VERSION ""

NS_ :

BS_:

BU_: SCM BC1 BC2 ECM PSC ABS Brakes__Drive_Axle_1 EPS IC GPS WCM VCM Seat_Control_1 ISC1 HCU IDT GMRS XM RH AUTON LHC CIM IMU BC3 IC2 EPC1 EPC2 EPC3 EPC4 BMC1 BMC2 APU2 APU1 SRVTOOL RHC RCM

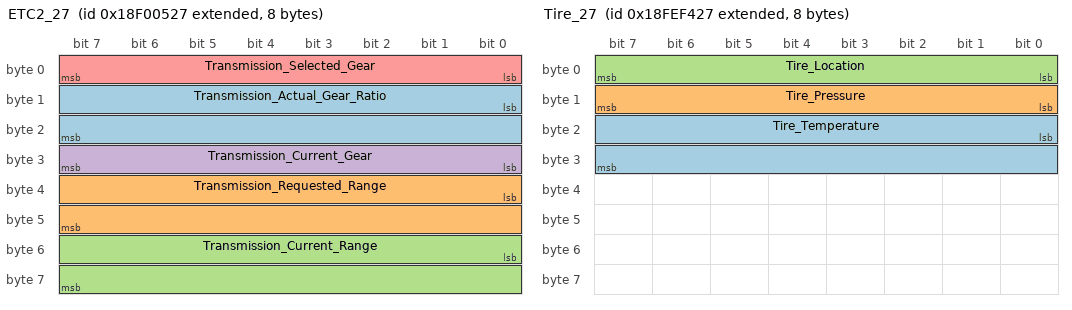
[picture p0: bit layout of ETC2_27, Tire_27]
BO_ 2565866791 ETC2_27: 8 VCM
 SG_ Transmission_Actual_Gear_Ratio : 8|16@1+ (0.001,0) [0|64.536] "Ratio" Vector__XXX
 SG_ Transmission_Requested_Range : 32|16@1+ (0,0) [0|-1] "ASCII" Vector__XXX
 SG_ Transmission_Current_Range : 48|16@1+ (0,0) [0|-1] "ASCII" Vector__XXX
 SG_ Transmission_Current_Gear : 24|8@1+ (1,-125) [-125|380] "gear_value" Vector__XXX
 SG_ Transmission_Selected_Gear : 0|8@1+ (1,-125) [-125|380] "gear_value" Vector__XXX

BO_ 2566834727 DM1_27: 42 VCM
 SG_ Flash_Malfunction_Indicator_Lamp : 14|2@1+ (1,0) [0|3] "" Vector__XXX
 SG_ Malfunction_Indicator_Lamp_Statu : 6|2@1+ (1,0) [0|3] "" Vector__XXX
 SG_ Red_Stop_Lamp_Status : 4|2@1+ (1,0) [0|3] "" Vector__XXX
 SG_ Amber_Warning_Lamp_Status : 2|2@1+ (1,0) [0|3] "" Vector__XXX
 SG_ Flash_Red_Stop_Lamp_RSL : 12|2@1+ (1,0) [0|3] "" Vector__XXX
 SG_ Flash_Amber_Warning_Lamp_AWL : 10|2@1+ (1,0) [0|3] "" Vector__XXX
 SG_ Flash_Protect_Lamp : 8|2@1+ (1,0) [0|3] "" Vector__XXX
 SG_ Protect_Lamp_Status : 0|2@1+ (1,0) [0|3] "" Vector__XXX
 SG_ DTC_1 : 16|32@1+ (1,0) [0|4294967295] "value" Vector__XXX
 SG_ DTC_2 : 48|32@1+ (1,0) [0|4294967295] "value" Vector__XXX
 SG_ DTC_3 : 80|32@1+ (1,0) [0|4294967295] "value" Vector__XXX
 SG_ DTC_4 : 112|32@1+ (1,0) [0|4294967295] "value" Vector__XXX
 SG_ DTC_5 : 144|32@1+ (1,0) [0|4294967295] "value" Vector__XXX
 SG_ DTC_6 : 176|32@1+ (1,0) [0|4294967295] "value" Vector__XXX
 SG_ DTC_7 : 208|32@1+ (1,0) [0|4294967295] "value" Vector__XXX
 SG_ DTC_8 : 240|32@1+ (1,0) [0|4294967295] "value" Vector__XXX
 SG_ DTC_9 : 272|32@1+ (1,0) [0|4294967295] "value" Vector__XXX
 SG_ DTC_10 : 304|32@1+ (1,0) [0|4294967295] "value" Vector__XXX

BO_ 2566845479 Tire_27: 8 VCM
 SG_ Tire_Temperature : 16|16@1+ (0.03125,-273) [-273|2320] "deg C" Vector__XXX
 SG_ Tire_Pressure : 8|8@1+ (4,0) [0|1023] "kPa" Vector__XXX
 SG_ Tire_Location : 0|8@1+ (1,0) [0|255] "bit" Vector__XXX

BO_ 2566844711 CCVS1_27: 8 VCM
 SG_ Cruise_Control_Set_Speed : 40|8@1+ (1,0) [0|255] "km/h" Vector__XXX
 SG_ Cruise_Control_Active : 24|2@1+ (1,0) [0|3] "bit" Vector__XXX
 SG_ Clutch_Switch : 30|2@1+ (1,0) [0|3] "bit" Vector__XXX
 SG_ Brake_Switch : 28|2@1+ (1,0) [0|3] "bit" Vector__XXX
 SG_ pCC_Message_Counter : 52|4@1+ (1,0) [0|15] "count" Vector__XXX
 SG_ Cruise_Control_Pause_Switch : 4|2@1+ (1,0) [0|3] "bit" Vector__XXX
 SG_ Cruise_Control_Set_Switch : 32|2@1+ (1,0) [0|3] "bit" Vector__XXX
 SG_ Two_Speed_Axle_Switch : 0|2@1+ (1,0) [0|3] "bit" Vector__XXX
 SG_ Cruise_Control_Enable_Switch : 26|2@1+ (1,0) [0|3] "bit" Vector__XXX
 SG_ pOdometer_Drive_Bit : 6|2@1+ (1,0) [0|3] "state" Vector__XXX
 SG_ pCC_Checksum : 56|8@1+ (1,0) [0|255] "" Vector__XXX
 SG_ WheelBased_Vehicle_Speed : 8|16@1+ (0.00390625,0) [0|255] "km/h" Vector__XXX
 SG_ Cruise_Control_Resume_Switch : 36|2@1+ (1,0) [0|3] "bit" Vector__XXX
 SG_ Cruise_Control_Accelerate_Switch : 38|2@1+ (1,0) [0|3] "bit" Vector__XXX
 SG_ pCruise_Enable_Status : 48|4@1+ (1,0) [0|15] "state" Vector__XXX
 SG_ Parking_Brake_Switch : 2|2@1+ (1,0) [0|3] "bit" Vector__XXX
 SG_ Cruise_Control_Coast_Decelerate_ : 34|2@1+ (1,0) [0|3] "bit" Vector__XXX

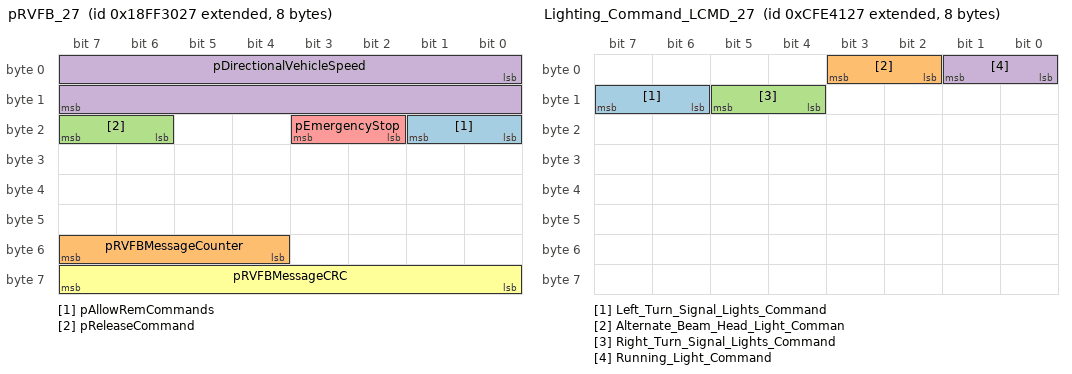
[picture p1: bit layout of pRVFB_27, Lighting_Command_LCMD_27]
BO_ 2566860839 pRVFB_27: 8 VCM
 SG_ pAllowRemCommands : 16|2@1+ (1,0) [0|3] "state" Vector__XXX
 SG_ pRVFBMessageCounter : 52|4@1+ (1,0) [0|15] "count" Vector__XXX
 SG_ pReleaseCommand : 22|2@1+ (1,0) [0|3] "state" Vector__XXX
 SG_ pDirectionalVehicleSpeed : 0|16@1+ (0.0078125,-128) [-128|639] "km/h" Vector__XXX
 SG_ pEmergencyStop : 18|2@1+ (1,0) [0|3] "state" Vector__XXX
 SG_ pRVFBMessageCRC : 56|8@1+ (1,0) [0|255] "" Vector__XXX

BO_ 2365473063 Lighting_Command_LCMD_27: 8 VCM
 SG_ Left_Turn_Signal_Lights_Command : 14|2@1+ (1,0) [0|3] "bit" Vector__XXX
 SG_ Alternate_Beam_Head_Light_Comman : 2|2@1+ (1,0) [0|3] "bit" Vector__XXX
 SG_ Right_Turn_Signal_Lights_Command : 12|2@1+ (1,0) [0|3] "bit" Vector__XXX
 SG_ Running_Light_Command : 0|2@1+ (1,0) [0|3] "bit" Vector__XXX

BO_ 2349465383 SRASI_27: 8 VCM
 SG_ Static_Roll_Angle : 0|8@1+ (1,-125) [-125|380] "deg" Vector__XXX

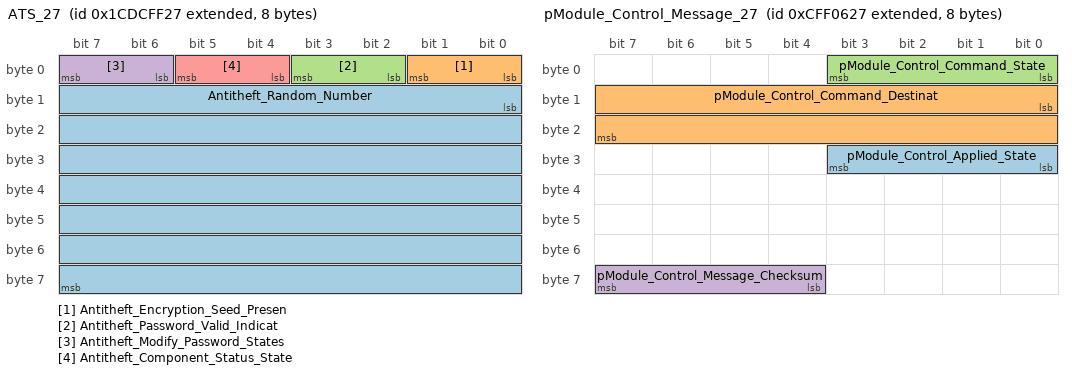
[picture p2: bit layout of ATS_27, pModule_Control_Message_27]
BO_ 2631728935 ATS_27: 8 VCM
 SG_ Antitheft_Random_Number : 8|56@1+ (0,0) [0|-1] "ASCII" Vector__XXX
 SG_ Antitheft_Encryption_Seed_Presen : 0|2@1+ (1,0) [0|3] "bit" Vector__XXX
 SG_ Antitheft_Password_Valid_Indicat : 2|2@1+ (1,0) [0|3] "bit" Vector__XXX
 SG_ Antitheft_Modify_Password_States : 6|2@1+ (1,0) [0|3] "bit" Vector__XXX
 SG_ Antitheft_Component_Status_State : 4|2@1+ (1,0) [0|3] "bit" Vector__XXX

BO_ 2633883431 FWD_27: 8 VCM
 SG_ Front_Wheel_Drive_Actuator_Statu : 0|2@1+ (1,0) [0|3] "bit" Vector__XXX

BO_ 2432656679 pOSS1_27: 8 VCM
 SG_ Key_Fob_Unlock_Button_Status : 30|2@1+ (1,0) [0|3] "state" Vector__XXX
 SG_ Homelink_2 : 44|2@1+ (1,0) [0|3] "state" Vector__XXX
 SG_ Side_Stand_Switch : 56|2@1+ (1,0) [0|3] "state" Vector__XXX
 SG_ Key_Fob_Lock_Button_Status : 32|2@1+ (1,0) [0|3] "state" Vector__XXX
 SG_ Windshield__2_Down : 50|2@1+ (1,0) [0|3] "state" Vector__XXX
 SG_ Turn__3_Cancel : 14|2@1+ (1,0) [0|3] "state" Vector__XXX
 SG_ Reverse : 40|2@1+ (1,0) [0|3] "state" Vector__XXX
 SG_ Hazard : 16|2@1+ (1,0) [0|3] "state" Vector__XXX
 SG_ Homelink_1 : 42|2@1+ (1,0) [0|3] "state" Vector__XXX
 SG_ Windshield__1_Up : 48|2@1+ (1,0) [0|3] "state" Vector__XXX
 SG_ Front_Brake_Switch : 52|2@1+ (1,0) [0|3] "state" Vector__XXX
 SG_ Instrument_Cluster_Control__2 : 2|2@1+ (1,0) [0|3] "state" Vector__XXX
 SG_ Chassis_Unlock_Button_Status : 34|2@1+ (1,0) [0|3] "state" Vector__XXX
 SG_ Power_Button : 58|2@1+ (1,0) [0|3] "state" Vector__XXX
 SG_ RunStop_Switch : 38|2@1+ (1,0) [0|3] "state" Vector__XXX
 SG_ Headlamp__2_High : 6|2@1+ (1,0) [0|3] "state" Vector__XXX
 SG_ Instrument_Cluster_Control__1 : 0|2@1+ (1,0) [0|3] "state" Vector__XXX
 SG_ Clutch_Switch : 54|2@1+ (1,0) [0|3] "state" Vector__XXX
 SG_ Start : 26|2@1+ (1,0) [0|3] "state" Vector__XXX
 SG_ Headlamp__3_Driving : 8|2@1+ (1,0) [0|3] "state" Vector__XXX
 SG_ Cruise__2_Set : 20|2@1+ (1,0) [0|3] "state" Vector__XXX
 SG_ Windshield_Wiper : 36|2@1+ (1,0) [0|3] "state" Vector__XXX
 SG_ Fog : 28|2@1+ (1,0) [0|3] "state" Vector__XXX
 SG_ Cruise__3_Accel : 22|2@1+ (1,0) [0|3] "state" Vector__XXX
 SG_ Horn : 24|2@1+ (1,0) [0|3] "state" Vector__XXX
 SG_ Turn__2_Right : 12|2@1+ (1,0) [0|3] "state" Vector__XXX
 SG_ Cruise__1_On : 18|2@1+ (1,0) [0|3] "state" Vector__XXX
 SG_ Turn__1_Left : 10|2@1+ (1,0) [0|3] "state" Vector__XXX
 SG_ Throttle_Safety_Switch__1 : 46|2@1+ (1,0) [0|3] "state" Vector__XXX
 SG_ Headlamp__1_Low : 4|2@1+ (1,0) [0|3] "state" Vector__XXX
 SG_ Chassis_Lock_Switch_Status : 62|2@1+ (1,0) [0|3] "unknown" Vector__XXX
 SG_ Fuel_Door_Unlock_Button_Status : 60|2@1+ (1,0) [0|3] "state" Vector__XXX

BO_ 2365523495 pModule_Control_Message_27: 8 VCM
 SG_ pModule_Control_Applied_State : 24|4@1+ (1,0) [0|15] "state" Vector__XXX
 SG_ pModule_Control_Command_Destinat : 8|16@1+ (1,0) [0|65535] "count" Vector__XXX
 SG_ pModule_Control_Command_State : 0|4@1+ (1,0) [0|15] "state" Vector__XXX
 SG_ pModule_Control_Message_Checksum : 60|4@1+ (1,0) [0|15] "bit" Vector__XXX

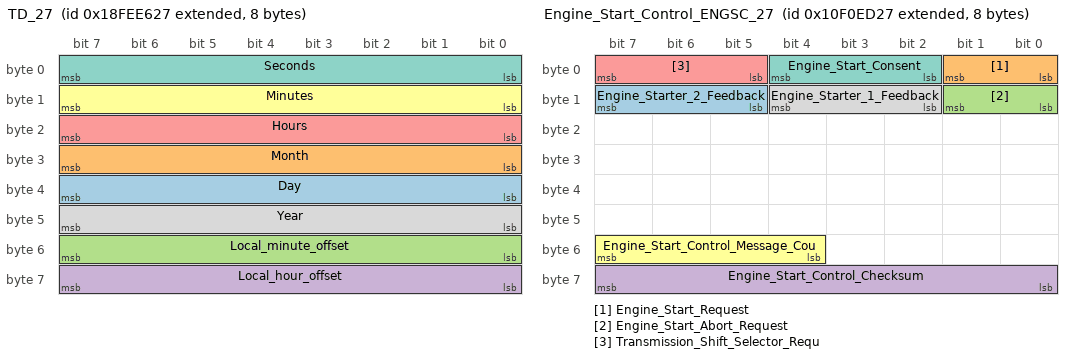
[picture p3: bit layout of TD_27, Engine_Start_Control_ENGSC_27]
BO_ 2566841895 TD_27: 8 VCM
 SG_ Day : 32|8@1+ (0.25,0) [0|63] "days" Vector__XXX
 SG_ Month : 24|8@1+ (1,0) [0|255] "months" Vector__XXX
 SG_ Local_minute_offset : 48|8@1+ (1,-125) [-125|380] "min" Vector__XXX
 SG_ Local_hour_offset : 56|8@1+ (1,-125) [-125|380] "h" Vector__XXX
 SG_ Hours : 16|8@1+ (1,0) [0|255] "h" Vector__XXX
 SG_ Minutes : 8|8@1+ (1,0) [0|255] "min" Vector__XXX
 SG_ Seconds : 0|8@1+ (0.25,0) [0|63] "s" Vector__XXX
 SG_ Year : 40|8@1+ (1,1985) [1985|-1730] "years" Vector__XXX

BO_ 2431708455 Engine_Start_Control_ENGSC_27: 8 VCM
 SG_ Engine_Starter_2_Feedback : 13|3@1+ (1,0) [0|7] "bit" Vector__XXX
 SG_ Engine_Start_Request : 0|2@1+ (1,0) [0|3] "bit" Vector__XXX
 SG_ Engine_Start_Abort_Request : 8|2@1+ (1,0) [0|3] "bit" Vector__XXX
 SG_ Engine_Start_Control_Checksum : 56|8@1+ (1,0) [0|255] "count" Vector__XXX
 SG_ Transmission_Shift_Selector_Requ : 5|3@1+ (1,0) [0|7] "bit" Vector__XXX
 SG_ Engine_Start_Control_Message_Cou : 52|4@1+ (1,0) [0|15] "bit" Vector__XXX
 SG_ Engine_Start_Consent : 2|3@1+ (1,0) [0|7] "bit" Vector__XXX
 SG_ Engine_Starter_1_Feedback : 10|3@1+ (1,0) [0|7] "bit" Vector__XXX

BO_ 2365531175 pVMC_27: 8 VCM
 SG_ pEPSReqMod : 8|8@1+ (1,0) [0|255] "state" Vector__XXX

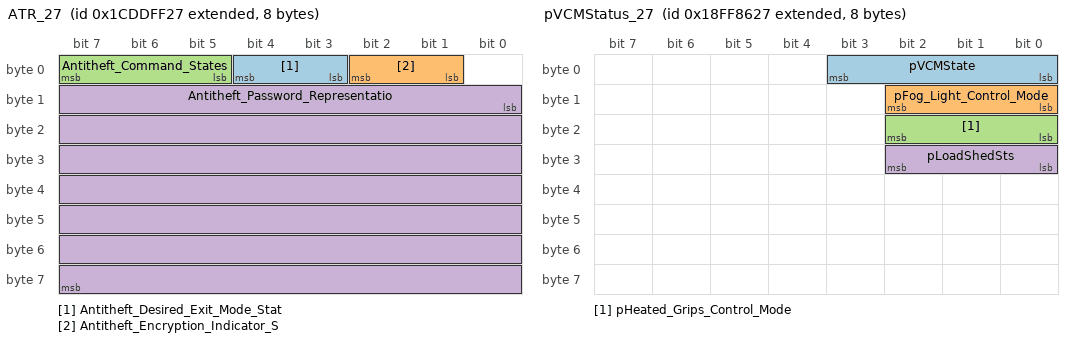
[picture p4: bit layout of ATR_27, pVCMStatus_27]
BO_ 2631794471 ATR_27: 8 VCM
 SG_ Antitheft_Desired_Exit_Mode_Stat : 3|2@1+ (1,0) [0|3] "bit" Vector__XXX
 SG_ Antitheft_Encryption_Indicator_S : 1|2@1+ (1,0) [0|3] "bit" Vector__XXX
 SG_ Antitheft_Command_States : 5|3@1+ (1,0) [0|7] "bit" Vector__XXX
 SG_ Antitheft_Password_Representatio : 8|56@1+ (0,0) [0|-1] "ASCII" Vector__XXX

BO_ 2566882855 pVCMStatus_27: 8 VCM
 SG_ pVCMState : 0|4@1+ (1,0) [0|15] "state" Vector__XXX
 SG_ pFog_Light_Control_Mode : 8|3@1+ (1,0) [0|7] "state" Vector__XXX
 SG_ pHeated_Grips_Control_Mode : 16|3@1+ (1,0) [0|7] "state" Vector__XXX
 SG_ pLoadShedSts : 24|3@1+ (1,0) [0|7] "state" Vector__XXX

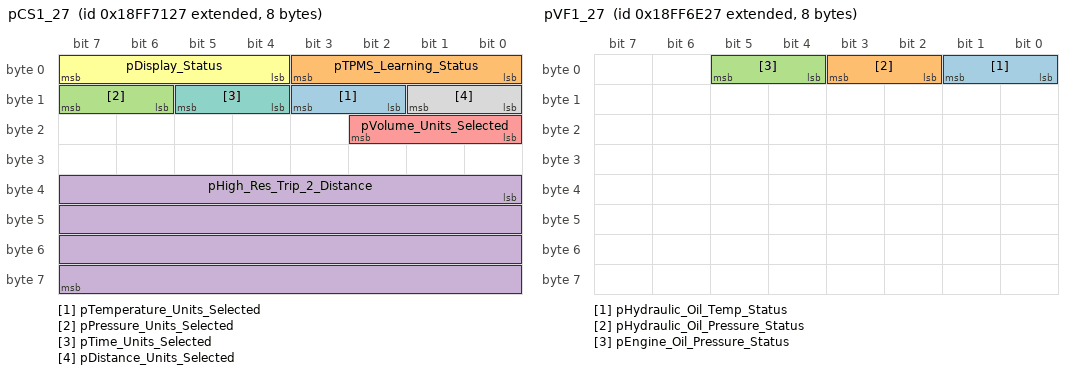
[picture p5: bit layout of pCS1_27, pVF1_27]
BO_ 2566877479 pCS1_27: 8 VCM
 SG_ pTemperature_Units_Selected : 10|2@1+ (1,0) [0|3] "state" Vector__XXX
 SG_ pTPMS_Learning_Status : 0|4@1+ (1,0) [0|15] "state" Vector__XXX
 SG_ pPressure_Units_Selected : 14|2@1+ (1,0) [0|3] "state" Vector__XXX
 SG_ pHigh_Res_Trip_2_Distance : 32|32@1+ (5,0) [0|21474836479] "km" Vector__XXX
 SG_ pVolume_Units_Selected : 16|3@1+ (1,0) [0|7] "state" Vector__XXX
 SG_ pDisplay_Status : 4|4@1+ (1,0) [0|15] "state" Vector__XXX
 SG_ pTime_Units_Selected : 12|2@1+ (1,0) [0|3] "state" Vector__XXX
 SG_ pDistance_Units_Selected : 8|2@1+ (1,0) [0|3] "state" Vector__XXX

BO_ 2633984551 pDSS_27: 8 VCM
 SG_ pHeated_Grip_Enable : 48|2@1+ (1,0) [0|3] "state" Vector__XXX
 SG_ pUser_PIN_Access_Status : 26|2@1+ (1,0) [0|3] "state" Vector__XXX
 SG_ pActive_Descent_Control_ADC_Stat : 0|2@1+ (1,0) [0|3] "state" Vector__XXX
 SG_ pCruise_Control_Set_Status : 24|2@1+ (1,0) [0|3] "state" Vector__XXX
 SG_ pTether_Switch_Status : 46|2@1+ (1,0) [0|3] "state" Vector__XXX
 SG_ pHigh_Beam_Indicator_Status : 8|2@1+ (1,0) [0|3] "state" Vector__XXX
 SG_ pLow_Fuel_Indicator_Status : 10|2@1+ (1,0) [0|3] "state" Vector__XXX
 SG_ pHeated_Grips_Percentage : 16|8@1+ (0.4,0) [0|101.4] "%" Vector__XXX
 SG_ pSide_Stand_Status : 36|2@1+ (1,0) [0|3] "state" Vector__XXX
 SG_ pTurf_Mode_Requested : 28|2@1+ (1,0) [0|3] "state" Vector__XXX
 SG_ pEngine_Idle_Shutdown_Timer : 54|10@1+ (1,0) [0|1023] "state" Vector__XXX
 SG_ Operator_Not_in_Operating_Statio : 38|2@1+ (1,0) [0|3] "state" Vector__XXX
 SG_ pAWD_Mode_Requested : 32|2@1+ (1,0) [0|3] "state" Vector__XXX
 SG_ pHeated_Grips_Up_Switch_Status : 50|2@1+ (1,0) [0|3] "state" Vector__XXX
 SG_ pTreadle_Neutral_Status : 2|2@1+ (1,0) [0|3] "state" Vector__XXX
 SG_ pHeated_Grips_Down_Switch_Status : 52|2@1+ (1,0) [0|3] "state" Vector__XXX
 SG_ pPark_Brake_Indicator_Status : 40|3@1+ (1,0) [0|7] "state" Vector__XXX
 SG_ pRWD_Mode_Requested : 30|2@1+ (1,0) [0|3] "state" Vector__XXX
 SG_ pSeat_Belt_Indicator_Status : 12|3@1+ (1,0) [0|7] "state" Vector__XXX
 SG_ pSecurity_Light_Immobilizer_Stat : 6|2@1+ (1,0) [0|3] "state" Vector__XXX
 SG_ ECU_Security_Status : 43|3@1+ (1,0) [0|7] "state" Vector__XXX
 SG_ pActive_Decent_Control_ADC_Mode_ : 34|2@1+ (1,0) [0|3] "state" Vector__XXX
 SG_ pTreadle_Reverse_Status : 4|2@1+ (1,0) [0|3] "state" Vector__XXX

BO_ 2566876711 pVF1_27: 8 VCM
 SG_ pHydraulic_Oil_Temp_Status : 0|2@1+ (1,0) [0|3] "state" Vector__XXX
 SG_ pHydraulic_Oil_Pressure_Status : 2|2@1+ (1,0) [0|3] "state" Vector__XXX
 SG_ pEngine_Oil_Pressure_Status : 4|2@1+ (1,0) [0|3] "state" Vector__XXX

BO_ 2566834735 DM1_2F: 42 SCM
 SG_ Flash_Malfunction_Indicator_Lamp : 14|2@1+ (1,0) [0|3] "" Vector__XXX
 SG_ Malfunction_Indicator_Lamp_Statu : 6|2@1+ (1,0) [0|3] "" Vector__XXX
 SG_ Red_Stop_Lamp_Status : 4|2@1+ (1,0) [0|3] "" Vector__XXX
 SG_ Amber_Warning_Lamp_Status : 2|2@1+ (1,0) [0|3] "" Vector__XXX
 SG_ Flash_Red_Stop_Lamp_RSL : 12|2@1+ (1,0) [0|3] "" Vector__XXX
 SG_ Flash_Amber_Warning_Lamp_AWL : 10|2@1+ (1,0) [0|3] "" Vector__XXX
 SG_ Flash_Protect_Lamp : 8|2@1+ (1,0) [0|3] "" Vector__XXX
 SG_ Protect_Lamp_Status : 0|2@1+ (1,0) [0|3] "" Vector__XXX
 SG_ DTC_1 : 16|32@1+ (1,0) [0|4294967295] "value" Vector__XXX
 SG_ DTC_2 : 48|32@1+ (1,0) [0|4294967295] "value" Vector__XXX
 SG_ DTC_3 : 80|32@1+ (1,0) [0|4294967295] "value" Vector__XXX
 SG_ DTC_4 : 112|32@1+ (1,0) [0|4294967295] "value" Vector__XXX
 SG_ DTC_5 : 144|32@1+ (1,0) [0|4294967295] "value" Vector__XXX
 SG_ DTC_6 : 176|32@1+ (1,0) [0|4294967295] "value" Vector__XXX
 SG_ DTC_7 : 208|32@1+ (1,0) [0|4294967295] "value" Vector__XXX
 SG_ DTC_8 : 240|32@1+ (1,0) [0|4294967295] "value" Vector__XXX
 SG_ DTC_9 : 272|32@1+ (1,0) [0|4294967295] "value" Vector__XXX
 SG_ DTC_10 : 304|32@1+ (1,0) [0|4294967295] "value" Vector__XXX

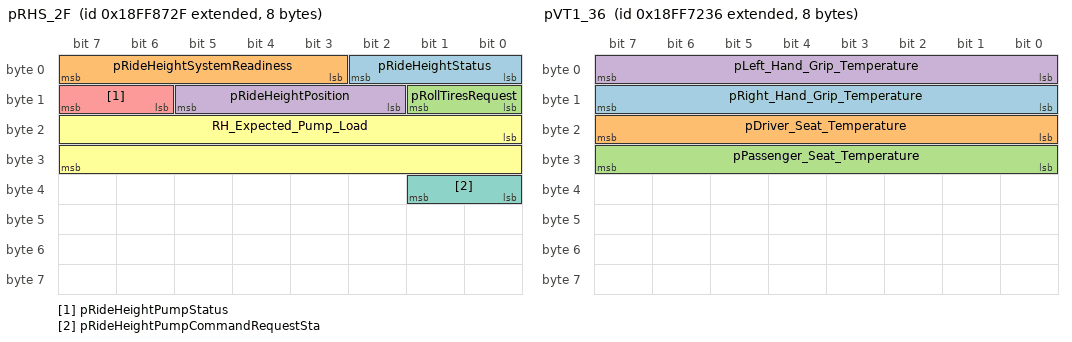
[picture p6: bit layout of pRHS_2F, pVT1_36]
BO_ 2566883119 pRHS_2F: 8 SCM
 SG_ pRideHeightStatus : 0|3@1+ (1,0) [0|7] "state" Vector__XXX
 SG_ pRideHeightSystemReadiness : 3|5@1+ (1,0) [0|31] "state" Vector__XXX
 SG_ pRollTiresRequest : 8|2@1+ (1,0) [0|3] "state" Vector__XXX
 SG_ pRideHeightPosition : 10|4@1+ (1,0) [0|15] "state" Vector__XXX
 SG_ pRideHeightPumpStatus : 14|2@1+ (1,0) [0|3] "state" Vector__XXX
 SG_ RH_Expected_Pump_Load : 16|16@1+ (1,0) [0|65535] "" Vector__XXX
 SG_ pRideHeightPumpCommandRequestSta : 32|2@1+ (1,0) [0|3] "state" Vector__XXX

BO_ 2566834742 DM1_36: 42 Seat_Control_1
 SG_ Flash_Malfunction_Indicator_Lamp : 14|2@1+ (1,0) [0|3] "" Vector__XXX
 SG_ Malfunction_Indicator_Lamp_Statu : 6|2@1+ (1,0) [0|3] "" Vector__XXX
 SG_ Red_Stop_Lamp_Status : 4|2@1+ (1,0) [0|3] "" Vector__XXX
 SG_ Amber_Warning_Lamp_Status : 2|2@1+ (1,0) [0|3] "" Vector__XXX
 SG_ Flash_Red_Stop_Lamp_RSL : 12|2@1+ (1,0) [0|3] "" Vector__XXX
 SG_ Flash_Amber_Warning_Lamp_AWL : 10|2@1+ (1,0) [0|3] "" Vector__XXX
 SG_ Flash_Protect_Lamp : 8|2@1+ (1,0) [0|3] "" Vector__XXX
 SG_ Protect_Lamp_Status : 0|2@1+ (1,0) [0|3] "" Vector__XXX
 SG_ DTC_1 : 16|32@1+ (1,0) [0|4294967295] "value" Vector__XXX
 SG_ DTC_2 : 48|32@1+ (1,0) [0|4294967295] "value" Vector__XXX
 SG_ DTC_3 : 80|32@1+ (1,0) [0|4294967295] "value" Vector__XXX
 SG_ DTC_4 : 112|32@1+ (1,0) [0|4294967295] "value" Vector__XXX
 SG_ DTC_5 : 144|32@1+ (1,0) [0|4294967295] "value" Vector__XXX
 SG_ DTC_6 : 176|32@1+ (1,0) [0|4294967295] "value" Vector__XXX
 SG_ DTC_7 : 208|32@1+ (1,0) [0|4294967295] "value" Vector__XXX
 SG_ DTC_8 : 240|32@1+ (1,0) [0|4294967295] "value" Vector__XXX
 SG_ DTC_9 : 272|32@1+ (1,0) [0|4294967295] "value" Vector__XXX
 SG_ DTC_10 : 304|32@1+ (1,0) [0|4294967295] "value" Vector__XXX

BO_ 2566877750 pVT1_36: 8 Seat_Control_1
 SG_ pRight_Hand_Grip_Temperature : 8|8@1+ (1,-40) [-40|295] "deg C" Vector__XXX
 SG_ pDriver_Seat_Temperature : 16|8@1+ (1,-40) [-40|295] "deg C" Vector__XXX
 SG_ pPassenger_Seat_Temperature : 24|8@1+ (1,-40) [-40|295] "deg C" Vector__XXX
 SG_ pLeft_Hand_Grip_Temperature : 0|8@1+ (1,-40) [-40|295] "deg C" Vector__XXX

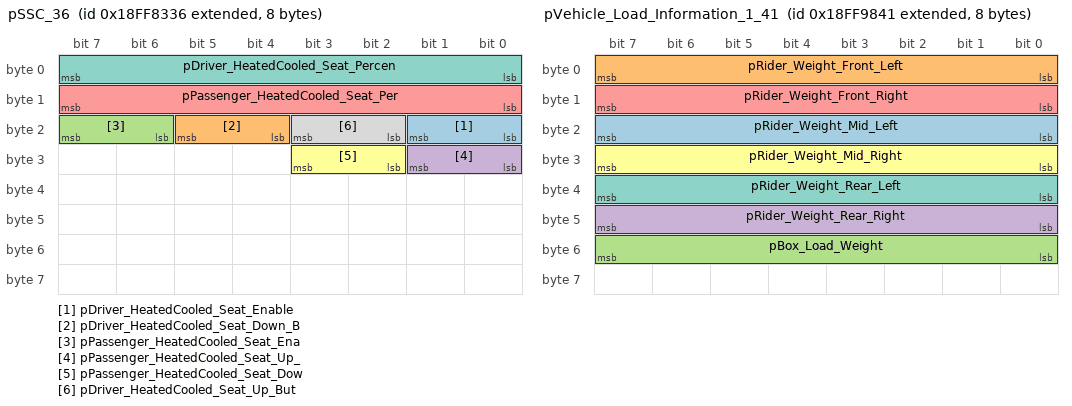
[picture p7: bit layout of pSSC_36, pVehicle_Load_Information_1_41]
BO_ 2566882102 pSSC_36: 8 Seat_Control_1
 SG_ pDriver_HeatedCooled_Seat_Enable : 16|2@1+ (1,0) [0|3] "state" Vector__XXX
 SG_ pDriver_HeatedCooled_Seat_Down_B : 20|2@1+ (1,0) [0|3] "state" Vector__XXX
 SG_ pPassenger_HeatedCooled_Seat_Ena : 22|2@1+ (1,0) [0|3] "state" Vector__XXX
 SG_ pPassenger_HeatedCooled_Seat_Up_ : 24|2@1+ (1,0) [0|3] "state" Vector__XXX
 SG_ pPassenger_HeatedCooled_Seat_Per : 8|8@1+ (0.8,-100) [-100|303.8] "%" Vector__XXX
 SG_ pPassenger_HeatedCooled_Seat_Dow : 26|2@1+ (1,0) [0|3] "state" Vector__XXX
 SG_ pDriver_HeatedCooled_Seat_Percen : 0|8@1+ (0.8,-100) [-100|303.8] "%" Vector__XXX
 SG_ pDriver_HeatedCooled_Seat_Up_But : 18|2@1+ (1,0) [0|3] "state" Vector__XXX

BO_ 2432658497 pOSS2_41: 8 ISC1
 SG_ pFOCC_Checksum : 56|8@1+ (1,0) [0|255] "" Vector__XXX
 SG_ Drive_Mode__4 : 6|2@1+ (1,0) [0|3] "state" Vector__XXX
 SG_ Drive_Mode__2 : 2|2@1+ (1,0) [0|3] "state" Vector__XXX
 SG_ pFOCC_Message_Counter : 48|4@1+ (1,0) [0|15] "" Vector__XXX
 SG_ Drivers_Net_Engagement : 12|2@1+ (1,0) [0|3] "state" Vector__XXX
 SG_ Foot_On_Cruise_Control_Switch : 22|2@1+ (1,0) [0|3] "state" Vector__XXX
 SG_ Drive_Mode__1 : 0|2@1+ (1,0) [0|3] "state" Vector__XXX
 SG_ Momentary_Driveline_Left_Press : 24|2@1+ (1,0) [0|3] "state" Vector__XXX
 SG_ CylDeAc_Enable : 32|2@1+ (1,0) [0|3] "state" Vector__XXX
 SG_ Work_Group_Lock_Switch : 16|2@1+ (1,0) [0|3] "state" Vector__XXX
 SG_ Drivers_Seatbelt_Engagement : 10|2@1+ (1,0) [0|3] "state" Vector__XXX
 SG_ Drive_Mode__3 : 4|2@1+ (1,0) [0|3] "state" Vector__XXX
 SG_ Work_Mode_Switch : 20|2@1+ (1,0) [0|3] "state" Vector__XXX
 SG_ Momentary_Driveline_Right_Press : 26|2@1+ (1,0) [0|3] "state" Vector__XXX
 SG_ PTO_Mode_Switch_RPM_Control : 8|2@1+ (1,0) [0|3] "state" Vector__XXX
 SG_ Operator_Presence_Switch : 18|2@1+ (1,0) [0|3] "state" Vector__XXX
 SG_ Tilt_Lock_Switch : 14|2@1+ (1,0) [0|3] "state" Vector__XXX
 SG_ Engine_Brake_Enable : 34|2@1+ (1,0) [0|3] "state" Vector__XXX
 SG_ Accessory_Relay : 28|2@1+ (1,0) [0|3] "state" Vector__XXX

BO_ 2566887489 pVehicle_Load_Information_1_41: 8 ISC1
 SG_ pRider_Weight_Mid_Left : 16|8@1+ (1,0) [0|255] "kg" Vector__XXX
 SG_ pRider_Weight_Front_Left : 0|8@1+ (1,0) [0|255] "kg" Vector__XXX
 SG_ pBox_Load_Weight : 48|8@1+ (10,0) [0|2559] "kg" Vector__XXX
 SG_ pRider_Weight_Rear_Right : 40|8@1+ (1,0) [0|255] "kg" Vector__XXX
 SG_ pRider_Weight_Front_Right : 8|8@1+ (1,0) [0|255] "kg" Vector__XXX
 SG_ pRider_Weight_Mid_Right : 24|8@1+ (1,0) [0|255] "kg" Vector__XXX
 SG_ pRider_Weight_Rear_Left : 32|8@1+ (1,0) [0|255] "kg" Vector__XXX

BO_ 2566834753 DM1_41: 42 ISC1
 SG_ Flash_Malfunction_Indicator_Lamp : 14|2@1+ (1,0) [0|3] "" Vector__XXX
 SG_ Malfunction_Indicator_Lamp_Statu : 6|2@1+ (1,0) [0|3] "" Vector__XXX
 SG_ Red_Stop_Lamp_Status : 4|2@1+ (1,0) [0|3] "" Vector__XXX
 SG_ Amber_Warning_Lamp_Status : 2|2@1+ (1,0) [0|3] "" Vector__XXX
 SG_ Flash_Red_Stop_Lamp_RSL : 12|2@1+ (1,0) [0|3] "" Vector__XXX
 SG_ Flash_Amber_Warning_Lamp_AWL : 10|2@1+ (1,0) [0|3] "" Vector__XXX
 SG_ Flash_Protect_Lamp : 8|2@1+ (1,0) [0|3] "" Vector__XXX
 SG_ Protect_Lamp_Status : 0|2@1+ (1,0) [0|3] "" Vector__XXX
 SG_ DTC_1 : 16|32@1+ (1,0) [0|4294967295] "value" Vector__XXX
 SG_ DTC_2 : 48|32@1+ (1,0) [0|4294967295] "value" Vector__XXX
 SG_ DTC_3 : 80|32@1+ (1,0) [0|4294967295] "value" Vector__XXX
 SG_ DTC_4 : 112|32@1+ (1,0) [0|4294967295] "value" Vector__XXX
 SG_ DTC_5 : 144|32@1+ (1,0) [0|4294967295] "value" Vector__XXX
 SG_ DTC_6 : 176|32@1+ (1,0) [0|4294967295] "value" Vector__XXX
 SG_ DTC_7 : 208|32@1+ (1,0) [0|4294967295] "value" Vector__XXX
 SG_ DTC_8 : 240|32@1+ (1,0) [0|4294967295] "value" Vector__XXX
 SG_ DTC_9 : 272|32@1+ (1,0) [0|4294967295] "value" Vector__XXX
 SG_ DTC_10 : 304|32@1+ (1,0) [0|4294967295] "value" Vector__XXX

BO_ 2432656449 pISC_41: 8 ISC1
 SG_ Source : 8|2@1+ (1,0) [0|3] "state" Vector__XXX
 SG_ Squelch_SQ_Up : 18|2@1+ (1,0) [0|3] "state" Vector__XXX
 SG_ MutePreset : 10|2@1+ (1,0) [0|3] "state" Vector__XXX
 SG_ Volume_Down : 0|2@1+ (1,0) [0|3] "state" Vector__XXX
 SG_ Volume_Up : 2|2@1+ (1,0) [0|3] "state" Vector__XXX
 SG_ Tune_Up : 6|2@1+ (1,0) [0|3] "state" Vector__XXX
 SG_ Seek_Up : 42|2@1+ (1,0) [0|3] "state" Vector__XXX
 SG_ Tune_Down : 4|2@1+ (1,0) [0|3] "state" Vector__XXX
 SG_ Squelch_SQ_Down : 16|2@1+ (1,0) [0|3] "state" Vector__XXX
 SG_ pInfotainment_Joystick_1 : 24|4@1+ (1,0) [0|15] "state" Vector__XXX
 SG_ Preset : 22|2@1+ (1,0) [0|3] "state" Vector__XXX
 SG_ Seek_Down : 44|2@1+ (1,0) [0|3] "state" Vector__XXX
 SG_ pInfotainment_Joystick_2 : 32|4@1+ (1,0) [0|15] "state" Vector__XXX
 SG_ ICOM : 12|2@1+ (1,0) [0|3] "state" Vector__XXX
 SG_ Push_To_Talk_PTT : 20|2@1+ (1,0) [0|3] "state" Vector__XXX
 SG_ pMultifunction_Infotainment_Inte : 46|2@1+ (1,0) [0|3] "state" Vector__XXX
 SG_ COM : 14|2@1+ (1,0) [0|3] "state" Vector__XXX
 SG_ PlayPause : 40|2@1+ (1,0) [0|3] "state" Vector__XXX

BO_ 2566832449 VDHR_41: 8 ISC1
 SG_ Total_Vehicle_Distance_High_Reso : 0|32@1+ (5,0) [0|21474836479] "m" Vector__XXX
 SG_ Trip_Distance_High_Resolution : 0|32@1+ (5,0) [0|21474836479] "m" Vector__XXX

BO_ 2432656705 pOSS1_41: 8 ISC1
 SG_ Key_Fob_Unlock_Button_Status : 30|2@1+ (1,0) [0|3] "state" Vector__XXX
 SG_ Homelink_2 : 44|2@1+ (1,0) [0|3] "state" Vector__XXX
 SG_ Side_Stand_Switch : 56|2@1+ (1,0) [0|3] "state" Vector__XXX
 SG_ Key_Fob_Lock_Button_Status : 32|2@1+ (1,0) [0|3] "state" Vector__XXX
 SG_ Windshield__2_Down : 50|2@1+ (1,0) [0|3] "state" Vector__XXX
 SG_ Turn__3_Cancel : 14|2@1+ (1,0) [0|3] "state" Vector__XXX
 SG_ Reverse : 40|2@1+ (1,0) [0|3] "state" Vector__XXX
 SG_ Hazard : 16|2@1+ (1,0) [0|3] "state" Vector__XXX
 SG_ Homelink_1 : 42|2@1+ (1,0) [0|3] "state" Vector__XXX
 SG_ Windshield__1_Up : 48|2@1+ (1,0) [0|3] "state" Vector__XXX
 SG_ Front_Brake_Switch : 52|2@1+ (1,0) [0|3] "state" Vector__XXX
 SG_ Instrument_Cluster_Control__2 : 2|2@1+ (1,0) [0|3] "state" Vector__XXX
 SG_ Chassis_Unlock_Button_Status : 34|2@1+ (1,0) [0|3] "state" Vector__XXX
 SG_ Power_Button : 58|2@1+ (1,0) [0|3] "state" Vector__XXX
 SG_ RunStop_Switch : 38|2@1+ (1,0) [0|3] "state" Vector__XXX
 SG_ Headlamp__2_High : 6|2@1+ (1,0) [0|3] "state" Vector__XXX
 SG_ Instrument_Cluster_Control__1 : 0|2@1+ (1,0) [0|3] "state" Vector__XXX
 SG_ Clutch_Switch : 54|2@1+ (1,0) [0|3] "state" Vector__XXX
 SG_ Start : 26|2@1+ (1,0) [0|3] "state" Vector__XXX
 SG_ Headlamp__3_Driving : 8|2@1+ (1,0) [0|3] "state" Vector__XXX
 SG_ Cruise__2_Set : 20|2@1+ (1,0) [0|3] "state" Vector__XXX
 SG_ Windshield_Wiper : 36|2@1+ (1,0) [0|3] "state" Vector__XXX
 SG_ Fog : 28|2@1+ (1,0) [0|3] "state" Vector__XXX
 SG_ Cruise__3_Accel : 22|2@1+ (1,0) [0|3] "state" Vector__XXX
 SG_ Horn : 24|2@1+ (1,0) [0|3] "state" Vector__XXX
 SG_ Turn__2_Right : 12|2@1+ (1,0) [0|3] "state" Vector__XXX
 SG_ Cruise__1_On : 18|2@1+ (1,0) [0|3] "state" Vector__XXX
 SG_ Turn__1_Left : 10|2@1+ (1,0) [0|3] "state" Vector__XXX
 SG_ Throttle_Safety_Switch__1 : 46|2@1+ (1,0) [0|3] "state" Vector__XXX
 SG_ Headlamp__1_Low : 4|2@1+ (1,0) [0|3] "state" Vector__XXX
 SG_ Chassis_Lock_Switch_Status : 62|2@1+ (1,0) [0|3] "unknown" Vector__XXX
 SG_ Fuel_Door_Unlock_Button_Status : 60|2@1+ (1,0) [0|3] "state" Vector__XXX

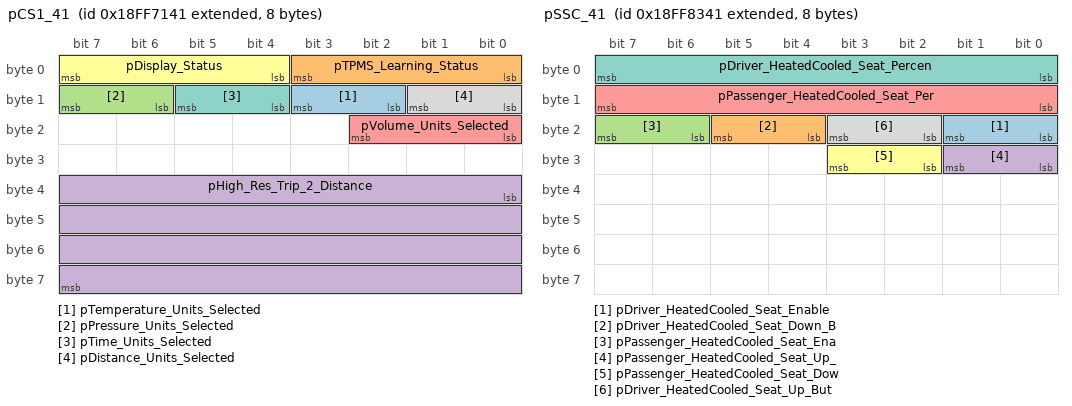
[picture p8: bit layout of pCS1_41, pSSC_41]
BO_ 2566877505 pCS1_41: 8 ISC1
 SG_ pTemperature_Units_Selected : 10|2@1+ (1,0) [0|3] "state" Vector__XXX
 SG_ pTPMS_Learning_Status : 0|4@1+ (1,0) [0|15] "state" Vector__XXX
 SG_ pPressure_Units_Selected : 14|2@1+ (1,0) [0|3] "state" Vector__XXX
 SG_ pHigh_Res_Trip_2_Distance : 32|32@1+ (5,0) [0|21474836479] "km" Vector__XXX
 SG_ pVolume_Units_Selected : 16|3@1+ (1,0) [0|7] "state" Vector__XXX
 SG_ pDisplay_Status : 4|4@1+ (1,0) [0|15] "state" Vector__XXX
 SG_ pTime_Units_Selected : 12|2@1+ (1,0) [0|3] "state" Vector__XXX
 SG_ pDistance_Units_Selected : 8|2@1+ (1,0) [0|3] "state" Vector__XXX

BO_ 2566882113 pSSC_41: 8 ISC1
 SG_ pDriver_HeatedCooled_Seat_Enable : 16|2@1+ (1,0) [0|3] "state" Vector__XXX
 SG_ pDriver_HeatedCooled_Seat_Down_B : 20|2@1+ (1,0) [0|3] "state" Vector__XXX
 SG_ pPassenger_HeatedCooled_Seat_Ena : 22|2@1+ (1,0) [0|3] "state" Vector__XXX
 SG_ pPassenger_HeatedCooled_Seat_Up_ : 24|2@1+ (1,0) [0|3] "state" Vector__XXX
 SG_ pPassenger_HeatedCooled_Seat_Per : 8|8@1+ (0.8,-100) [-100|303.8] "%" Vector__XXX
 SG_ pPassenger_HeatedCooled_Seat_Dow : 26|2@1+ (1,0) [0|3] "state" Vector__XXX
 SG_ pDriver_HeatedCooled_Seat_Percen : 0|8@1+ (0.8,-100) [-100|303.8] "%" Vector__XXX
 SG_ pDriver_HeatedCooled_Seat_Up_But : 18|2@1+ (1,0) [0|3] "state" Vector__XXX

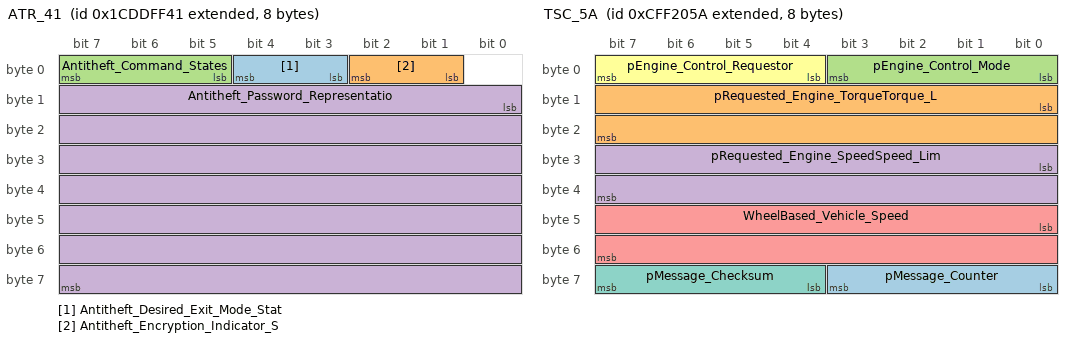
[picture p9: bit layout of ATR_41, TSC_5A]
BO_ 2631794497 ATR_41: 8 ISC1
 SG_ Antitheft_Desired_Exit_Mode_Stat : 3|2@1+ (1,0) [0|3] "bit" Vector__XXX
 SG_ Antitheft_Encryption_Indicator_S : 1|2@1+ (1,0) [0|3] "bit" Vector__XXX
 SG_ Antitheft_Command_States : 5|3@1+ (1,0) [0|7] "bit" Vector__XXX
 SG_ Antitheft_Password_Representatio : 8|56@1+ (0,0) [0|-1] "ASCII" Vector__XXX

BO_ 2365530202 TSC_5A: 8 HCU
 SG_ pMessage_Counter : 56|4@1+ (1,0) [0|15] "count" Vector__XXX
 SG_ pRequested_Engine_TorqueTorque_L : 8|16@1+ (0.03125,-400) [-400|2447] "Nm" Vector__XXX
 SG_ pEngine_Control_Mode : 0|4@1+ (1,0) [0|15] "state" Vector__XXX
 SG_ pRequested_Engine_SpeedSpeed_Lim : 24|16@1+ (1,0) [0|65535] "rpm" Vector__XXX
 SG_ WheelBased_Vehicle_Speed : 40|16@1+ (0.00390625,0) [0|255] "km/h" Vector__XXX
 SG_ pEngine_Control_Requestor : 4|4@1+ (1,0) [0|15] "state" Vector__XXX
 SG_ pMessage_Checksum : 60|4@1+ (1,0) [0|15] "count" Vector__XXX

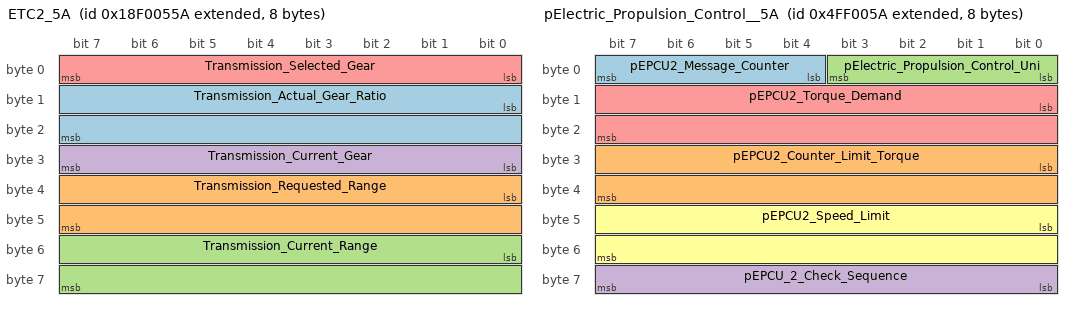
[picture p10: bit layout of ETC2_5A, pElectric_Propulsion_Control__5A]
BO_ 2565866842 ETC2_5A: 8 HCU
 SG_ Transmission_Actual_Gear_Ratio : 8|16@1+ (0.001,0) [0|64.536] "Ratio" Vector__XXX
 SG_ Transmission_Requested_Range : 32|16@1+ (0,0) [0|-1] "ASCII" Vector__XXX
 SG_ Transmission_Current_Range : 48|16@1+ (0,0) [0|-1] "ASCII" Vector__XXX
 SG_ Transmission_Current_Gear : 24|8@1+ (1,-125) [-125|380] "gear_value" Vector__XXX
 SG_ Transmission_Selected_Gear : 0|8@1+ (1,-125) [-125|380] "gear_value" Vector__XXX

BO_ 2231304282 pElectric_Propulsion_Control__5A: 8 HCU
 SG_ pEPCU2_Message_Counter : 4|4@1+ (1,0) [0|15] "count" Vector__XXX
 SG_ pEPCU2_Counter_Limit_Torque : 24|16@1+ (0.1,-3276.8) [-3276.8|9829.4] "Nm" Vector__XXX
 SG_ pElectric_Propulsion_Control_Uni : 0|4@1+ (1,0) [0|15] "state" Vector__XXX
 SG_ pEPCU_2_Check_Sequence : 56|8@1+ (1,0) [0|255] "" Vector__XXX
 SG_ pEPCU2_Torque_Demand : 8|16@1+ (0.1,-3276.8) [-3276.8|9829.4] "Nm" Vector__XXX
 SG_ pEPCU2_Speed_Limit : 40|16@1+ (1,-32768) [-32768|98303] "rpm" Vector__XXX

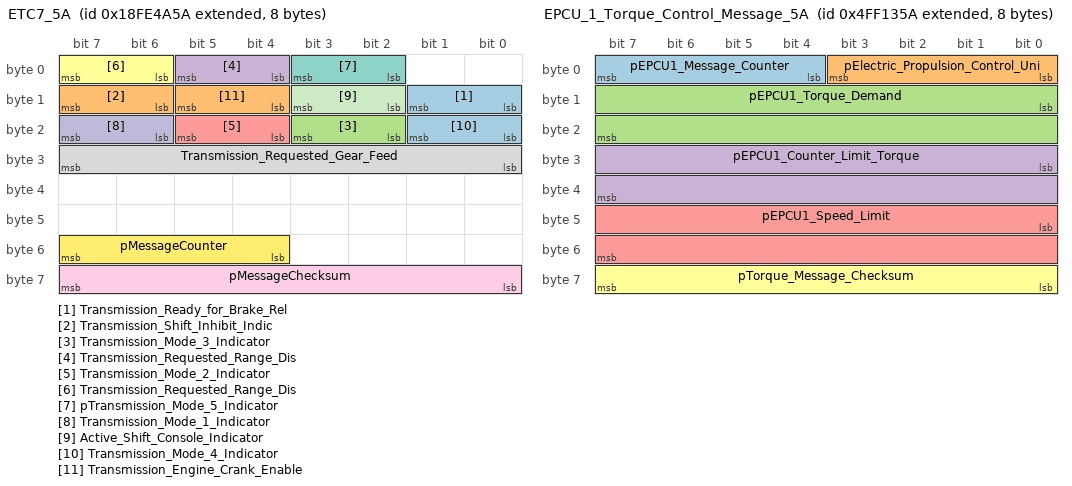
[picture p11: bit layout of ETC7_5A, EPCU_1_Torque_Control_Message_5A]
BO_ 2566802010 ETC7_5A: 8 HCU
 SG_ Transmission_Ready_for_Brake_Rel : 8|2@1+ (1,0) [0|3] "bit" Vector__XXX
 SG_ Transmission_Shift_Inhibit_Indic : 14|2@1+ (1,0) [0|3] "bit" Vector__XXX
 SG_ Transmission_Mode_3_Indicator : 18|2@1+ (1,0) [0|3] "bit" Vector__XXX
 SG_ Transmission_Requested_Range_Dis : 4|2@1+ (1,0) [0|3] "bit" Vector__XXX
 SG_ Transmission_Mode_2_Indicator : 20|2@1+ (1,0) [0|3] "bit" Vector__XXX
 SG_ Transmission_Requested_Range_Dis : 6|2@1+ (1,0) [0|3] "bit" Vector__XXX
 SG_ pTransmission_Mode_5_Indicator : 2|2@1+ (1,0) [0|3] "state" Vector__XXX
 SG_ Transmission_Requested_Gear_Feed : 24|8@1+ (1,-125) [-125|380] "gear_value" Vector__XXX
 SG_ pMessageChecksum : 56|8@1+ (1,0) [0|255] "count" Vector__XXX
 SG_ Transmission_Mode_1_Indicator : 22|2@1+ (1,0) [0|3] "bit" Vector__XXX
 SG_ Active_Shift_Console_Indicator : 10|2@1+ (1,0) [0|3] "bit" Vector__XXX
 SG_ pMessageCounter : 52|4@1+ (1,0) [0|15] "count" Vector__XXX
 SG_ Transmission_Mode_4_Indicator : 16|2@1+ (1,0) [0|3] "bit" Vector__XXX
 SG_ Transmission_Engine_Crank_Enable : 12|2@1+ (1,0) [0|3] "bit" Vector__XXX

BO_ 2231309146 EPCU_1_Torque_Control_Message_5A: 8 HCU
 SG_ pEPCU1_Message_Counter : 4|4@1+ (1,0) [0|15] "count" Vector__XXX
 SG_ pElectric_Propulsion_Control_Uni : 0|4@1+ (1,0) [0|15] "state" Vector__XXX
 SG_ pEPCU1_Torque_Demand : 8|16@1+ (0.1,-3276.8) [-3276.8|9829.4] "Nm" Vector__XXX
 SG_ pEPCU1_Counter_Limit_Torque : 24|16@1+ (0.1,-3276.8) [-3276.8|9829.4] "Nm" Vector__XXX
 SG_ pEPCU1_Speed_Limit : 40|16@1+ (1,-32768) [-32768|98303] "rpm" Vector__XXX
 SG_ pTorque_Message_Checksum : 56|8@1+ (1,0) [0|255] "" Vector__XXX

BO_ 2566844762 CCVS1_5A: 8 HCU
 SG_ Cruise_Control_Set_Speed : 40|8@1+ (1,0) [0|255] "km/h" Vector__XXX
 SG_ Cruise_Control_Active : 24|2@1+ (1,0) [0|3] "bit" Vector__XXX
 SG_ Clutch_Switch : 30|2@1+ (1,0) [0|3] "bit" Vector__XXX
 SG_ Brake_Switch : 28|2@1+ (1,0) [0|3] "bit" Vector__XXX
 SG_ pCC_Message_Counter : 52|4@1+ (1,0) [0|15] "count" Vector__XXX
 SG_ Cruise_Control_Pause_Switch : 4|2@1+ (1,0) [0|3] "bit" Vector__XXX
 SG_ Cruise_Control_Set_Switch : 32|2@1+ (1,0) [0|3] "bit" Vector__XXX
 SG_ Two_Speed_Axle_Switch : 0|2@1+ (1,0) [0|3] "bit" Vector__XXX
 SG_ Cruise_Control_Enable_Switch : 26|2@1+ (1,0) [0|3] "bit" Vector__XXX
 SG_ pOdometer_Drive_Bit : 6|2@1+ (1,0) [0|3] "state" Vector__XXX
 SG_ pCC_Checksum : 56|8@1+ (1,0) [0|255] "" Vector__XXX
 SG_ WheelBased_Vehicle_Speed : 8|16@1+ (0.00390625,0) [0|255] "km/h" Vector__XXX
 SG_ Cruise_Control_Resume_Switch : 36|2@1+ (1,0) [0|3] "bit" Vector__XXX
 SG_ Cruise_Control_Accelerate_Switch : 38|2@1+ (1,0) [0|3] "bit" Vector__XXX
 SG_ pCruise_Enable_Status : 48|4@1+ (1,0) [0|15] "state" Vector__XXX
 SG_ Parking_Brake_Switch : 2|2@1+ (1,0) [0|3] "bit" Vector__XXX
 SG_ Cruise_Control_Coast_Decelerate_ : 34|2@1+ (1,0) [0|3] "bit" Vector__XXX

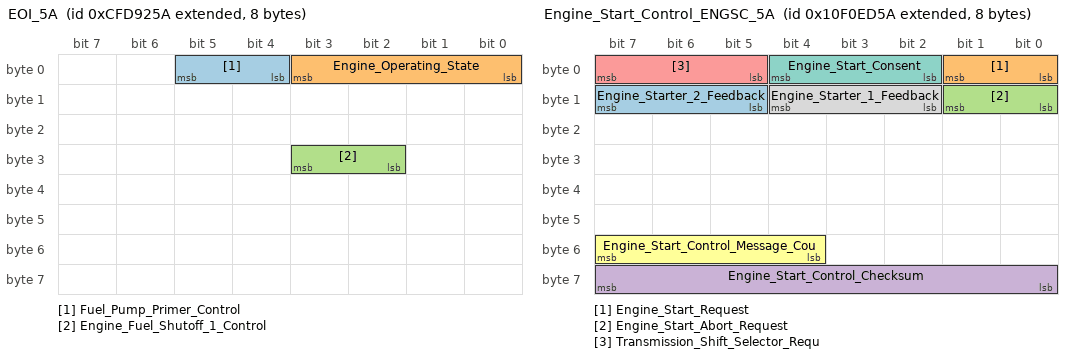
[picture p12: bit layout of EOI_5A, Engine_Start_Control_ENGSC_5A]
BO_ 2365428314 EOI_5A: 8 HCU
 SG_ Fuel_Pump_Primer_Control : 4|2@1+ (1,0) [0|3] "bit" Vector__XXX
 SG_ Engine_Operating_State : 0|4@1+ (1,0) [0|15] "bit" Vector__XXX
 SG_ Engine_Fuel_Shutoff_1_Control : 26|2@1+ (1,0) [0|3] "bit" Vector__XXX

BO_ 2431708506 Engine_Start_Control_ENGSC_5A: 8 HCU
 SG_ Engine_Starter_2_Feedback : 13|3@1+ (1,0) [0|7] "bit" Vector__XXX
 SG_ Engine_Start_Request : 0|2@1+ (1,0) [0|3] "bit" Vector__XXX
 SG_ Engine_Start_Abort_Request : 8|2@1+ (1,0) [0|3] "bit" Vector__XXX
 SG_ Engine_Start_Control_Checksum : 56|8@1+ (1,0) [0|255] "count" Vector__XXX
 SG_ Transmission_Shift_Selector_Requ : 5|3@1+ (1,0) [0|7] "bit" Vector__XXX
 SG_ Engine_Start_Control_Message_Cou : 52|4@1+ (1,0) [0|15] "bit" Vector__XXX
 SG_ Engine_Start_Consent : 2|3@1+ (1,0) [0|7] "bit" Vector__XXX
 SG_ Engine_Starter_1_Feedback : 10|3@1+ (1,0) [0|7] "bit" Vector__XXX

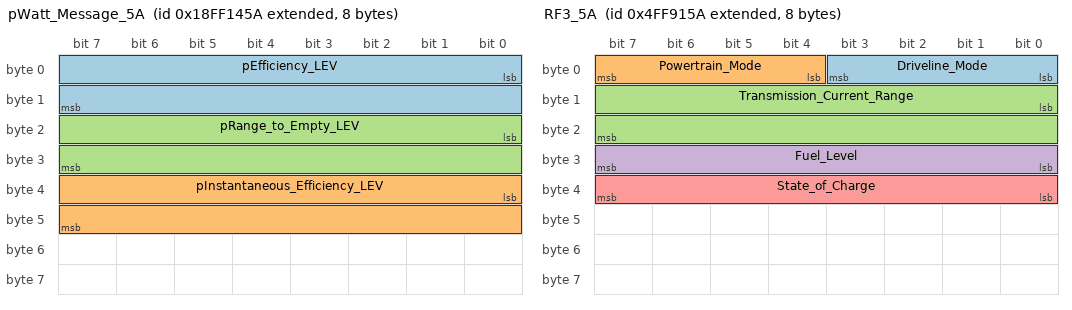
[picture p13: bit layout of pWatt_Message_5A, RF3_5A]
BO_ 2566853722 pWatt_Message_5A: 8 HCU
 SG_ pEfficiency_LEV : 0|16@1+ (0.1,0) [0|6552.6] "kWh" Vector__XXX
 SG_ pInstantaneous_Efficiency_LEV : 32|16@1+ (0.1,0) [0|6552.6] "Watt-hour/km" Vector__XXX
 SG_ pRange_to_Empty_LEV : 16|16@1+ (0.1,0) [0|6552.6] "km" Vector__XXX

BO_ 2231341402 RF3_5A: 8 HCU
 SG_ Driveline_Mode : 0|4@1+ (1,0) [0|15] "state" Vector__XXX
 SG_ Powertrain_Mode : 4|4@1+ (1,0) [0|15] "state" Vector__XXX
 SG_ Transmission_Current_Range : 8|16@1+ (1,0) [0|65535] "state" Vector__XXX
 SG_ Fuel_Level : 24|8@1+ (0.4,0) [0|101.4] "" Vector__XXX
 SG_ State_of_Charge : 32|8@1+ (0.5,0) [0|127] "" Vector__XXX

BO_ 2566834808 DM1_78: 42 IDT
 SG_ Flash_Malfunction_Indicator_Lamp : 14|2@1+ (1,0) [0|3] "" Vector__XXX
 SG_ Malfunction_Indicator_Lamp_Statu : 6|2@1+ (1,0) [0|3] "" Vector__XXX
 SG_ Red_Stop_Lamp_Status : 4|2@1+ (1,0) [0|3] "" Vector__XXX
 SG_ Amber_Warning_Lamp_Status : 2|2@1+ (1,0) [0|3] "" Vector__XXX
 SG_ Flash_Red_Stop_Lamp_RSL : 12|2@1+ (1,0) [0|3] "" Vector__XXX
 SG_ Flash_Amber_Warning_Lamp_AWL : 10|2@1+ (1,0) [0|3] "" Vector__XXX
 SG_ Flash_Protect_Lamp : 8|2@1+ (1,0) [0|3] "" Vector__XXX
 SG_ Protect_Lamp_Status : 0|2@1+ (1,0) [0|3] "" Vector__XXX
 SG_ DTC_1 : 16|32@1+ (1,0) [0|4294967295] "value" Vector__XXX
 SG_ DTC_2 : 48|32@1+ (1,0) [0|4294967295] "value" Vector__XXX
 SG_ DTC_3 : 80|32@1+ (1,0) [0|4294967295] "value" Vector__XXX
 SG_ DTC_4 : 112|32@1+ (1,0) [0|4294967295] "value" Vector__XXX
 SG_ DTC_5 : 144|32@1+ (1,0) [0|4294967295] "value" Vector__XXX
 SG_ DTC_6 : 176|32@1+ (1,0) [0|4294967295] "value" Vector__XXX
 SG_ DTC_7 : 208|32@1+ (1,0) [0|4294967295] "value" Vector__XXX
 SG_ DTC_8 : 240|32@1+ (1,0) [0|4294967295] "value" Vector__XXX
 SG_ DTC_9 : 272|32@1+ (1,0) [0|4294967295] "value" Vector__XXX
 SG_ DTC_10 : 304|32@1+ (1,0) [0|4294967295] "value" Vector__XXX

BO_ 2566834812 DM1_7C: 42 GMRS
 SG_ Flash_Malfunction_Indicator_Lamp : 14|2@1+ (1,0) [0|3] "" Vector__XXX
 SG_ Malfunction_Indicator_Lamp_Statu : 6|2@1+ (1,0) [0|3] "" Vector__XXX
 SG_ Red_Stop_Lamp_Status : 4|2@1+ (1,0) [0|3] "" Vector__XXX
 SG_ Amber_Warning_Lamp_Status : 2|2@1+ (1,0) [0|3] "" Vector__XXX
 SG_ Flash_Red_Stop_Lamp_RSL : 12|2@1+ (1,0) [0|3] "" Vector__XXX
 SG_ Flash_Amber_Warning_Lamp_AWL : 10|2@1+ (1,0) [0|3] "" Vector__XXX
 SG_ Flash_Protect_Lamp : 8|2@1+ (1,0) [0|3] "" Vector__XXX
 SG_ Protect_Lamp_Status : 0|2@1+ (1,0) [0|3] "" Vector__XXX
 SG_ DTC_1 : 16|32@1+ (1,0) [0|4294967295] "value" Vector__XXX
 SG_ DTC_2 : 48|32@1+ (1,0) [0|4294967295] "value" Vector__XXX
 SG_ DTC_3 : 80|32@1+ (1,0) [0|4294967295] "value" Vector__XXX
 SG_ DTC_4 : 112|32@1+ (1,0) [0|4294967295] "value" Vector__XXX
 SG_ DTC_5 : 144|32@1+ (1,0) [0|4294967295] "value" Vector__XXX
 SG_ DTC_6 : 176|32@1+ (1,0) [0|4294967295] "value" Vector__XXX
 SG_ DTC_7 : 208|32@1+ (1,0) [0|4294967295] "value" Vector__XXX
 SG_ DTC_8 : 240|32@1+ (1,0) [0|4294967295] "value" Vector__XXX
 SG_ DTC_9 : 272|32@1+ (1,0) [0|4294967295] "value" Vector__XXX
 SG_ DTC_10 : 304|32@1+ (1,0) [0|4294967295] "value" Vector__XXX

BO_ 2566834814 DM1_7E: 42 XM
 SG_ Flash_Malfunction_Indicator_Lamp : 14|2@1+ (1,0) [0|3] "" Vector__XXX
 SG_ Malfunction_Indicator_Lamp_Statu : 6|2@1+ (1,0) [0|3] "" Vector__XXX
 SG_ Red_Stop_Lamp_Status : 4|2@1+ (1,0) [0|3] "" Vector__XXX
 SG_ Amber_Warning_Lamp_Status : 2|2@1+ (1,0) [0|3] "" Vector__XXX
 SG_ Flash_Red_Stop_Lamp_RSL : 12|2@1+ (1,0) [0|3] "" Vector__XXX
 SG_ Flash_Amber_Warning_Lamp_AWL : 10|2@1+ (1,0) [0|3] "" Vector__XXX
 SG_ Flash_Protect_Lamp : 8|2@1+ (1,0) [0|3] "" Vector__XXX
 SG_ Protect_Lamp_Status : 0|2@1+ (1,0) [0|3] "" Vector__XXX
 SG_ DTC_1 : 16|32@1+ (1,0) [0|4294967295] "value" Vector__XXX
 SG_ DTC_2 : 48|32@1+ (1,0) [0|4294967295] "value" Vector__XXX
 SG_ DTC_3 : 80|32@1+ (1,0) [0|4294967295] "value" Vector__XXX
 SG_ DTC_4 : 112|32@1+ (1,0) [0|4294967295] "value" Vector__XXX
 SG_ DTC_5 : 144|32@1+ (1,0) [0|4294967295] "value" Vector__XXX
 SG_ DTC_6 : 176|32@1+ (1,0) [0|4294967295] "value" Vector__XXX
 SG_ DTC_7 : 208|32@1+ (1,0) [0|4294967295] "value" Vector__XXX
 SG_ DTC_8 : 240|32@1+ (1,0) [0|4294967295] "value" Vector__XXX
 SG_ DTC_9 : 272|32@1+ (1,0) [0|4294967295] "value" Vector__XXX
 SG_ DTC_10 : 304|32@1+ (1,0) [0|4294967295] "value" Vector__XXX

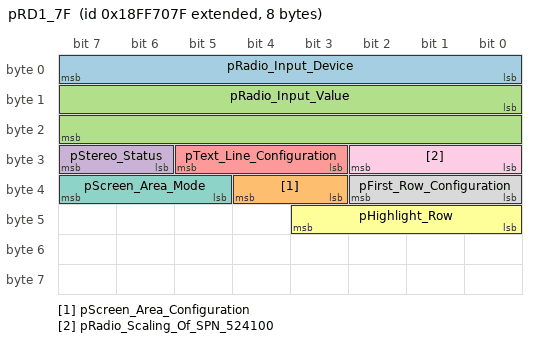
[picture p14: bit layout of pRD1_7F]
BO_ 2566877311 pRD1_7F: 8 RH
 SG_ pRadio_Input_Device : 0|8@1+ (1,0) [0|255] "state" Vector__XXX
 SG_ pScreen_Area_Configuration : 35|2@1+ (1,0) [0|3] "state" Vector__XXX
 SG_ pRadio_Input_Value : 8|16@1+ (1,0) [0|65535] "" Vector__XXX
 SG_ pStereo_Status : 30|2@1+ (1,0) [0|3] "state" Vector__XXX
 SG_ pText_Line_Configuration : 27|3@1+ (1,0) [0|7] "state" Vector__XXX
 SG_ pHighlight_Row : 40|4@1+ (1,0) [0|15] "state" Vector__XXX
 SG_ pScreen_Area_Mode : 37|3@1+ (1,0) [0|7] "state" Vector__XXX
 SG_ pFirst_Row_Configuration : 32|3@1+ (1,0) [0|7] "state" Vector__XXX
 SG_ pRadio_Scaling_Of_SPN_524100 : 24|3@1+ (1,0) [0|7] "state" Vector__XXX

CM_ BO_ 2565866791 "Name: Electronic Transmission Controller
Description: Parsed from -014. ";
CM_ SG_ 2565866791 Transmission_Actual_Gear_Ratio "Description:Actual ratio of input shaft speed to output shaft speed.
Note: Parsed from J1939DA.";
CM_ SG_ 2565866791 Transmission_Requested_Range "Description:Range selected by the operator. Characters may include P, Rx, Rx-1...R2, R1, R, Nx, Nx-1...N2, N1, N, D, D1, D2..., Dx, L, L1, L2..., Lx-1, 1, 2, 3,... If only one displayed character is required, the second chara";
CM_ SG_ 2565866791 Transmission_Current_Range "Description:Range currently being commanded by the transmission control system. Characters may include P, Rx, Rx-1...R2, R1, R, Nx, Nx-1...N2, N1, N, D, D1, D2..., Dx, L, L1, L2..., Lx-1, 1, 2, 3,... If only one displayed chara";
CM_ SG_ 2565866791 Transmission_Current_Gear "Description:The gear currently engaged in the transmission or the last gear engaged while the transmission is in the process of shifting to the new or selected gear. Transitions toward a destination gear will not be indicated. O";
CM_ SG_ 2565866791 Transmission_Selected_Gear "Description:The gear that the transmission will attempt to achieve during the current shift if a shift is in progress, or the next shift if one is pending (i.e., waiting for torque reduction to initiate the shift). Negative val";
CM_ BO_ 2566834727 "Name: Active Diagnostic Trouble Codes
Description:DM1 provides diagnostic lamp status and Diagnostic Trouble Codes (DTCs). Together, the lamp and DTC information
convey the diagnostic condition of the transmitting electronic component to other componen";
CM_ SG_ 2566834727 Flash_Malfunction_Indicator_Lamp "Description:This parameter provides the capability to flash the MIL. For OBD systems which are required to flash the SPN for specific malfunctions shall use the “slow flash” rate. 
See J1939-73 for complete reference
Pa";
CM_ SG_ 2566834727 Malfunction_Indicator_Lamp_Statu "Description:Used to relay only emissions-related trouble code information. This lamp is only illuminated when there is an emission-related trouble code active.
See J1939-71 for complete reference

Parsed from -014.";
CM_ SG_ 2566834727 Red_Stop_Lamp_Status "Description:Used to relay trouble code information that is of a severe enough condition that it warrants stopping the vehicle.
See J1939-71 for complete reference

Parsed from -014.";
CM_ SG_ 2566834727 Amber_Warning_Lamp_Status "Description:Used to relay trouble code information that is reporting a problem with the vehicle system but the vehicle need not be immediately stopped.
See J1939-71 for complete reference

Parsed from -014.";
CM_ SG_ 2566834727 Flash_Red_Stop_Lamp_RSL "Description:This parameter provides the capability to flash the RSL.
See J1939-73 for complete reference
Parsed from -014.";
CM_ SG_ 2566834727 Flash_Amber_Warning_Lamp_AWL "Description:This parameter provides the capability to flash the AWL. 
See J1939-73 for complete reference
Parsed from -014.";
CM_ SG_ 2566834727 Flash_Protect_Lamp "Description:This parameter provides the capability to flash the protect lamp. 
See J1939-73 for complete reference
Parsed from -014.";
CM_ SG_ 2566834727 Protect_Lamp_Status "Description:Used to relay trouble code information that is reporting a problem with a vehicle system that is most probably not electronic subsystem related. For instance, engine coolant temperature is exceeding its prescribed temperat";
CM_ SG_ 2566834727 DTC_1 "Description:This signal is a combination of 4 SPNs. To decode this signal, navigate to MCS tools.
Byte: 1 bits 8-1 SPN, 8 least significant bits of SPN (most significant at bit 8, SPN 1214)
Byte: 2 bits 8-1 SPN, second byte of SPN (most significa";
CM_ SG_ 2566834727 DTC_2 "Description:This signal is a combination of 4 SPNs. To decode this signal, navigate to MCS tools.
Byte: 1 bits 8-1 SPN, 8 least significant bits of SPN (most significant at bit 8, SPN 1214)
Byte: 2 bits 8-1 SPN, second byte of SPN (most significa";
CM_ SG_ 2566834727 DTC_3 "Description:This signal is a combination of 4 SPNs. To decode this signal, navigate to MCS tools.
Byte: 1 bits 8-1 SPN, 8 least significant bits of SPN (most significant at bit 8, SPN 1214)
Byte: 2 bits 8-1 SPN, second byte of SPN (most significa";
CM_ SG_ 2566834727 DTC_4 "Description:This signal is a combination of 4 SPNs. To decode this signal, navigate to MCS tools.
Byte: 1 bits 8-1 SPN, 8 least significant bits of SPN (most significant at bit 8, SPN 1214)
Byte: 2 bits 8-1 SPN, second byte of SPN (most significa";
CM_ SG_ 2566834727 DTC_5 "Description:This signal is a combination of 4 SPNs. To decode this signal, navigate to MCS tools.
Byte: 1 bits 8-1 SPN, 8 least significant bits of SPN (most significant at bit 8, SPN 1214)
Byte: 2 bits 8-1 SPN, second byte of SPN (most significa";
CM_ SG_ 2566834727 DTC_6 "Description:This signal is a combination of 4 SPNs. To decode this signal, navigate to MCS tools.
Byte: 1 bits 8-1 SPN, 8 least significant bits of SPN (most significant at bit 8, SPN 1214)
Byte: 2 bits 8-1 SPN, second byte of SPN (most significa";
CM_ SG_ 2566834727 DTC_7 "Description:This signal is a combination of 4 SPNs. To decode this signal, navigate to MCS tools.
Byte: 1 bits 8-1 SPN, 8 least significant bits of SPN (most significant at bit 8, SPN 1214)
Byte: 2 bits 8-1 SPN, second byte of SPN (most significa";
CM_ SG_ 2566834727 DTC_8 "Description:This signal is a combination of 4 SPNs. To decode this signal, navigate to MCS tools.
Byte: 1 bits 8-1 SPN, 8 least significant bits of SPN (most significant at bit 8, SPN 1214)
Byte: 2 bits 8-1 SPN, second byte of SPN (most significa";
CM_ SG_ 2566834727 DTC_9 "Description:This signal is a combination of 4 SPNs. To decode this signal, navigate to MCS tools.
Byte: 1 bits 8-1 SPN, 8 least significant bits of SPN (most significant at bit 8, SPN 1214)
Byte: 2 bits 8-1 SPN, second byte of SPN (most significa";
CM_ SG_ 2566834727 DTC_10 "Description:This signal is a combination of 4 SPNs. To decode this signal, navigate to MCS tools.
Byte: 1 bits 8-1 SPN, 8 least significant bits of SPN (most significant at bit 8, SPN 1214)
Byte: 2 bits 8-1 SPN, second byte of SPN (most signific";
CM_ BO_ 2566845479 "Name: Tire Condition
Description: Parsed from -014. ";
CM_ SG_ 2566845479 Tire_Temperature "Description:Temperature at the surface of the tire sidewall.
Note: Parsed from J1939DA.";
CM_ SG_ 2566845479 Tire_Pressure "Description:Pressure at which air is contained in cavity formed by tire and rim.
Note: Parsed from J1939DA.";
CM_ SG_ 2566845479 Tire_Location "Description:Identifies which tire is associated with the parametric data in this PG. The low order 4 bits represent a position number, counting left to right when facing in the direction of normal vehicle travel (forward). The high order 4 ";
CM_ BO_ 2566844711 "Name: Cruise Control Vehicle Speed 1
Description: Parsed from -014. ";
CM_ SG_ 2566844711 Cruise_Control_Set_Speed "Description:Value of set (chosen) velocity of velocity control system. See SPN 6809 for an alternate resolution. If an algorithm that can modify the cruise control set point exists in the system, such as Predictive Cruise Control";
CM_ SG_ 2566844711 Cruise_Control_Active "Description:Cruise control is switched on. It is not ensured that the engine is controlled by cruise control, as in the case of a large driver's demand the engine is controlled by the driver while cruise control is active (maximum s";
CM_ SG_ 2566844711 Clutch_Switch "Description:Switch signal which indicates that the clutch pedal is being pressed. It is necessary for a safe drivetrain behavior that the clutch switch is set before the clutch is opened (cruise control function). 00b = Clutch pedal release";
CM_ SG_ 2566844711 Brake_Switch "Description:Switch signal which indicates that the driver operated brake foot pedal is being pressed. This brake foot pedal is controlling the vehicles' service brake (total vehicle braking application, not park brakes). It is necessary for ";
CM_ SG_ 2566844711 pCC_Message_Counter "Description: Rolling Counter (ensures updated message is used).
Could not parse SPN data type, please add:Type: Status
Parsed from -014. ";
CM_ SG_ 2566844711 Cruise_Control_Pause_Switch "Description:Switch signal which indicates the position of the Cruise Control Pause Switch used on Remote Cruise Control applications. The Cruise Control Pause Switch signal temporarily disables the Cruise Control function. 00b";
CM_ SG_ 2566844711 Cruise_Control_Set_Switch "Description:Switch signal of the cruise control activator which indicates that the activator is in the position set. 00b = Cruise control activator not in the position set 01b = Cruise control activator in position set 10b = Err";
CM_ SG_ 2566844711 Two_Speed_Axle_Switch "Description:Switch signal which indicates the current axle range. 00b = Low speed range 01b = High speed range 10b = Error 11b = Not available
Note: Parsed from J1939DA.";
CM_ SG_ 2566844711 Cruise_Control_Enable_Switch "Description:Switch signal which indicates that it is possible to manage the cruise control function. 00b = Cruise control disabled 01b = Cruise control enabled 10b = Error 11b = Not available
Note: Parsed from J1939DA.";
CM_ SG_ 2566844711 pOdometer_Drive_Bit "Description: Each State A->B or B->A change indicates the vehicle has moved 40 m since the previous one. However, since the message is sent at regular 100 ms intervals, State A and B each occur multiple times consecutively (a minimum ";
CM_ SG_ 2566844711 pCC_Checksum "Description: XOR of bytes 0-6 (ensures data is valid before use). 
Could not parse SPN data type, please add:Type: Status
Parsed from -014. ";
CM_ SG_ 2566844711 WheelBased_Vehicle_Speed "Description:Speed of the vehicle as calculated from wheel or tailshaft speed.
Note: Parsed from J1939DA.";
CM_ SG_ 2566844711 Cruise_Control_Resume_Switch "Description:Switch signal of the cruise control activator which indicates that the activator is in the position resume. 00b = Cruise control activator not in the position resume 01b = Cruise control activator in position resu";
CM_ SG_ 2566844711 Cruise_Control_Accelerate_Switch "Description:Switch signal of the cruise control activator which indicates that the activator is in the position accelerate. 00b = Cruise control activator not in the position accelerate 01b = Cruise control activator in p";
CM_ SG_ 2566844711 pCruise_Enable_Status "Description: The Cruise Control System has been enabled by the operator. (Amber Light) ";
CM_ SG_ 2566844711 Parking_Brake_Switch "Description:Switch signal which indicates when the parking brake is set. In general the switch actuated by the operator's park brake control, whether a pedal, lever or other control mechanism (see also SPN 619 and 5275). 00b = Parkin";
CM_ SG_ 2566844711 Cruise_Control_Coast_Decelerate_ "Description:Switch signal of the cruise control activator which indicates that the activator is in the position coast (decelerate). 00b = Cruise control activator not in the position coast 01b = Cruise control activator i";
CM_ BO_ 2566860839 "Name: pRemote Vehicle Feedback
Description: Used to give feedback to autonomous system.
Parsed from -014. ";
CM_ SG_ 2566860839 pAllowRemCommands "Description: State of whether or not system will allow remote commands. ";
CM_ SG_ 2566860839 pRVFBMessageCounter "Description: Used to verify the signal path from Transmitter up to the Application Software layer of the Receiver.
Transmitter increments the count for every message transmission, automatically rolling over at 15.
Could not parse of";
CM_ SG_ 2566860839 pReleaseCommand "Description: Whether or not a release command is active. ";
CM_ SG_ 2566860839 pDirectionalVehicleSpeed "Description: Directional Vehicle Speed
Could not parse SPN data type, please add:Type: Measured
Parsed from -014. ";
CM_ SG_ 2566860839 pEmergencyStop "Description: State of whether or not system is in Emergency Stop ";
CM_ SG_ 2566860839 pRVFBMessageCRC "Description: Used to verify the signal path from Transmitter up to the Application Software layer of the Receiver.
Calculated using the CRC8 0xEA Polynomial formula. Data used in calculation is [Message ID][Data Bytes 1-7].
Could not pa";
CM_ BO_ 2365473063 "Name: Lighting Command LCMD
Description: Parsed from -014. ";
CM_ SG_ 2365473063 Left_Turn_Signal_Lights_Command "Description:Command to activate or de-activate left turn signal lights on the tractor and all connected implements 00b = De-activate 01b = Activate 10b = Reserved 11b = Don't Care
Note: Parsed from J1939DA.";
CM_ SG_ 2365473063 Alternate_Beam_Head_Light_Comman "Description:Command to activate or de-activate the tractor alternate head lights (only low beam is available on alternate head lights). The alternate position lights are intended for use with loader and snow plows that te";
CM_ SG_ 2365473063 Right_Turn_Signal_Lights_Command "Description:Command to activate or de-activate right turn signal lights on the tractor and all connected implements 00b = De-activate 01b = Activate 10b = Reserved 11b = Don't Care
Note: Parsed from J1939DA.";
CM_ SG_ 2365473063 Running_Light_Command "Description:Command to activate or de-activate the tractor or powered vehicle running lights. Usually only used for on road vehicles. 00b = De-activate 01b = Activate 10b = Reserved 11b = Don't Care
Note: Parsed from J1939DA.";
CM_ BO_ 2349465383 "Name: Static Roll Angle Sensor Information
Description: Parsed from -014. ";
CM_ SG_ 2349465383 Static_Roll_Angle "Description:The measured static roll angle between the vehicle y-axis and the ground plane about the X-axis. The sign of the roll angle is determined in accordance to the right-hand rule about the X-axis, as specified in SAE J670. Roll ";
CM_ BO_ 2631728935 "Name: Anti-Theft Staus
Description: Parsed from -014. ";
CM_ SG_ 2631728935 Antitheft_Random_Number "Description:A seven byte random numeric code provided by the component in response to an anti-theft request. This parameter is sent as a numeric value utilizing the full range of 0 to FFFFFFFFFFFFFFh. The most significant byte is ";
CM_ SG_ 2631728935 Antitheft_Encryption_Seed_Presen "Description:Indicates the presence of the encryption seed random number. 00b = Random number is not present 01b = Random number is present 10b = Error 11b = Not available
Note: Parsed from J1939DA.";
CM_ SG_ 2631728935 Antitheft_Password_Valid_Indicat "Description:Indicates the presence of a validated password. 00b = Password is not a validated password 01b = Password is a validated password 10b = Error 11b = Not available
Note: Parsed from J1939DA.";
CM_ SG_ 2631728935 Antitheft_Modify_Password_States "Description:This parameter is used to indicate whether a password request was successfully performed, or if the request could not be perform due to system constraints or if the request was not a valid request. 00b = Ok 01";
CM_ SG_ 2631728935 Antitheft_Component_Status_State "Description:Indicates whether or not the component can be started. 00b = Unlocked 01b = Locked 10b = Blocked 11b = Not defined 00b - Unlocked = This state indicates that the component can be started without the end user b";
CM_ BO_ 2633883431 "Name: Front Wheel Drive Status
Description: Parsed from -014. ";
CM_ SG_ 2633883431 Front_Wheel_Drive_Actuator_Statu "Description:Feedback on the front wheel drive actuator. 00b = Front Wheel Drive Actuator not engaged 01b = Front Wheel Drive Actuator engaged 10b = Error 11b = Not Available
Note: Parsed from J1939DA.";
CM_ BO_ 2432656679 "Name: pOperator Switch Status
Description: Parsed from -014. ";
CM_ SG_ 2432656679 Key_Fob_Unlock_Button_Status "Description: These group of SPN&rsquo;s contain the information for the Operator Switches. See PGN 65380 breakdown for definition of each button. ";
CM_ SG_ 2432656679 Homelink_2 "Description: These group of SPN&rsquo;s contain the information for the Operator Switches. See PGN 65380 breakdown for definition of each button. ";
CM_ SG_ 2432656679 Side_Stand_Switch "Description: ";
CM_ SG_ 2432656679 Key_Fob_Lock_Button_Status "Description: These group of SPN&rsquo;s contain the information for the Operator Switches. See PGN 65380 breakdown for definition of each button. ";
CM_ SG_ 2432656679 Windshield__2_Down "Description: These group of SPN&rsquo;s contain the information for the Operator Switches. See PGN 65380 breakdown for definition of each button. ";
CM_ SG_ 2432656679 Turn__3_Cancel "Description: These group of SPN&rsquo;s contain the information for the Operator Switches. See PGN 65380 breakdown for definition of each button. ";
CM_ SG_ 2432656679 Reverse "Description: These group of SPN&rsquo;s contain the information for the Operator Switches. See PGN 65380 breakdown for definition of each button. ";
CM_ SG_ 2432656679 Hazard "Description: These group of SPN&rsquo;s contain the information for the Operator Switches. See PGN 65380 breakdown for definition of each button. ";
CM_ SG_ 2432656679 Homelink_1 "Description: These group of SPN&rsquo;s contain the information for the Operator Switches. See PGN 65380 breakdown for definition of each button. ";
CM_ SG_ 2432656679 Windshield__1_Up "Description: These group of SPN&rsquo;s contain the information for the Operator Switches. See PGN 65380 breakdown for definition of each button. ";
CM_ SG_ 2432656679 Front_Brake_Switch "Description: Indicates the status of the front brake switch ";
CM_ SG_ 2432656679 Instrument_Cluster_Control__2 "Description: These group of SPN&rsquo;s contain the information for the Operator Switches. See PGN 65380 breakdown for definition of each button. ";
CM_ SG_ 2432656679 Chassis_Unlock_Button_Status "Description: These group of SPN&rsquo;s contain the information for the Operator Switches. See PGN 65380 breakdown for definition of each button. ";
CM_ SG_ 2432656679 Power_Button "Description: These group of SPN&rsquo;s contain the information for the Operator Switches. See PGN 65380 breakdown for definition of each button. ";
CM_ SG_ 2432656679 RunStop_Switch "Description: These group of SPN&rsquo;s contain the information for the Operator Switches. See PGN 65380 breakdown for definition of each button. ";
CM_ SG_ 2432656679 Headlamp__2_High "Description: These group of SPN&rsquo;s contain the information for the Operator Switches. See PGN 65380 breakdown for definition of each button. ";
CM_ SG_ 2432656679 Instrument_Cluster_Control__1 "Description: These group of SPN&rsquo;s contain the information for the Operator Switches. See PGN 65380 breakdown for definition of each button. ";
CM_ SG_ 2432656679 Clutch_Switch "Description: These group of SPN&rsquo;s contain the information for the Operator Switches. See PGN 65380 breakdown for definition of each button. ";
CM_ SG_ 2432656679 Start "Description: These group of SPN&rsquo;s contain the information for the Operator Switches. See PGN 65380 breakdown for definition of each button. ";
CM_ SG_ 2432656679 Headlamp__3_Driving "Description: These group of SPN&rsquo;s contain the information for the Operator Switches. See PGN 65380 breakdown for definition of each button. ";
CM_ SG_ 2432656679 Cruise__2_Set "Description: These group of SPN&rsquo;s contain the information for the Operator Switches. See PGN 65380 breakdown for definition of each button. ";
CM_ SG_ 2432656679 Windshield_Wiper "Description: These group of SPN&rsquo;s contain the information for the Operator Switches. See PGN 65380 breakdown for definition of each button. ";
CM_ SG_ 2432656679 Fog "Description: These group of SPN&rsquo;s contain the information for the Operator Switches. See PGN 65380 breakdown for definition of each button. ";
CM_ SG_ 2432656679 Cruise__3_Accel "Description: These group of SPN&rsquo;s contain the information for the Operator Switches. See PGN 65380 breakdown for definition of each button. ";
CM_ SG_ 2432656679 Horn "Description: These group of SPN&rsquo;s contain the information for the Operator Switches. See PGN 65380 breakdown for definition of each button. ";
CM_ SG_ 2432656679 Turn__2_Right "Description: These group of SPN&rsquo;s contain the information for the Operator Switches. See PGN 65380 breakdown for definition of each button. ";
CM_ SG_ 2432656679 Cruise__1_On "Description: These group of SPN&rsquo;s contain the information for the Operator Switches. See PGN 65380 breakdown for definition of each button. ";
CM_ SG_ 2432656679 Turn__1_Left "Description: These group of SPN&rsquo;s contain the information for the Operator Switches. See PGN 65380 breakdown for definition of each button. ";
CM_ SG_ 2432656679 Throttle_Safety_Switch__1 "Description: These group of SPN&rsquo;s contain the information for the Operator Switches. See PGN 65380 breakdown for definition of each button. ";
CM_ SG_ 2432656679 Headlamp__1_Low "Description: These group of SPN&rsquo;s contain the information for the Operator Switches. See PGN 65380 breakdown for definition of each button. ";
CM_ SG_ 2432656679 Chassis_Lock_Switch_Status "Description:Created due to CMS fault code using this SPN";
CM_ SG_ 2432656679 Fuel_Door_Unlock_Button_Status "Description:Displays the status of the Fuel Door Unlock button. See PGN 65380 breakdown for the definition of each button.";
CM_ BO_ 2365523495 "Name: pModule Control Message
Description: Parsed from -014. ";
CM_ SG_ 2365523495 pModule_Control_Applied_State "Description: Indicates the requester&rsquo;s command to control wake state of other modules. Partial Wakeup and Full Wakeup are to be defined per each module.

 ";
CM_ SG_ 2365523495 pModule_Control_Command_Destinat "Description: Indicates which source address the requester is commanding. Destination address FFh is used to indicate that all source addresses should obey the Module Control Command State signal. FFFFh indicates &ldquo;no";
CM_ SG_ 2365523495 pModule_Control_Command_State "Description: Indicates the requester&rsquo;s command to control wake state of other modules. Each state to be defined per each module. ";
CM_ SG_ 2365523495 pModule_Control_Message_Checksum "Description: Message checksum that is calculated as follows:
Intermediate Checksum =
Byte1 + Byte2 + Byte3 + Byte4 + Byte5 + Byte6 + Byte7 + (8.1 Nibble & 0x0F) + Message ID Low Byte + Message ID Mid Low Byte + Message ";
CM_ BO_ 2566841895 "Name: Time/Date
Description: Parsed from -014. ";
CM_ SG_ 2566841895 Day "Description:The day component of the current calendar date. This should be reported as the day component of the current date at UTC (Universal Time Coordinate), a.k.a. GMT; however, it may be reported as the day component of the current date at a loc";
CM_ SG_ 2566841895 Month "Description:The month component of the current calendar date. This should be reported as the month component of the current date at UTC (Universal Time Coordinate), a.k.a. GMT; however, it may be reported as the month component of the current date ";
CM_ SG_ 2566841895 Local_minute_offset "Description:The minute component of the offset between the UTC time and date and a local time zone time and date. This is the number of minutes to add to UTC (Universal Time Coordinate) time and date to convert to the time and date in";
CM_ SG_ 2566841895 Local_hour_offset "Description:The hour component of the offset between the UTC (Universal Time Coordinate) time and date and a local time zone time and date. This is the number of hours to add to UTC, a.k.a. GMT, time and date to convert to the time and ";
CM_ SG_ 2566841895 Hours "Description:The hour component of the current time of day. This should be reported as the hour component of the current time at UTC (Universal Time Coordinate), a.k.a. GMT; however, it may be reported as the hour component of the current time at a ";
CM_ SG_ 2566841895 Minutes "Description:The minutes component of the current time of day. This should be reported as the minutes component of the current time at UTC (Universal Time Coordinate), a.k.a. GMT; however, it may be reported as the minutes component of the current";
CM_ SG_ 2566841895 Seconds "Description:The seconds component of the current time of day. This should be reported as the seconds component of the current time at UTC (Universal Time Coordinate), a.k.a. GMT; however, it may be reported as the seconds component of the current";
CM_ SG_ 2566841895 Year "Description:The year component of the current calendar date. This should be reported as the year component of the current date at UTC (Universal Time Coordinate), a.k.a. GMT; however, it may be reported as the year component of the current date at a";
CM_ BO_ 2431708455 "Name: Engine Start Control (ENGSC)
Description: Parsed from -014. ";
CM_ SG_ 2431708455 Engine_Starter_2_Feedback "Description:Feedback of the current state of second engine starter. This signal is intended to be used by the arbitrator as feedback to its command signal (SPN 7753). Additional details regarding the starter state may be availab";
CM_ SG_ 2431708455 Engine_Start_Request "Description:Indicates the sender's desire to start the engine. The engine start arbitrator latches this signal and, if possible, completes the engine start regardless of a change of state of this signal. Use Engine Start Abort Reques";
CM_ SG_ 2431708455 Engine_Start_Abort_Request "Description:Indicates the sender's desire to abort an engine start. This signal is used by requesters and consenters to request that the arbitrator cancel an engine start that is in progress. The sender of this signal may incre";
CM_ SG_ 2431708455 Engine_Start_Control_Checksum "Description:Checksum to allow detection of data integrity issues. The receiving node shall calculate the checksum and compare its calculated value with the received checksum. In case of a mismatch the message shall be discar";
CM_ SG_ 2431708455 Transmission_Shift_Selector_Requ "Description:This parameter indicates the direction selected by the operator via the active transmission shift selector. Some regulations (e.g., Federal Motor Vehicle Safety Standards 102) require specific Engine Stop-Star";
CM_ SG_ 2431708455 Engine_Start_Control_Message_Cou "Description:Message counter to allow detection of data integrity issues. The counter is incremented every time a device sends out the Engine Start Control message. When the counter has reached a value of 15 it starts over";
CM_ SG_ 2431708455 Engine_Start_Consent "Description:Indicates the sender's consent to start the engine for different start types. An operator-requested engine start is a start that is initiated directly by the operator (i.e. via the key switch). An automatic engine start i";
CM_ SG_ 2431708455 Engine_Starter_1_Feedback "Description:Feedback of the current state of first engine starter. This signal is intended to be used by the arbitrator as feedback to its command signal (SPN 7753). Additional details regarding the starter state may be availabl";
CM_ BO_ 2365531175 "Name: pVehModCmd
Description:Vehicle Mode Command";
CM_ SG_ 2365531175 pEPSReqMod "Description: Used to set the EPAS assist mode. ";
CM_ BO_ 2631794471 "Name: Anti-Theft Request
Description: Parsed from -014. ";
CM_ SG_ 2631794471 Antitheft_Desired_Exit_Mode_Stat "Description:This parameter is used to specify the desired triggers that are to be used by the component in deciding when to transition to the Locked state. 00b = Lock_Upon_Operator_Request 01b = Lock_When_Key_Off 10b = No";
CM_ SG_ 2631794471 Antitheft_Encryption_Indicator_S "Description:This parameter is used to indicate if a random number seed is being requested, or if an encrypted password is being provided to the component. 00b = Encryption_Seed_Request 01b = Encrypted_Code_Present 10b = N";
CM_ SG_ 2631794471 Antitheft_Command_States "Description:This parameter is used to identify the specific requests being sent to the component. 000b = Add_Password 001b = Delete_Password 010b = Change_Password 011b = Lock_or_Unlock 100b = Check_Status 101b = Login 110b = Not";
CM_ SG_ 2631794471 Antitheft_Password_Representatio "Description:This parameter is the seven byte numeric code (i.e., 'encrypted password' or 'key') that is generated based on the encryption algorithm, the password supplied by the end user, and the random number seed given ";
CM_ BO_ 2566882855 "Name: pVCMStatus
Description: Parsed from -014. ";
CM_ SG_ 2566882855 pVCMState "Description: Broadcasting the current operating state of the VCM.  ";
CM_ SG_ 2566882855 pFog_Light_Control_Mode "Description: User Setting for Fog Light Function
Start Position : 2.5
Type: Status
PGN: 65414
Parsed from -014. ";
CM_ SG_ 2566882855 pHeated_Grips_Control_Mode "Description: User Setting for Fog Light Function
Start Position : 
Type: Status
PGN: 65414
Parsed from -014. ";
CM_ SG_ 2566882855 pLoadShedSts "Description: Load shed level as determined by load shedding function.   ";
CM_ BO_ 2566877479 "Name: pCluster Status 1
Description: Parsed from -014. ";
CM_ SG_ 2566877479 pTemperature_Units_Selected "Description: Active display temperature units beased on user selection or auto-configuration. ";
CM_ SG_ 2566877479 pTPMS_Learning_Status "Description: Indicates the status of the tire pressure monitoring sensor learning process. ";
CM_ SG_ 2566877479 pPressure_Units_Selected "Description: Active display pressure units beased on user selection or auto-configuration. ";
CM_ SG_ 2566877479 pHigh_Res_Trip_2_Distance "Description: Secondary distance travled during all or part of a journey.
Could not parse SPN data type, please add:Type: Measured
Parsed from -014. ";
CM_ SG_ 2566877479 pVolume_Units_Selected "Description: Active display volume units beased on user selection or auto-configuration. ";
CM_ SG_ 2566877479 pDisplay_Status "Description: Status of display. ";
CM_ SG_ 2566877479 pTime_Units_Selected "Description: Active display time units beased on user selection or auto-configuration. ";
CM_ SG_ 2566877479 pDistance_Units_Selected "Description: Active display distance units beased on user selection or auto-configuration. ";
CM_ BO_ 2633984551 "Name: pDrive System Status
Description: Parsed from -014. ";
CM_ SG_ 2633984551 pHeated_Grip_Enable "Description: This signal indicates the status of the Heated Grip Enable switch. ";
CM_ SG_ 2633984551 pUser_PIN_Access_Status "Description: This signal indicates if the display/gauge should show the User PIN screen, which allows the user the option of unlocking the vehicle security through the PIN code entry function.  ";
CM_ SG_ 2633984551 pActive_Descent_Control_ADC_Stat "Description: Broadcasting the status of the ADC (active indicates the solenoid is powered). ";
CM_ SG_ 2633984551 pCruise_Control_Set_Status "Description: Broadcasting the status of the Cruise Control Set Status for user indication  ";
CM_ SG_ 2633984551 pTether_Switch_Status "Description: Status of the Tether Switch ";
CM_ SG_ 2633984551 pHigh_Beam_Indicator_Status "Description: Broadcasting the status of the high beam headlight for user indication. ";
CM_ SG_ 2633984551 pLow_Fuel_Indicator_Status "Description: Broadcasting the status of the fuel level for user indication. ";
CM_ SG_ 2633984551 pHeated_Grips_Percentage "Description: Heated Grips Percent On, 0% is Off and 100% is the maximum heat
Could not parse SPN data type, please add:Type: Status
Parsed from -014. ";
CM_ SG_ 2633984551 pSide_Stand_Status "Description: Position of the side stand position when installed on a vehicle. ";
CM_ SG_ 2633984551 pTurf_Mode_Requested "Description: Broadcasting the status of the users request for TURF mode ";
CM_ SG_ 2633984551 pEngine_Idle_Shutdown_Timer "Description: This signal indicates the the amount of time left before the engine is shutdown due to the unattended vehicle engine idle shutdown function.
10-bit Timer:
0 &ndash; 1021 seconds
1022 - Error
1023 - Not Availab";
CM_ SG_ 2633984551 Operator_Not_in_Operating_Statio "Description: The Operator Presence Detection System indicates the operator is not in the correct operating station. ";
CM_ SG_ 2633984551 pAWD_Mode_Requested "Description: Broadcasting the status of the users request for AWD mode ";
CM_ SG_ 2633984551 pHeated_Grips_Up_Switch_Status "Description: This signal indicates the status of the Heated Grip Up switch. ";
CM_ SG_ 2633984551 pTreadle_Neutral_Status "Description: Broadcasting the status of the switch indicating the treadle is/is not in the Neutral position.  ";
CM_ SG_ 2633984551 pHeated_Grips_Down_Switch_Status "Description: This signal indicates the status of the Heated Grip Down switch. ";
CM_ SG_ 2633984551 pPark_Brake_Indicator_Status "Description: Broadcasting the status of the park brake for user indication ";
CM_ SG_ 2633984551 pRWD_Mode_Requested "Description: Broadcasting the status of the users request for RWD mode ";
CM_ SG_ 2633984551 pSeat_Belt_Indicator_Status "Description: Broadcasting the status of the seat belt for user indication ";
CM_ SG_ 2633984551 pSecurity_Light_Immobilizer_Stat "Description: Broadcasting the status of the security system for user indication.  ";
CM_ SG_ 2633984551 ECU_Security_Status "Description: Security Status of an ECU. ";
CM_ SG_ 2633984551 pActive_Decent_Control_ADC_Mode_ "Description: Broadcasting the status of the users request for ADC mode ";
CM_ SG_ 2633984551 pTreadle_Reverse_Status "Description: Broadcasting the status of the switch indicating the treadle is/is not in the Reverse position.  ";
CM_ BO_ 2566876711 "Name: pVehicle Fluids
Description: Parsed from -014. ";
CM_ SG_ 2566876711 pHydraulic_Oil_Temp_Status "Description: Indicates status of Hydraulic oil temperature. ";
CM_ SG_ 2566876711 pHydraulic_Oil_Pressure_Status "Description: Indicates status of Hydraulic oil pressure. ";
CM_ SG_ 2566876711 pEngine_Oil_Pressure_Status "Description: Indicates status of engine oil pressure. ";
CM_ BO_ 2566834735 "Name: Active Diagnostic Trouble Codes
Description:DM1 provides diagnostic lamp status and Diagnostic Trouble Codes (DTCs). Together, the lamp and DTC information
convey the diagnostic condition of the transmitting electronic component to other componen";
CM_ SG_ 2566834735 Flash_Malfunction_Indicator_Lamp "Description:This parameter provides the capability to flash the MIL. For OBD systems which are required to flash the SPN for specific malfunctions shall use the “slow flash” rate. 
See J1939-73 for complete reference
Pa";
CM_ SG_ 2566834735 Malfunction_Indicator_Lamp_Statu "Description:Used to relay only emissions-related trouble code information. This lamp is only illuminated when there is an emission-related trouble code active.
See J1939-71 for complete reference

Parsed from -014.";
CM_ SG_ 2566834735 Red_Stop_Lamp_Status "Description:Used to relay trouble code information that is of a severe enough condition that it warrants stopping the vehicle.
See J1939-71 for complete reference

Parsed from -014.";
CM_ SG_ 2566834735 Amber_Warning_Lamp_Status "Description:Used to relay trouble code information that is reporting a problem with the vehicle system but the vehicle need not be immediately stopped.
See J1939-71 for complete reference

Parsed from -014.";
CM_ SG_ 2566834735 Flash_Red_Stop_Lamp_RSL "Description:This parameter provides the capability to flash the RSL.
See J1939-73 for complete reference
Parsed from -014.";
CM_ SG_ 2566834735 Flash_Amber_Warning_Lamp_AWL "Description:This parameter provides the capability to flash the AWL. 
See J1939-73 for complete reference
Parsed from -014.";
CM_ SG_ 2566834735 Flash_Protect_Lamp "Description:This parameter provides the capability to flash the protect lamp. 
See J1939-73 for complete reference
Parsed from -014.";
CM_ SG_ 2566834735 Protect_Lamp_Status "Description:Used to relay trouble code information that is reporting a problem with a vehicle system that is most probably not electronic subsystem related. For instance, engine coolant temperature is exceeding its prescribed temperat";
CM_ SG_ 2566834735 DTC_1 "Description:This signal is a combination of 4 SPNs. To decode this signal, navigate to MCS tools.
Byte: 1 bits 8-1 SPN, 8 least significant bits of SPN (most significant at bit 8, SPN 1214)
Byte: 2 bits 8-1 SPN, second byte of SPN (most significa";
CM_ SG_ 2566834735 DTC_2 "Description:This signal is a combination of 4 SPNs. To decode this signal, navigate to MCS tools.
Byte: 1 bits 8-1 SPN, 8 least significant bits of SPN (most significant at bit 8, SPN 1214)
Byte: 2 bits 8-1 SPN, second byte of SPN (most significa";
CM_ SG_ 2566834735 DTC_3 "Description:This signal is a combination of 4 SPNs. To decode this signal, navigate to MCS tools.
Byte: 1 bits 8-1 SPN, 8 least significant bits of SPN (most significant at bit 8, SPN 1214)
Byte: 2 bits 8-1 SPN, second byte of SPN (most significa";
CM_ SG_ 2566834735 DTC_4 "Description:This signal is a combination of 4 SPNs. To decode this signal, navigate to MCS tools.
Byte: 1 bits 8-1 SPN, 8 least significant bits of SPN (most significant at bit 8, SPN 1214)
Byte: 2 bits 8-1 SPN, second byte of SPN (most significa";
CM_ SG_ 2566834735 DTC_5 "Description:This signal is a combination of 4 SPNs. To decode this signal, navigate to MCS tools.
Byte: 1 bits 8-1 SPN, 8 least significant bits of SPN (most significant at bit 8, SPN 1214)
Byte: 2 bits 8-1 SPN, second byte of SPN (most significa";
CM_ SG_ 2566834735 DTC_6 "Description:This signal is a combination of 4 SPNs. To decode this signal, navigate to MCS tools.
Byte: 1 bits 8-1 SPN, 8 least significant bits of SPN (most significant at bit 8, SPN 1214)
Byte: 2 bits 8-1 SPN, second byte of SPN (most significa";
CM_ SG_ 2566834735 DTC_7 "Description:This signal is a combination of 4 SPNs. To decode this signal, navigate to MCS tools.
Byte: 1 bits 8-1 SPN, 8 least significant bits of SPN (most significant at bit 8, SPN 1214)
Byte: 2 bits 8-1 SPN, second byte of SPN (most significa";
CM_ SG_ 2566834735 DTC_8 "Description:This signal is a combination of 4 SPNs. To decode this signal, navigate to MCS tools.
Byte: 1 bits 8-1 SPN, 8 least significant bits of SPN (most significant at bit 8, SPN 1214)
Byte: 2 bits 8-1 SPN, second byte of SPN (most significa";
CM_ SG_ 2566834735 DTC_9 "Description:This signal is a combination of 4 SPNs. To decode this signal, navigate to MCS tools.
Byte: 1 bits 8-1 SPN, 8 least significant bits of SPN (most significant at bit 8, SPN 1214)
Byte: 2 bits 8-1 SPN, second byte of SPN (most significa";
CM_ SG_ 2566834735 DTC_10 "Description:This signal is a combination of 4 SPNs. To decode this signal, navigate to MCS tools.
Byte: 1 bits 8-1 SPN, 8 least significant bits of SPN (most significant at bit 8, SPN 1214)
Byte: 2 bits 8-1 SPN, second byte of SPN (most signific";
CM_ BO_ 2566883119 "Name: pRideHeightStatus
Description: Reports status of adjustable Ride Height System ";
CM_ SG_ 2566883119 pRideHeightStatus "Description:Used to send the status of hte Ride Height Adjustment to the vehicle Display";
CM_ SG_ 2566883119 pRideHeightSystemReadiness "Description:Send Ride Height System status to the vehicle display";
CM_ SG_ 2566883119 pRollTiresRequest "Description:Used to notify user of need to move vehicle to properly complete suspension adjustment";
CM_ SG_ 2566883119 pRideHeightPosition "Description: Indicates current vehicle ride height to the Display ";
CM_ SG_ 2566883119 pRideHeightPumpStatus "Description: Used to send the Ride Height Systme Pump status to the engine to adjust torque as necessary to support pump load. ";
CM_ SG_ 2566883119 RH_Expected_Pump_Load "Description:(TBD unused right now) Used by ride height system in predicting hydraulic load engagement to the powertrain before actual engagement.";
CM_ SG_ 2566883119 pRideHeightPumpCommandRequestSta "Description:Used to communicate the request status to use the hydraulic pump from the powertrain as part of control loop.";
CM_ BO_ 2566834742 "Name: Active Diagnostic Trouble Codes
Description:DM1 provides diagnostic lamp status and Diagnostic Trouble Codes (DTCs). Together, the lamp and DTC information
convey the diagnostic condition of the transmitting electronic component to other componen";
CM_ SG_ 2566834742 Flash_Malfunction_Indicator_Lamp "Description:This parameter provides the capability to flash the MIL. For OBD systems which are required to flash the SPN for specific malfunctions shall use the “slow flash” rate. 
See J1939-73 for complete reference
Pa";
CM_ SG_ 2566834742 Malfunction_Indicator_Lamp_Statu "Description:Used to relay only emissions-related trouble code information. This lamp is only illuminated when there is an emission-related trouble code active.
See J1939-71 for complete reference

Parsed from -014.";
CM_ SG_ 2566834742 Red_Stop_Lamp_Status "Description:Used to relay trouble code information that is of a severe enough condition that it warrants stopping the vehicle.
See J1939-71 for complete reference

Parsed from -014.";
CM_ SG_ 2566834742 Amber_Warning_Lamp_Status "Description:Used to relay trouble code information that is reporting a problem with the vehicle system but the vehicle need not be immediately stopped.
See J1939-71 for complete reference

Parsed from -014.";
CM_ SG_ 2566834742 Flash_Red_Stop_Lamp_RSL "Description:This parameter provides the capability to flash the RSL.
See J1939-73 for complete reference
Parsed from -014.";
CM_ SG_ 2566834742 Flash_Amber_Warning_Lamp_AWL "Description:This parameter provides the capability to flash the AWL. 
See J1939-73 for complete reference
Parsed from -014.";
CM_ SG_ 2566834742 Flash_Protect_Lamp "Description:This parameter provides the capability to flash the protect lamp. 
See J1939-73 for complete reference
Parsed from -014.";
CM_ SG_ 2566834742 Protect_Lamp_Status "Description:Used to relay trouble code information that is reporting a problem with a vehicle system that is most probably not electronic subsystem related. For instance, engine coolant temperature is exceeding its prescribed temperat";
CM_ SG_ 2566834742 DTC_1 "Description:This signal is a combination of 4 SPNs. To decode this signal, navigate to MCS tools.
Byte: 1 bits 8-1 SPN, 8 least significant bits of SPN (most significant at bit 8, SPN 1214)
Byte: 2 bits 8-1 SPN, second byte of SPN (most significa";
CM_ SG_ 2566834742 DTC_2 "Description:This signal is a combination of 4 SPNs. To decode this signal, navigate to MCS tools.
Byte: 1 bits 8-1 SPN, 8 least significant bits of SPN (most significant at bit 8, SPN 1214)
Byte: 2 bits 8-1 SPN, second byte of SPN (most significa";
CM_ SG_ 2566834742 DTC_3 "Description:This signal is a combination of 4 SPNs. To decode this signal, navigate to MCS tools.
Byte: 1 bits 8-1 SPN, 8 least significant bits of SPN (most significant at bit 8, SPN 1214)
Byte: 2 bits 8-1 SPN, second byte of SPN (most significa";
CM_ SG_ 2566834742 DTC_4 "Description:This signal is a combination of 4 SPNs. To decode this signal, navigate to MCS tools.
Byte: 1 bits 8-1 SPN, 8 least significant bits of SPN (most significant at bit 8, SPN 1214)
Byte: 2 bits 8-1 SPN, second byte of SPN (most significa";
CM_ SG_ 2566834742 DTC_5 "Description:This signal is a combination of 4 SPNs. To decode this signal, navigate to MCS tools.
Byte: 1 bits 8-1 SPN, 8 least significant bits of SPN (most significant at bit 8, SPN 1214)
Byte: 2 bits 8-1 SPN, second byte of SPN (most significa";
CM_ SG_ 2566834742 DTC_6 "Description:This signal is a combination of 4 SPNs. To decode this signal, navigate to MCS tools.
Byte: 1 bits 8-1 SPN, 8 least significant bits of SPN (most significant at bit 8, SPN 1214)
Byte: 2 bits 8-1 SPN, second byte of SPN (most significa";
CM_ SG_ 2566834742 DTC_7 "Description:This signal is a combination of 4 SPNs. To decode this signal, navigate to MCS tools.
Byte: 1 bits 8-1 SPN, 8 least significant bits of SPN (most significant at bit 8, SPN 1214)
Byte: 2 bits 8-1 SPN, second byte of SPN (most significa";
CM_ SG_ 2566834742 DTC_8 "Description:This signal is a combination of 4 SPNs. To decode this signal, navigate to MCS tools.
Byte: 1 bits 8-1 SPN, 8 least significant bits of SPN (most significant at bit 8, SPN 1214)
Byte: 2 bits 8-1 SPN, second byte of SPN (most significa";
CM_ SG_ 2566834742 DTC_9 "Description:This signal is a combination of 4 SPNs. To decode this signal, navigate to MCS tools.
Byte: 1 bits 8-1 SPN, 8 least significant bits of SPN (most significant at bit 8, SPN 1214)
Byte: 2 bits 8-1 SPN, second byte of SPN (most significa";
CM_ SG_ 2566834742 DTC_10 "Description:This signal is a combination of 4 SPNs. To decode this signal, navigate to MCS tools.
Byte: 1 bits 8-1 SPN, 8 least significant bits of SPN (most significant at bit 8, SPN 1214)
Byte: 2 bits 8-1 SPN, second byte of SPN (most signific";
CM_ BO_ 2566877750 "Name: pVehicle Temperature
Description: Parsed from -014. ";
CM_ SG_ 2566877750 pRight_Hand_Grip_Temperature "Description: Temperature of thermistor in the right hand grip.
Could not parse SPN data type, please add:Type: Measured
Parsed from -014. ";
CM_ SG_ 2566877750 pDriver_Seat_Temperature "Description: Temperature of thermistor in the Driver Seat.
Could not parse SPN data type, please add:Type: Measured
Parsed from -014. ";
CM_ SG_ 2566877750 pPassenger_Seat_Temperature "Description: Temperature of thermistor in the Passenger Seat.
Could not parse SPN data type, please add:Type: Measured
Parsed from -014. ";
CM_ SG_ 2566877750 pLeft_Hand_Grip_Temperature "Description: Temperature of thermistor in the left hand grip.
Could not parse SPN data type, please add:Type: Measured
Parsed from -014. ";
CM_ BO_ 2566882102 "Name: pSeat Status and Control
Description: Parsed from -014. ";
CM_ SG_ 2566882102 pDriver_HeatedCooled_Seat_Enable "Description: This signal indicates the status of the Driver Heated/Cooled Seat Enable Button. ";
CM_ SG_ 2566882102 pDriver_HeatedCooled_Seat_Down_B "Description: This signal indicates the status of the Driver Seat Temperature Down Button. ";
CM_ SG_ 2566882102 pPassenger_HeatedCooled_Seat_Ena "Description: This signal indicates the status of the Passenger Heated/Cooled Seat Enable Button. ";
CM_ SG_ 2566882102 pPassenger_HeatedCooled_Seat_Up_ "Description: This signal indicates the status of the Passenger Seat Temperature Up Button. ";
CM_ SG_ 2566882102 pPassenger_HeatedCooled_Seat_Per "Description: Current level of Heating or Cooling output of the Driver seat on a vehicle. Positive values are Heat level, Negative values are Cooling level, and 0 is Off.
Could not parse SPN data type, please add:Type: St";
CM_ SG_ 2566882102 pPassenger_HeatedCooled_Seat_Dow "Description: This signal indicates the status of the Passenger Seat Temperature Down Button. ";
CM_ SG_ 2566882102 pDriver_HeatedCooled_Seat_Percen "Description: Current level of Heating or Cooling output of the Driver seat on a vehicle. Positive values are Heat level, Negative values are Cooling level, and 0 is Off.
Could not parse SPN data type, please add:Type: St";
CM_ SG_ 2566882102 pDriver_HeatedCooled_Seat_Up_But "Description: This signal indicates the status of the Driver Seat Temperature Up Button. ";
CM_ BO_ 2432658497 "Name: pOperator Switch Status
Description: Parsed from -014. ";
CM_ SG_ 2432658497 pFOCC_Checksum "Description: XOR of bytes 0-6 (ensures data is valid before use). 
Could not parse SPN data type, please add:Type: Status
Parsed from -014. ";
CM_ SG_ 2432658497 Drive_Mode__4 "Description: Broadcasting the status of the operator switch.  ";
CM_ SG_ 2432658497 Drive_Mode__2 "Description: Broadcasting the status of the operator switch.  ";
CM_ SG_ 2432658497 pFOCC_Message_Counter "Description: Rolling Counter (ensures updated message is used).
Could not parse SPN data type, please add:Type: Status
Parsed from -014. ";
CM_ SG_ 2432658497 Drivers_Net_Engagement "Description: Broadcasting the status of the operator switch.  ";
CM_ SG_ 2432658497 Foot_On_Cruise_Control_Switch "Description: Broadcasting the status of the operator switch.  ";
CM_ SG_ 2432658497 Drive_Mode__1 "Description: Broadcasting the status of the operator switch.  ";
CM_ SG_ 2432658497 Momentary_Driveline_Left_Press "Description: Broadcasting the status of the operator switch.  ";
CM_ SG_ 2432658497 CylDeAc_Enable "Description: Broadcasting the status of the operator switch for CylDeAc. ";
CM_ SG_ 2432658497 Work_Group_Lock_Switch "Description: Broadcasting the status of the operator switch.  ";
CM_ SG_ 2432658497 Drivers_Seatbelt_Engagement "Description: Broadcasting the status of the operator switch.  ";
CM_ SG_ 2432658497 Drive_Mode__3 "Description: Broadcasting the status of the operator switch.  ";
CM_ SG_ 2432658497 Work_Mode_Switch "Description: Broadcasting the status of the operator switch.  ";
CM_ SG_ 2432658497 Momentary_Driveline_Right_Press "Description: Broadcasting the status of the operator switch.  ";
CM_ SG_ 2432658497 PTO_Mode_Switch_RPM_Control "Description: Broadcasting the status of the operator switch.  ";
CM_ SG_ 2432658497 Operator_Presence_Switch "Description: Broadcasting the status of the operator switch.  ";
CM_ SG_ 2432658497 Tilt_Lock_Switch "Description: Broadcasting the status of the operator switch.  ";
CM_ SG_ 2432658497 Engine_Brake_Enable "Description: Broadcasting the status of the operator switch for Engine Brake. ";
CM_ SG_ 2432658497 Accessory_Relay "Description: ";
CM_ BO_ 2566887489 "Name: pVehicle Load Information 1
Description: Parsed from -014. ";
CM_ SG_ 2566887489 pRider_Weight_Mid_Left "Description: Weight of occupant in middle left seat in kilograms. FE indicates Error. FF indicates data not available.
Could not parse SPN data type, please add:Type: User Defined
Parsed from -014. ";
CM_ SG_ 2566887489 pRider_Weight_Front_Left "Description: Weight of occupant in front left seat in kilograms. FE indicates Error. FF indicates data not available.
Could not parse SPN data type, please add:Type: User Defined
Parsed from -014. ";
CM_ SG_ 2566887489 pBox_Load_Weight "Description: Weight of load in box in kilograms. FE indicates Error. FF indicates data not available.
Could not parse SPN data type, please add:Type: User Defined
Parsed from -014. ";
CM_ SG_ 2566887489 pRider_Weight_Rear_Right "Description: Weight of occupant in rear right seat in kilograms. FE indicates Error. FF indicates data not available.
Could not parse SPN data type, please add:Type: User Defined
Parsed from -014. ";
CM_ SG_ 2566887489 pRider_Weight_Front_Right "Description: Weight of occupant in front right seat in kilograms. FE indicates Error. FF indicates data not available.
Could not parse SPN data type, please add:Type: User Defined
Parsed from -014. ";
CM_ SG_ 2566887489 pRider_Weight_Mid_Right "Description: Weight of occupant in middle right seat in kilograms. FE indicates Error. FF indicates data not available.
Could not parse SPN data type, please add:Type: User Defined
Parsed from -014. ";
CM_ SG_ 2566887489 pRider_Weight_Rear_Left "Description: Weight of occupant in rear left seat in kilograms. FE indicates Error. FF indicates data not available.
Could not parse SPN data type, please add:Type: User Defined
Parsed from -014. ";
CM_ BO_ 2566834753 "Name: Active Diagnostic Trouble Codes
Description:DM1 provides diagnostic lamp status and Diagnostic Trouble Codes (DTCs). Together, the lamp and DTC information
convey the diagnostic condition of the transmitting electronic component to other componen";
CM_ SG_ 2566834753 Flash_Malfunction_Indicator_Lamp "Description:This parameter provides the capability to flash the MIL. For OBD systems which are required to flash the SPN for specific malfunctions shall use the “slow flash” rate. 
See J1939-73 for complete reference
Pa";
CM_ SG_ 2566834753 Malfunction_Indicator_Lamp_Statu "Description:Used to relay only emissions-related trouble code information. This lamp is only illuminated when there is an emission-related trouble code active.
See J1939-71 for complete reference

Parsed from -014.";
CM_ SG_ 2566834753 Red_Stop_Lamp_Status "Description:Used to relay trouble code information that is of a severe enough condition that it warrants stopping the vehicle.
See J1939-71 for complete reference

Parsed from -014.";
CM_ SG_ 2566834753 Amber_Warning_Lamp_Status "Description:Used to relay trouble code information that is reporting a problem with the vehicle system but the vehicle need not be immediately stopped.
See J1939-71 for complete reference

Parsed from -014.";
CM_ SG_ 2566834753 Flash_Red_Stop_Lamp_RSL "Description:This parameter provides the capability to flash the RSL.
See J1939-73 for complete reference
Parsed from -014.";
CM_ SG_ 2566834753 Flash_Amber_Warning_Lamp_AWL "Description:This parameter provides the capability to flash the AWL. 
See J1939-73 for complete reference
Parsed from -014.";
CM_ SG_ 2566834753 Flash_Protect_Lamp "Description:This parameter provides the capability to flash the protect lamp. 
See J1939-73 for complete reference
Parsed from -014.";
CM_ SG_ 2566834753 Protect_Lamp_Status "Description:Used to relay trouble code information that is reporting a problem with a vehicle system that is most probably not electronic subsystem related. For instance, engine coolant temperature is exceeding its prescribed temperat";
CM_ SG_ 2566834753 DTC_1 "Description:This signal is a combination of 4 SPNs. To decode this signal, navigate to MCS tools.
Byte: 1 bits 8-1 SPN, 8 least significant bits of SPN (most significant at bit 8, SPN 1214)
Byte: 2 bits 8-1 SPN, second byte of SPN (most significa";
CM_ SG_ 2566834753 DTC_2 "Description:This signal is a combination of 4 SPNs. To decode this signal, navigate to MCS tools.
Byte: 1 bits 8-1 SPN, 8 least significant bits of SPN (most significant at bit 8, SPN 1214)
Byte: 2 bits 8-1 SPN, second byte of SPN (most significa";
CM_ SG_ 2566834753 DTC_3 "Description:This signal is a combination of 4 SPNs. To decode this signal, navigate to MCS tools.
Byte: 1 bits 8-1 SPN, 8 least significant bits of SPN (most significant at bit 8, SPN 1214)
Byte: 2 bits 8-1 SPN, second byte of SPN (most significa";
CM_ SG_ 2566834753 DTC_4 "Description:This signal is a combination of 4 SPNs. To decode this signal, navigate to MCS tools.
Byte: 1 bits 8-1 SPN, 8 least significant bits of SPN (most significant at bit 8, SPN 1214)
Byte: 2 bits 8-1 SPN, second byte of SPN (most significa";
CM_ SG_ 2566834753 DTC_5 "Description:This signal is a combination of 4 SPNs. To decode this signal, navigate to MCS tools.
Byte: 1 bits 8-1 SPN, 8 least significant bits of SPN (most significant at bit 8, SPN 1214)
Byte: 2 bits 8-1 SPN, second byte of SPN (most significa";
CM_ SG_ 2566834753 DTC_6 "Description:This signal is a combination of 4 SPNs. To decode this signal, navigate to MCS tools.
Byte: 1 bits 8-1 SPN, 8 least significant bits of SPN (most significant at bit 8, SPN 1214)
Byte: 2 bits 8-1 SPN, second byte of SPN (most significa";
CM_ SG_ 2566834753 DTC_7 "Description:This signal is a combination of 4 SPNs. To decode this signal, navigate to MCS tools.
Byte: 1 bits 8-1 SPN, 8 least significant bits of SPN (most significant at bit 8, SPN 1214)
Byte: 2 bits 8-1 SPN, second byte of SPN (most significa";
CM_ SG_ 2566834753 DTC_8 "Description:This signal is a combination of 4 SPNs. To decode this signal, navigate to MCS tools.
Byte: 1 bits 8-1 SPN, 8 least significant bits of SPN (most significant at bit 8, SPN 1214)
Byte: 2 bits 8-1 SPN, second byte of SPN (most significa";
CM_ SG_ 2566834753 DTC_9 "Description:This signal is a combination of 4 SPNs. To decode this signal, navigate to MCS tools.
Byte: 1 bits 8-1 SPN, 8 least significant bits of SPN (most significant at bit 8, SPN 1214)
Byte: 2 bits 8-1 SPN, second byte of SPN (most significa";
CM_ SG_ 2566834753 DTC_10 "Description:This signal is a combination of 4 SPNs. To decode this signal, navigate to MCS tools.
Byte: 1 bits 8-1 SPN, 8 least significant bits of SPN (most significant at bit 8, SPN 1214)
Byte: 2 bits 8-1 SPN, second byte of SPN (most signific";
CM_ BO_ 2432656449 "Name: pInfotainment System Control
Description: Parsed from -014. ";
CM_ SG_ 2432656449 Source "Description: This group of SPN&rsquo;s contain the information for the Infotainment System Control. See PGN 65380 breakdown for definition of each button. ";
CM_ SG_ 2432656449 Squelch_SQ_Up "Description: This group of SPN&rsquo;s contain the information for the Infotainment System Control. See PGN 65380 breakdown for definition of each button. ";
CM_ SG_ 2432656449 MutePreset "Description: This group of SPN&rsquo;s contain the information for the Infotainment System Control. See PGN 65380 breakdown for definition of each button. ";
CM_ SG_ 2432656449 Volume_Down "Description: This group of SPN&rsquo;s contain the information for the Infotainment System Control. See PGN 65380 breakdown for definition of each button. ";
CM_ SG_ 2432656449 Volume_Up "Description: This group of SPN&rsquo;s contain the information for the Infotainment System Control. See PGN 65380 breakdown for definition of each button. ";
CM_ SG_ 2432656449 Tune_Up "Description: This group of SPN&rsquo;s contain the information for the Infotainment System Control. See PGN 65380 breakdown for definition of each button. ";
CM_ SG_ 2432656449 Seek_Up "Description: This group of SPN&rsquo;s contain the information for the Infotainment System Control. See PGN 65380 breakdown for definition of each button. ";
CM_ SG_ 2432656449 Tune_Down "Description: This group of SPN&rsquo;s contain the information for the Infotainment System Control. See PGN 65380 breakdown for definition of each button. ";
CM_ SG_ 2432656449 Squelch_SQ_Down "Description: This group of SPN&rsquo;s contain the information for the Infotainment System Control. See PGN 65380 breakdown for definition of each button. ";
CM_ SG_ 2432656449 pInfotainment_Joystick_1 "Description: Switch signal indicating status of infotainment joystick 1 buttons. ";
CM_ SG_ 2432656449 Preset "Description: This group of SPN&rsquo;s contain the information for the Infotainment System Control. See PGN 65380 breakdown for definition of each button. ";
CM_ SG_ 2432656449 Seek_Down "Description: This group of SPN&rsquo;s contain the information for the Infotainment System Control. See PGN 65380 breakdown for definition of each button. ";
CM_ SG_ 2432656449 pInfotainment_Joystick_2 "Description: Switch signal indicating status of infotainment joystick 2 buttons. ";
CM_ SG_ 2432656449 ICOM "Description: This group of SPN&rsquo;s contain the information for the Infotainment System Control. See PGN 65380 breakdown for definition of each button. ";
CM_ SG_ 2432656449 Push_To_Talk_PTT "Description: This group of SPN&rsquo;s contain the information for the Infotainment System Control. See PGN 65380 breakdown for definition of each button. ";
CM_ SG_ 2432656449 pMultifunction_Infotainment_Inte "Description: Switch status indicating the state of the multi-function infotainment button.

 ";
CM_ SG_ 2432656449 COM "Description: This group of SPN&rsquo;s contain the information for the Infotainment System Control. See PGN 65380 breakdown for definition of each button. ";
CM_ SG_ 2432656449 PlayPause "Description: This group of SPN&rsquo;s contain the information for the Infotainment System Control. See PGN 65380 breakdown for definition of each button. ";
CM_ BO_ 2566832449 "Name: High Resolution Vehicle Distance
Description: Parsed from -014. ";
CM_ SG_ 2566832449 Total_Vehicle_Distance_High_Reso "Description:Accumulated distance traveled by the vehicle during its operation. NOTE - See SPN 245 for alternate resolution.
Note: Parsed from J1939DA.";
CM_ SG_ 2566832449 Trip_Distance_High_Resolution "Description:Distance traveled during all or part of a journey. NOTE - See SPN 244 for alternate resolution.
Note: Parsed from J1939DA.";
CM_ BO_ 2432656705 "Name: pOperator Switch Status
Description: Parsed from -014. ";
CM_ SG_ 2432656705 Key_Fob_Unlock_Button_Status "Description: These group of SPN&rsquo;s contain the information for the Operator Switches. See PGN 65380 breakdown for definition of each button. ";
CM_ SG_ 2432656705 Homelink_2 "Description: These group of SPN&rsquo;s contain the information for the Operator Switches. See PGN 65380 breakdown for definition of each button. ";
CM_ SG_ 2432656705 Side_Stand_Switch "Description: ";
CM_ SG_ 2432656705 Key_Fob_Lock_Button_Status "Description: These group of SPN&rsquo;s contain the information for the Operator Switches. See PGN 65380 breakdown for definition of each button. ";
CM_ SG_ 2432656705 Windshield__2_Down "Description: These group of SPN&rsquo;s contain the information for the Operator Switches. See PGN 65380 breakdown for definition of each button. ";
CM_ SG_ 2432656705 Turn__3_Cancel "Description: These group of SPN&rsquo;s contain the information for the Operator Switches. See PGN 65380 breakdown for definition of each button. ";
CM_ SG_ 2432656705 Reverse "Description: These group of SPN&rsquo;s contain the information for the Operator Switches. See PGN 65380 breakdown for definition of each button. ";
CM_ SG_ 2432656705 Hazard "Description: These group of SPN&rsquo;s contain the information for the Operator Switches. See PGN 65380 breakdown for definition of each button. ";
CM_ SG_ 2432656705 Homelink_1 "Description: These group of SPN&rsquo;s contain the information for the Operator Switches. See PGN 65380 breakdown for definition of each button. ";
CM_ SG_ 2432656705 Windshield__1_Up "Description: These group of SPN&rsquo;s contain the information for the Operator Switches. See PGN 65380 breakdown for definition of each button. ";
CM_ SG_ 2432656705 Front_Brake_Switch "Description: Indicates the status of the front brake switch ";
CM_ SG_ 2432656705 Instrument_Cluster_Control__2 "Description: These group of SPN&rsquo;s contain the information for the Operator Switches. See PGN 65380 breakdown for definition of each button. ";
CM_ SG_ 2432656705 Chassis_Unlock_Button_Status "Description: These group of SPN&rsquo;s contain the information for the Operator Switches. See PGN 65380 breakdown for definition of each button. ";
CM_ SG_ 2432656705 Power_Button "Description: These group of SPN&rsquo;s contain the information for the Operator Switches. See PGN 65380 breakdown for definition of each button. ";
CM_ SG_ 2432656705 RunStop_Switch "Description: These group of SPN&rsquo;s contain the information for the Operator Switches. See PGN 65380 breakdown for definition of each button. ";
CM_ SG_ 2432656705 Headlamp__2_High "Description: These group of SPN&rsquo;s contain the information for the Operator Switches. See PGN 65380 breakdown for definition of each button. ";
CM_ SG_ 2432656705 Instrument_Cluster_Control__1 "Description: These group of SPN&rsquo;s contain the information for the Operator Switches. See PGN 65380 breakdown for definition of each button. ";
CM_ SG_ 2432656705 Clutch_Switch "Description: These group of SPN&rsquo;s contain the information for the Operator Switches. See PGN 65380 breakdown for definition of each button. ";
CM_ SG_ 2432656705 Start "Description: These group of SPN&rsquo;s contain the information for the Operator Switches. See PGN 65380 breakdown for definition of each button. ";
CM_ SG_ 2432656705 Headlamp__3_Driving "Description: These group of SPN&rsquo;s contain the information for the Operator Switches. See PGN 65380 breakdown for definition of each button. ";
CM_ SG_ 2432656705 Cruise__2_Set "Description: These group of SPN&rsquo;s contain the information for the Operator Switches. See PGN 65380 breakdown for definition of each button. ";
CM_ SG_ 2432656705 Windshield_Wiper "Description: These group of SPN&rsquo;s contain the information for the Operator Switches. See PGN 65380 breakdown for definition of each button. ";
CM_ SG_ 2432656705 Fog "Description: These group of SPN&rsquo;s contain the information for the Operator Switches. See PGN 65380 breakdown for definition of each button. ";
CM_ SG_ 2432656705 Cruise__3_Accel "Description: These group of SPN&rsquo;s contain the information for the Operator Switches. See PGN 65380 breakdown for definition of each button. ";
CM_ SG_ 2432656705 Horn "Description: These group of SPN&rsquo;s contain the information for the Operator Switches. See PGN 65380 breakdown for definition of each button. ";
CM_ SG_ 2432656705 Turn__2_Right "Description: These group of SPN&rsquo;s contain the information for the Operator Switches. See PGN 65380 breakdown for definition of each button. ";
CM_ SG_ 2432656705 Cruise__1_On "Description: These group of SPN&rsquo;s contain the information for the Operator Switches. See PGN 65380 breakdown for definition of each button. ";
CM_ SG_ 2432656705 Turn__1_Left "Description: These group of SPN&rsquo;s contain the information for the Operator Switches. See PGN 65380 breakdown for definition of each button. ";
CM_ SG_ 2432656705 Throttle_Safety_Switch__1 "Description: These group of SPN&rsquo;s contain the information for the Operator Switches. See PGN 65380 breakdown for definition of each button. ";
CM_ SG_ 2432656705 Headlamp__1_Low "Description: These group of SPN&rsquo;s contain the information for the Operator Switches. See PGN 65380 breakdown for definition of each button. ";
CM_ SG_ 2432656705 Chassis_Lock_Switch_Status "Description:Created due to CMS fault code using this SPN";
CM_ SG_ 2432656705 Fuel_Door_Unlock_Button_Status "Description:Displays the status of the Fuel Door Unlock button. See PGN 65380 breakdown for the definition of each button.";
CM_ BO_ 2566877505 "Name: pCluster Status 1
Description: Parsed from -014. ";
CM_ SG_ 2566877505 pTemperature_Units_Selected "Description: Active display temperature units beased on user selection or auto-configuration. ";
CM_ SG_ 2566877505 pTPMS_Learning_Status "Description: Indicates the status of the tire pressure monitoring sensor learning process. ";
CM_ SG_ 2566877505 pPressure_Units_Selected "Description: Active display pressure units beased on user selection or auto-configuration. ";
CM_ SG_ 2566877505 pHigh_Res_Trip_2_Distance "Description: Secondary distance travled during all or part of a journey.
Could not parse SPN data type, please add:Type: Measured
Parsed from -014. ";
CM_ SG_ 2566877505 pVolume_Units_Selected "Description: Active display volume units beased on user selection or auto-configuration. ";
CM_ SG_ 2566877505 pDisplay_Status "Description: Status of display. ";
CM_ SG_ 2566877505 pTime_Units_Selected "Description: Active display time units beased on user selection or auto-configuration. ";
CM_ SG_ 2566877505 pDistance_Units_Selected "Description: Active display distance units beased on user selection or auto-configuration. ";
CM_ BO_ 2566882113 "Name: pSeat Status and Control
Description: Parsed from -014. ";
CM_ SG_ 2566882113 pDriver_HeatedCooled_Seat_Enable "Description: This signal indicates the status of the Driver Heated/Cooled Seat Enable Button. ";
CM_ SG_ 2566882113 pDriver_HeatedCooled_Seat_Down_B "Description: This signal indicates the status of the Driver Seat Temperature Down Button. ";
CM_ SG_ 2566882113 pPassenger_HeatedCooled_Seat_Ena "Description: This signal indicates the status of the Passenger Heated/Cooled Seat Enable Button. ";
CM_ SG_ 2566882113 pPassenger_HeatedCooled_Seat_Up_ "Description: This signal indicates the status of the Passenger Seat Temperature Up Button. ";
CM_ SG_ 2566882113 pPassenger_HeatedCooled_Seat_Per "Description: Current level of Heating or Cooling output of the Driver seat on a vehicle. Positive values are Heat level, Negative values are Cooling level, and 0 is Off.
Could not parse SPN data type, please add:Type: St";
CM_ SG_ 2566882113 pPassenger_HeatedCooled_Seat_Dow "Description: This signal indicates the status of the Passenger Seat Temperature Down Button. ";
CM_ SG_ 2566882113 pDriver_HeatedCooled_Seat_Percen "Description: Current level of Heating or Cooling output of the Driver seat on a vehicle. Positive values are Heat level, Negative values are Cooling level, and 0 is Off.
Could not parse SPN data type, please add:Type: St";
CM_ SG_ 2566882113 pDriver_HeatedCooled_Seat_Up_But "Description: This signal indicates the status of the Driver Seat Temperature Up Button. ";
CM_ BO_ 2631794497 "Name: Anti-Theft Request
Description: Parsed from -014. ";
CM_ SG_ 2631794497 Antitheft_Desired_Exit_Mode_Stat "Description:This parameter is used to specify the desired triggers that are to be used by the component in deciding when to transition to the Locked state. 00b = Lock_Upon_Operator_Request 01b = Lock_When_Key_Off 10b = No";
CM_ SG_ 2631794497 Antitheft_Encryption_Indicator_S "Description:This parameter is used to indicate if a random number seed is being requested, or if an encrypted password is being provided to the component. 00b = Encryption_Seed_Request 01b = Encrypted_Code_Present 10b = N";
CM_ SG_ 2631794497 Antitheft_Command_States "Description:This parameter is used to identify the specific requests being sent to the component. 000b = Add_Password 001b = Delete_Password 010b = Change_Password 011b = Lock_or_Unlock 100b = Check_Status 101b = Login 110b = Not";
CM_ SG_ 2631794497 Antitheft_Password_Representatio "Description:This parameter is the seven byte numeric code (i.e., 'encrypted password' or 'key') that is generated based on the encryption algorithm, the password supplied by the end user, and the random number seed given ";
CM_ BO_ 2365530202 "Name: pTorque/Speed Control
Description: Used to request/limit torque and speed of an engine or motor. To be used with PGN 65313 and PGN 65314.
Parsed from -014. ";
CM_ SG_ 2365530202 pMessage_Counter "Description: Message counter that increments by one for each transmission from 0 to 15 and then rolls over.
Could not parse SPN data type, please add:Type: Status
Parsed from -014. ";
CM_ SG_ 2365530202 pRequested_Engine_TorqueTorque_L "Description: This is the value used when the pEngine Control Mode is in a torque request or limit mode. This value shall be ignored by the controller when pEngine Control Mode is set to No Control Request, Engine Speed Re";
CM_ SG_ 2365530202 pEngine_Control_Mode "Description: Used to tell the engine or motor controller the type of torque/speed request or limit to use. ";
CM_ SG_ 2365530202 pRequested_Engine_SpeedSpeed_Lim "Description: This is the value used when the pEngine Control Mode is in a speed request or limit mode. This value shall be ignored by the controller when pEngine Control Mode is set to No Control Request, Engine Torque Re";
CM_ SG_ 2365530202 WheelBased_Vehicle_Speed "Description:Speed of the vehicle as calculated from wheel or tailshaft speed.
Note: Parsed from J1939DA.";
CM_ SG_ 2365530202 pEngine_Control_Requestor "Description: Used to tell the engine or motor controller what function is the requestor of the torque/speed request or limit. ";
CM_ SG_ 2365530202 pMessage_Checksum "Description: Message checksum that is calculated as follows:
Intermediate Checksum =
Byte1 + Byte2 + Byte3 + Byte4 + Byte5 + Byte6 + Byte7 + (Message Counter & 0x0F) + Message ID Low Byte + Message ID Mid Low Byte + Message ID Mid Hig";
CM_ BO_ 2565866842 "Name: Electronic Transmission Controller
Description: Parsed from -014. ";
CM_ SG_ 2565866842 Transmission_Actual_Gear_Ratio "Description:Actual ratio of input shaft speed to output shaft speed.
Note: Parsed from J1939DA.";
CM_ SG_ 2565866842 Transmission_Requested_Range "Description:Range selected by the operator. Characters may include P, Rx, Rx-1...R2, R1, R, Nx, Nx-1...N2, N1, N, D, D1, D2..., Dx, L, L1, L2..., Lx-1, 1, 2, 3,... If only one displayed character is required, the second chara";
CM_ SG_ 2565866842 Transmission_Current_Range "Description:Range currently being commanded by the transmission control system. Characters may include P, Rx, Rx-1...R2, R1, R, Nx, Nx-1...N2, N1, N, D, D1, D2..., Dx, L, L1, L2..., Lx-1, 1, 2, 3,... If only one displayed chara";
CM_ SG_ 2565866842 Transmission_Current_Gear "Description:The gear currently engaged in the transmission or the last gear engaged while the transmission is in the process of shifting to the new or selected gear. Transitions toward a destination gear will not be indicated. O";
CM_ SG_ 2565866842 Transmission_Selected_Gear "Description:The gear that the transmission will attempt to achieve during the current shift if a shift is in progress, or the next shift if one is pending (i.e., waiting for torque reduction to initiate the shift). Negative val";
CM_ BO_ 2231304282 "Name: pElectric Propulsion Control Unit #2
Description: Second on-board device converting torque commands to current commands in an electric vehicle system. This contains the mode in which the Propulsion Control Unit is commanded as well as the variable";
CM_ SG_ 2231304282 pEPCU2_Message_Counter "Description: Counter to verify latest message, counts 0-15

Could not parse SPN data type, please add:Type: Measured
Parsed from -014. ";
CM_ SG_ 2231304282 pEPCU2_Counter_Limit_Torque "Description: Counter torque limit value to the electric propulsion control unit (motor controller)
Could not parse SPN data type, please add:Type: Measured
Parsed from -014. ";
CM_ SG_ 2231304282 pElectric_Propulsion_Control_Uni "Description: Bits dictating the commanded control mode of the second on-board device converting torque commands to current commands in an electric vehicle system. ";
CM_ SG_ 2231304282 pEPCU_2_Check_Sequence "Description: Checksum is calculated by taking XOR of bytes from 1 to 7.
Could not parse SPN data type, please add:Type: Status
Parsed from -014. ";
CM_ SG_ 2231304282 pEPCU2_Torque_Demand "Description: Commanded Torque value to the electric propulsion control unit (motor controller)

Could not parse SPN data type, please add:Type: Measured
Parsed from -014. ";
CM_ SG_ 2231304282 pEPCU2_Speed_Limit "Description: Speed limit value to the electric propulsion control unit (motor controller)

Could not parse SPN data type, please add:Type: Measured
Parsed from -014. ";
CM_ BO_ 2566802010 "Name: Electronic Transmission Controller 7
Description: Parsed from -014. ";
CM_ SG_ 2566802010 Transmission_Ready_for_Brake_Rel "Description:This parameter indicates that enough torque / motive force is available at the transmission output shaft to release all the brakes without a risk of unintentional movement in the opposite direction. 00b = Tran";
CM_ SG_ 2566802010 Transmission_Shift_Inhibit_Indic "Description:State signal indicating a transmission request for the Shift Inhibit Indicator to be active or inactive. The shift inhibit indicator can be of lamp or text form, located on (but not limited to) the shift conso";
CM_ SG_ 2566802010 Transmission_Mode_3_Indicator "Description:This state signal is the transmission's indication that it is operating under transmission mode 3 (SPN 1854) as commanded via the TC1 message (PGN 256). The definition of the transmission mode is left to the disc";
CM_ SG_ 2566802010 Transmission_Requested_Range_Dis "Description:State signal indicating a transmission request for the display of the Transmission Requested Range parameter (SPN162) to be blanked or not blanked. The 'Transmission Requested Range Display Blank State' indica";
CM_ SG_ 2566802010 Transmission_Mode_2_Indicator "Description:This state signal is the transmission's indication that it is operating under transmission mode 2 (SPN 1853) as commanded via the TC1 message (PGN 256). The definition of the transmission mode is left to the disc";
CM_ SG_ 2566802010 Transmission_Requested_Range_Dis "Description:State signal indicating a transmission request for the display of the Transmission Requested Range parameter (SPN 162) to flash or not to flash. The 'Transmission Requested Range Display Flash State' indicator";
CM_ SG_ 2566802010 pTransmission_Mode_5_Indicator "Description: This state signal is the transmission&rsquo;s indication that it is operating under transmission mode 5, as commanded via the TC1 message (pgn256, spn523998). ";
CM_ SG_ 2566802010 Transmission_Requested_Gear_Feed "Description:Feedback of the SPN 525 Transmission Requested Gear input as received from the shift selector, ABS or engine via PGN 256, Transmission Control 1 (TC1) or other transmission selector input. Scaling, values and ";
CM_ SG_ 2566802010 pMessageChecksum "Description: Used to verify the signal path from Transmitter up to the Application Software layer of the Receiver.
Calculated using the CRC8 0xEA Polynomial formula. Data used in calculation is [Message ID][Data Bytes 1-7].
Could not p";
CM_ SG_ 2566802010 Transmission_Mode_1_Indicator "Description:This state signal is the transmission's indication that it is operating under transmission mode 1 (SPN 1852) as commanded via the TC1 message (PGN 256). The definition of the transmission mode is left to the disc";
CM_ SG_ 2566802010 Active_Shift_Console_Indicator "Description:Signal from transmission control unit indicating which shift console (primary or secondary) it currently considers as the active shift selector input. 00b = Primary shift console is active 01b = Secondary shift ";
CM_ SG_ 2566802010 pMessageCounter "Description: Used to verify the signal path from Transmitter up to the Application Software layer of the Receiver.
Transmitter increments the count for every message transmission, automatically rolling over at 15.
Could not parse offset";
CM_ SG_ 2566802010 Transmission_Mode_4_Indicator "Description:This state signal is the transmission's indication that it is operating under transmission mode 4 (SPN 1855) as commanded via the TC1 message (PGN 256). The definition of the transmission mode is left to the disc";
CM_ SG_ 2566802010 Transmission_Engine_Crank_Enable "Description:State signal from the transmission indicating if the transmission's status is such that engine cranking is allowed (i.e. at a minimum, transmission is in neutral and the driveline is disengaged). As sender of ";
CM_ BO_ 2231309146 "Name: EPCU #1 Torque Control Message
Description: First or only on-board device converting torque commands to current commands in an electric vehicle system. This contains the mode in which the Propulsion Control Unit is commanded as well as the variabl";
CM_ SG_ 2231309146 pEPCU1_Message_Counter "Description: Counter to verify latest message, counts 0-15

Could not parse SPN data type, please add:Type: Measured
Parsed from -014. ";
CM_ SG_ 2231309146 pElectric_Propulsion_Control_Uni "Description: Bits dictating the commanded control mode of the first or only on-board device converting torque commands to current commands in an electric vehicle system. ";
CM_ SG_ 2231309146 pEPCU1_Torque_Demand "Description: Commanded Torque value to the electric propulsion control unit (motor controller)

Could not parse SPN data type, please add:Type: Measured
Parsed from -014. ";
CM_ SG_ 2231309146 pEPCU1_Counter_Limit_Torque "Description: Counter torque limit value to the electric propulsion control unit (motor controller)
Could not parse SPN data type, please add:Type: Measured
Parsed from -014. ";
CM_ SG_ 2231309146 pEPCU1_Speed_Limit "Description: Speed limit value to the electric propulsion control unit (motor controller)

Could not parse SPN data type, please add:Type: Measured
Parsed from -014. ";
CM_ SG_ 2231309146 pTorque_Message_Checksum "Description: Checksum is calculated by taking XOR of bytes from 1 to 7.
Could not parse SPN data type, please add:Type: Status
Parsed from -014. ";
CM_ BO_ 2566844762 "Name: Cruise Control Vehicle Speed 1
Description: Parsed from -014. ";
CM_ SG_ 2566844762 Cruise_Control_Set_Speed "Description:Value of set (chosen) velocity of velocity control system. See SPN 6809 for an alternate resolution. If an algorithm that can modify the cruise control set point exists in the system, such as Predictive Cruise Control";
CM_ SG_ 2566844762 Cruise_Control_Active "Description:Cruise control is switched on. It is not ensured that the engine is controlled by cruise control, as in the case of a large driver's demand the engine is controlled by the driver while cruise control is active (maximum s";
CM_ SG_ 2566844762 Clutch_Switch "Description:Switch signal which indicates that the clutch pedal is being pressed. It is necessary for a safe drivetrain behavior that the clutch switch is set before the clutch is opened (cruise control function). 00b = Clutch pedal release";
CM_ SG_ 2566844762 Brake_Switch "Description:Switch signal which indicates that the driver operated brake foot pedal is being pressed. This brake foot pedal is controlling the vehicles' service brake (total vehicle braking application, not park brakes). It is necessary for ";
CM_ SG_ 2566844762 pCC_Message_Counter "Description: Rolling Counter (ensures updated message is used).
Could not parse SPN data type, please add:Type: Status
Parsed from -014. ";
CM_ SG_ 2566844762 Cruise_Control_Pause_Switch "Description:Switch signal which indicates the position of the Cruise Control Pause Switch used on Remote Cruise Control applications. The Cruise Control Pause Switch signal temporarily disables the Cruise Control function. 00b";
CM_ SG_ 2566844762 Cruise_Control_Set_Switch "Description:Switch signal of the cruise control activator which indicates that the activator is in the position set. 00b = Cruise control activator not in the position set 01b = Cruise control activator in position set 10b = Err";
CM_ SG_ 2566844762 Two_Speed_Axle_Switch "Description:Switch signal which indicates the current axle range. 00b = Low speed range 01b = High speed range 10b = Error 11b = Not available
Note: Parsed from J1939DA.";
CM_ SG_ 2566844762 Cruise_Control_Enable_Switch "Description:Switch signal which indicates that it is possible to manage the cruise control function. 00b = Cruise control disabled 01b = Cruise control enabled 10b = Error 11b = Not available
Note: Parsed from J1939DA.";
CM_ SG_ 2566844762 pOdometer_Drive_Bit "Description: Each State A->B or B->A change indicates the vehicle has moved 40 m since the previous one. However, since the message is sent at regular 100 ms intervals, State A and B each occur multiple times consecutively (a minimum ";
CM_ SG_ 2566844762 pCC_Checksum "Description: XOR of bytes 0-6 (ensures data is valid before use). 
Could not parse SPN data type, please add:Type: Status
Parsed from -014. ";
CM_ SG_ 2566844762 WheelBased_Vehicle_Speed "Description:Speed of the vehicle as calculated from wheel or tailshaft speed.
Note: Parsed from J1939DA.";
CM_ SG_ 2566844762 Cruise_Control_Resume_Switch "Description:Switch signal of the cruise control activator which indicates that the activator is in the position resume. 00b = Cruise control activator not in the position resume 01b = Cruise control activator in position resu";
CM_ SG_ 2566844762 Cruise_Control_Accelerate_Switch "Description:Switch signal of the cruise control activator which indicates that the activator is in the position accelerate. 00b = Cruise control activator not in the position accelerate 01b = Cruise control activator in p";
CM_ SG_ 2566844762 pCruise_Enable_Status "Description: The Cruise Control System has been enabled by the operator. (Amber Light) ";
CM_ SG_ 2566844762 Parking_Brake_Switch "Description:Switch signal which indicates when the parking brake is set. In general the switch actuated by the operator's park brake control, whether a pedal, lever or other control mechanism (see also SPN 619 and 5275). 00b = Parkin";
CM_ SG_ 2566844762 Cruise_Control_Coast_Decelerate_ "Description:Switch signal of the cruise control activator which indicates that the activator is in the position coast (decelerate). 00b = Cruise control activator not in the position coast 01b = Cruise control activator i";
CM_ BO_ 2365428314 "Name: Engine Operating Information
Description:Parsed from -014.";
CM_ SG_ 2365428314 Fuel_Pump_Primer_Control "Description:Parameter used to activate or deactivate a priming system on the fuel transfer system. The fuel priming system is a system that purges air in the fuel lines and may assist fuel delivery to a second pump at lower speed";
CM_ SG_ 2365428314 Engine_Operating_State "Description:This parameter is used to indicate the current state, or mode, of operation by the engine. This is a status parameter. 0000b = Engine Stopped 0001b = Pre-Start 0010b = Starting 0011b = Warm-Up 0100b = Running 0101b = Co";
CM_ SG_ 2365428314 Engine_Fuel_Shutoff_1_Control "Description:Control setting for fuel shutoff 1. The second instance is SPN 2807. For a single fuel shutoff system, this represents its commanded position. For a dual fuel shutoff system, this SP is representative of the upst";
CM_ BO_ 2431708506 "Name: Engine Start Control (ENGSC)
Description: Parsed from -014. ";
CM_ SG_ 2431708506 Engine_Starter_2_Feedback "Description:Feedback of the current state of second engine starter. This signal is intended to be used by the arbitrator as feedback to its command signal (SPN 7753). Additional details regarding the starter state may be availab";
CM_ SG_ 2431708506 Engine_Start_Request "Description:Indicates the sender's desire to start the engine. The engine start arbitrator latches this signal and, if possible, completes the engine start regardless of a change of state of this signal. Use Engine Start Abort Reques";
CM_ SG_ 2431708506 Engine_Start_Abort_Request "Description:Indicates the sender's desire to abort an engine start. This signal is used by requesters and consenters to request that the arbitrator cancel an engine start that is in progress. The sender of this signal may incre";
CM_ SG_ 2431708506 Engine_Start_Control_Checksum "Description:Checksum to allow detection of data integrity issues. The receiving node shall calculate the checksum and compare its calculated value with the received checksum. In case of a mismatch the message shall be discar";
CM_ SG_ 2431708506 Transmission_Shift_Selector_Requ "Description:This parameter indicates the direction selected by the operator via the active transmission shift selector. Some regulations (e.g., Federal Motor Vehicle Safety Standards 102) require specific Engine Stop-Star";
CM_ SG_ 2431708506 Engine_Start_Control_Message_Cou "Description:Message counter to allow detection of data integrity issues. The counter is incremented every time a device sends out the Engine Start Control message. When the counter has reached a value of 15 it starts over";
CM_ SG_ 2431708506 Engine_Start_Consent "Description:Indicates the sender's consent to start the engine for different start types. An operator-requested engine start is a start that is initiated directly by the operator (i.e. via the key switch). An automatic engine start i";
CM_ SG_ 2431708506 Engine_Starter_1_Feedback "Description:Feedback of the current state of first engine starter. This signal is intended to be used by the arbitrator as feedback to its command signal (SPN 7753). Additional details regarding the starter state may be availabl";
CM_ BO_ 2566853722 "Name: pWatt Message
Description: Contains information used on the Watt platform for electrical characteristics of the vehicle.
Parsed from -014. ";
CM_ SG_ 2566853722 pEfficiency_LEV "Description: Calculated efficiency of an electric powertrain vehicle.
Could not parse SPN data type, please add:Type: Calculated
Parsed from -014. ";
CM_ SG_ 2566853722 pInstantaneous_Efficiency_LEV "Description: Calculated efficiency of an electric powertrain vehicle, averaged over a shorter time period than pEfficiency (SPN 520528).
Could not parse SPN data type, please add:Type: Calculated
Parsed from -014. ";
CM_ SG_ 2566853722 pRange_to_Empty_LEV "Description: Calculated range on remaining electrical power
Could not parse SPN data type, please add:Type: Calculated
Parsed from -014. ";
CM_ BO_ 2231341402 "Name: Remote Feedback 3
Description:Communicated on the external communication bus.  Contains signals to provide information about the current state of the powertrain system and electric system state of charge.";
CM_ SG_ 2231341402 Driveline_Mode "Description:Signal to provide the current driveline mode.

States
0000b: 2WD
0001b: AWD
0010b: ADC (ADC1)
0011b: TURF
0100b: Ultra TURF (3WD)
0101b: ADC2
0110b: ADC3
0111b-1101b: Reserved for Future Use
1110b: Error
1111b: Not ";
CM_ SG_ 2231341402 Powertrain_Mode "Description:Signal to provide the current powertrain mode in a hybrid application.

States
0000b â€“ Hybrid Mode (Default) 
0001b â€“ Full Power Mode
0010b â€“ Charge Maintain Mode
0011b â€“ EV Mode
0100b-1101b â€“ Reserved for Future Use";
CM_ SG_ 2231341402 Transmission_Current_Range "Description:Signal to provide information about the current transmission gear and/or direction.

States
0x2050 â€“ â€˜ Pâ€™ â€“ Park
0x2052 â€“ â€˜ Râ€™ â€“ Reverse
0x204E â€“ â€˜ Nâ€™ â€“ Neutral
0x204C â€“ â€˜ Lâ€™ â€“ Low
0x";
CM_ SG_ 2231341402 Fuel_Level "Description:Signal to provide the current fuel level. 0% is empty; 100% is full.
Units:			%Could not parse offset, please add:Offset:		0
Could not parse SPN data type, please add:Type:			
Parsed from Confidential -014.";
CM_ SG_ 2231341402 State_of_Charge "Description:Signal to provide the current state of charge of the battery packs.
Units:			%Could not parse offset, please add:Offset:		0
Could not parse SPN data type, please add:Type:			
Parsed from Confidential -014.";
CM_ BO_ 2566834808 "Name: Active Diagnostic Trouble Codes
Description:DM1 provides diagnostic lamp status and Diagnostic Trouble Codes (DTCs). Together, the lamp and DTC information
convey the diagnostic condition of the transmitting electronic component to other componen";
CM_ SG_ 2566834808 Flash_Malfunction_Indicator_Lamp "Description:This parameter provides the capability to flash the MIL. For OBD systems which are required to flash the SPN for specific malfunctions shall use the “slow flash” rate. 
See J1939-73 for complete reference
Pa";
CM_ SG_ 2566834808 Malfunction_Indicator_Lamp_Statu "Description:Used to relay only emissions-related trouble code information. This lamp is only illuminated when there is an emission-related trouble code active.
See J1939-71 for complete reference

Parsed from -014.";
CM_ SG_ 2566834808 Red_Stop_Lamp_Status "Description:Used to relay trouble code information that is of a severe enough condition that it warrants stopping the vehicle.
See J1939-71 for complete reference

Parsed from -014.";
CM_ SG_ 2566834808 Amber_Warning_Lamp_Status "Description:Used to relay trouble code information that is reporting a problem with the vehicle system but the vehicle need not be immediately stopped.
See J1939-71 for complete reference

Parsed from -014.";
CM_ SG_ 2566834808 Flash_Red_Stop_Lamp_RSL "Description:This parameter provides the capability to flash the RSL.
See J1939-73 for complete reference
Parsed from -014.";
CM_ SG_ 2566834808 Flash_Amber_Warning_Lamp_AWL "Description:This parameter provides the capability to flash the AWL. 
See J1939-73 for complete reference
Parsed from -014.";
CM_ SG_ 2566834808 Flash_Protect_Lamp "Description:This parameter provides the capability to flash the protect lamp. 
See J1939-73 for complete reference
Parsed from -014.";
CM_ SG_ 2566834808 Protect_Lamp_Status "Description:Used to relay trouble code information that is reporting a problem with a vehicle system that is most probably not electronic subsystem related. For instance, engine coolant temperature is exceeding its prescribed temperat";
CM_ SG_ 2566834808 DTC_1 "Description:This signal is a combination of 4 SPNs. To decode this signal, navigate to MCS tools.
Byte: 1 bits 8-1 SPN, 8 least significant bits of SPN (most significant at bit 8, SPN 1214)
Byte: 2 bits 8-1 SPN, second byte of SPN (most significa";
CM_ SG_ 2566834808 DTC_2 "Description:This signal is a combination of 4 SPNs. To decode this signal, navigate to MCS tools.
Byte: 1 bits 8-1 SPN, 8 least significant bits of SPN (most significant at bit 8, SPN 1214)
Byte: 2 bits 8-1 SPN, second byte of SPN (most significa";
CM_ SG_ 2566834808 DTC_3 "Description:This signal is a combination of 4 SPNs. To decode this signal, navigate to MCS tools.
Byte: 1 bits 8-1 SPN, 8 least significant bits of SPN (most significant at bit 8, SPN 1214)
Byte: 2 bits 8-1 SPN, second byte of SPN (most significa";
CM_ SG_ 2566834808 DTC_4 "Description:This signal is a combination of 4 SPNs. To decode this signal, navigate to MCS tools.
Byte: 1 bits 8-1 SPN, 8 least significant bits of SPN (most significant at bit 8, SPN 1214)
Byte: 2 bits 8-1 SPN, second byte of SPN (most significa";
CM_ SG_ 2566834808 DTC_5 "Description:This signal is a combination of 4 SPNs. To decode this signal, navigate to MCS tools.
Byte: 1 bits 8-1 SPN, 8 least significant bits of SPN (most significant at bit 8, SPN 1214)
Byte: 2 bits 8-1 SPN, second byte of SPN (most significa";
CM_ SG_ 2566834808 DTC_6 "Description:This signal is a combination of 4 SPNs. To decode this signal, navigate to MCS tools.
Byte: 1 bits 8-1 SPN, 8 least significant bits of SPN (most significant at bit 8, SPN 1214)
Byte: 2 bits 8-1 SPN, second byte of SPN (most significa";
CM_ SG_ 2566834808 DTC_7 "Description:This signal is a combination of 4 SPNs. To decode this signal, navigate to MCS tools.
Byte: 1 bits 8-1 SPN, 8 least significant bits of SPN (most significant at bit 8, SPN 1214)
Byte: 2 bits 8-1 SPN, second byte of SPN (most significa";
CM_ SG_ 2566834808 DTC_8 "Description:This signal is a combination of 4 SPNs. To decode this signal, navigate to MCS tools.
Byte: 1 bits 8-1 SPN, 8 least significant bits of SPN (most significant at bit 8, SPN 1214)
Byte: 2 bits 8-1 SPN, second byte of SPN (most significa";
CM_ SG_ 2566834808 DTC_9 "Description:This signal is a combination of 4 SPNs. To decode this signal, navigate to MCS tools.
Byte: 1 bits 8-1 SPN, 8 least significant bits of SPN (most significant at bit 8, SPN 1214)
Byte: 2 bits 8-1 SPN, second byte of SPN (most significa";
CM_ SG_ 2566834808 DTC_10 "Description:This signal is a combination of 4 SPNs. To decode this signal, navigate to MCS tools.
Byte: 1 bits 8-1 SPN, 8 least significant bits of SPN (most significant at bit 8, SPN 1214)
Byte: 2 bits 8-1 SPN, second byte of SPN (most signific";
CM_ BO_ 2566834812 "Name: Active Diagnostic Trouble Codes
Description:DM1 provides diagnostic lamp status and Diagnostic Trouble Codes (DTCs). Together, the lamp and DTC information
convey the diagnostic condition of the transmitting electronic component to other componen";
CM_ SG_ 2566834812 Flash_Malfunction_Indicator_Lamp "Description:This parameter provides the capability to flash the MIL. For OBD systems which are required to flash the SPN for specific malfunctions shall use the “slow flash” rate. 
See J1939-73 for complete reference
Pa";
CM_ SG_ 2566834812 Malfunction_Indicator_Lamp_Statu "Description:Used to relay only emissions-related trouble code information. This lamp is only illuminated when there is an emission-related trouble code active.
See J1939-71 for complete reference

Parsed from -014.";
CM_ SG_ 2566834812 Red_Stop_Lamp_Status "Description:Used to relay trouble code information that is of a severe enough condition that it warrants stopping the vehicle.
See J1939-71 for complete reference

Parsed from -014.";
CM_ SG_ 2566834812 Amber_Warning_Lamp_Status "Description:Used to relay trouble code information that is reporting a problem with the vehicle system but the vehicle need not be immediately stopped.
See J1939-71 for complete reference

Parsed from -014.";
CM_ SG_ 2566834812 Flash_Red_Stop_Lamp_RSL "Description:This parameter provides the capability to flash the RSL.
See J1939-73 for complete reference
Parsed from -014.";
CM_ SG_ 2566834812 Flash_Amber_Warning_Lamp_AWL "Description:This parameter provides the capability to flash the AWL. 
See J1939-73 for complete reference
Parsed from -014.";
CM_ SG_ 2566834812 Flash_Protect_Lamp "Description:This parameter provides the capability to flash the protect lamp. 
See J1939-73 for complete reference
Parsed from -014.";
CM_ SG_ 2566834812 Protect_Lamp_Status "Description:Used to relay trouble code information that is reporting a problem with a vehicle system that is most probably not electronic subsystem related. For instance, engine coolant temperature is exceeding its prescribed temperat";
CM_ SG_ 2566834812 DTC_1 "Description:This signal is a combination of 4 SPNs. To decode this signal, navigate to MCS tools.
Byte: 1 bits 8-1 SPN, 8 least significant bits of SPN (most significant at bit 8, SPN 1214)
Byte: 2 bits 8-1 SPN, second byte of SPN (most significa";
CM_ SG_ 2566834812 DTC_2 "Description:This signal is a combination of 4 SPNs. To decode this signal, navigate to MCS tools.
Byte: 1 bits 8-1 SPN, 8 least significant bits of SPN (most significant at bit 8, SPN 1214)
Byte: 2 bits 8-1 SPN, second byte of SPN (most significa";
CM_ SG_ 2566834812 DTC_3 "Description:This signal is a combination of 4 SPNs. To decode this signal, navigate to MCS tools.
Byte: 1 bits 8-1 SPN, 8 least significant bits of SPN (most significant at bit 8, SPN 1214)
Byte: 2 bits 8-1 SPN, second byte of SPN (most significa";
CM_ SG_ 2566834812 DTC_4 "Description:This signal is a combination of 4 SPNs. To decode this signal, navigate to MCS tools.
Byte: 1 bits 8-1 SPN, 8 least significant bits of SPN (most significant at bit 8, SPN 1214)
Byte: 2 bits 8-1 SPN, second byte of SPN (most significa";
CM_ SG_ 2566834812 DTC_5 "Description:This signal is a combination of 4 SPNs. To decode this signal, navigate to MCS tools.
Byte: 1 bits 8-1 SPN, 8 least significant bits of SPN (most significant at bit 8, SPN 1214)
Byte: 2 bits 8-1 SPN, second byte of SPN (most significa";
CM_ SG_ 2566834812 DTC_6 "Description:This signal is a combination of 4 SPNs. To decode this signal, navigate to MCS tools.
Byte: 1 bits 8-1 SPN, 8 least significant bits of SPN (most significant at bit 8, SPN 1214)
Byte: 2 bits 8-1 SPN, second byte of SPN (most significa";
CM_ SG_ 2566834812 DTC_7 "Description:This signal is a combination of 4 SPNs. To decode this signal, navigate to MCS tools.
Byte: 1 bits 8-1 SPN, 8 least significant bits of SPN (most significant at bit 8, SPN 1214)
Byte: 2 bits 8-1 SPN, second byte of SPN (most significa";
CM_ SG_ 2566834812 DTC_8 "Description:This signal is a combination of 4 SPNs. To decode this signal, navigate to MCS tools.
Byte: 1 bits 8-1 SPN, 8 least significant bits of SPN (most significant at bit 8, SPN 1214)
Byte: 2 bits 8-1 SPN, second byte of SPN (most significa";
CM_ SG_ 2566834812 DTC_9 "Description:This signal is a combination of 4 SPNs. To decode this signal, navigate to MCS tools.
Byte: 1 bits 8-1 SPN, 8 least significant bits of SPN (most significant at bit 8, SPN 1214)
Byte: 2 bits 8-1 SPN, second byte of SPN (most significa";
CM_ SG_ 2566834812 DTC_10 "Description:This signal is a combination of 4 SPNs. To decode this signal, navigate to MCS tools.
Byte: 1 bits 8-1 SPN, 8 least significant bits of SPN (most significant at bit 8, SPN 1214)
Byte: 2 bits 8-1 SPN, second byte of SPN (most signific";
CM_ BO_ 2566834814 "Name: Active Diagnostic Trouble Codes
Description:DM1 provides diagnostic lamp status and Diagnostic Trouble Codes (DTCs). Together, the lamp and DTC information
convey the diagnostic condition of the transmitting electronic component to other componen";
CM_ SG_ 2566834814 Flash_Malfunction_Indicator_Lamp "Description:This parameter provides the capability to flash the MIL. For OBD systems which are required to flash the SPN for specific malfunctions shall use the “slow flash” rate. 
See J1939-73 for complete reference
Pa";
CM_ SG_ 2566834814 Malfunction_Indicator_Lamp_Statu "Description:Used to relay only emissions-related trouble code information. This lamp is only illuminated when there is an emission-related trouble code active.
See J1939-71 for complete reference

Parsed from -014.";
CM_ SG_ 2566834814 Red_Stop_Lamp_Status "Description:Used to relay trouble code information that is of a severe enough condition that it warrants stopping the vehicle.
See J1939-71 for complete reference

Parsed from -014.";
CM_ SG_ 2566834814 Amber_Warning_Lamp_Status "Description:Used to relay trouble code information that is reporting a problem with the vehicle system but the vehicle need not be immediately stopped.
See J1939-71 for complete reference

Parsed from -014.";
CM_ SG_ 2566834814 Flash_Red_Stop_Lamp_RSL "Description:This parameter provides the capability to flash the RSL.
See J1939-73 for complete reference
Parsed from -014.";
CM_ SG_ 2566834814 Flash_Amber_Warning_Lamp_AWL "Description:This parameter provides the capability to flash the AWL. 
See J1939-73 for complete reference
Parsed from -014.";
CM_ SG_ 2566834814 Flash_Protect_Lamp "Description:This parameter provides the capability to flash the protect lamp. 
See J1939-73 for complete reference
Parsed from -014.";
CM_ SG_ 2566834814 Protect_Lamp_Status "Description:Used to relay trouble code information that is reporting a problem with a vehicle system that is most probably not electronic subsystem related. For instance, engine coolant temperature is exceeding its prescribed temperat";
CM_ SG_ 2566834814 DTC_1 "Description:This signal is a combination of 4 SPNs. To decode this signal, navigate to MCS tools.
Byte: 1 bits 8-1 SPN, 8 least significant bits of SPN (most significant at bit 8, SPN 1214)
Byte: 2 bits 8-1 SPN, second byte of SPN (most significa";
CM_ SG_ 2566834814 DTC_2 "Description:This signal is a combination of 4 SPNs. To decode this signal, navigate to MCS tools.
Byte: 1 bits 8-1 SPN, 8 least significant bits of SPN (most significant at bit 8, SPN 1214)
Byte: 2 bits 8-1 SPN, second byte of SPN (most significa";
CM_ SG_ 2566834814 DTC_3 "Description:This signal is a combination of 4 SPNs. To decode this signal, navigate to MCS tools.
Byte: 1 bits 8-1 SPN, 8 least significant bits of SPN (most significant at bit 8, SPN 1214)
Byte: 2 bits 8-1 SPN, second byte of SPN (most significa";
CM_ SG_ 2566834814 DTC_4 "Description:This signal is a combination of 4 SPNs. To decode this signal, navigate to MCS tools.
Byte: 1 bits 8-1 SPN, 8 least significant bits of SPN (most significant at bit 8, SPN 1214)
Byte: 2 bits 8-1 SPN, second byte of SPN (most significa";
CM_ SG_ 2566834814 DTC_5 "Description:This signal is a combination of 4 SPNs. To decode this signal, navigate to MCS tools.
Byte: 1 bits 8-1 SPN, 8 least significant bits of SPN (most significant at bit 8, SPN 1214)
Byte: 2 bits 8-1 SPN, second byte of SPN (most significa";
CM_ SG_ 2566834814 DTC_6 "Description:This signal is a combination of 4 SPNs. To decode this signal, navigate to MCS tools.
Byte: 1 bits 8-1 SPN, 8 least significant bits of SPN (most significant at bit 8, SPN 1214)
Byte: 2 bits 8-1 SPN, second byte of SPN (most significa";
CM_ SG_ 2566834814 DTC_7 "Description:This signal is a combination of 4 SPNs. To decode this signal, navigate to MCS tools.
Byte: 1 bits 8-1 SPN, 8 least significant bits of SPN (most significant at bit 8, SPN 1214)
Byte: 2 bits 8-1 SPN, second byte of SPN (most significa";
CM_ SG_ 2566834814 DTC_8 "Description:This signal is a combination of 4 SPNs. To decode this signal, navigate to MCS tools.
Byte: 1 bits 8-1 SPN, 8 least significant bits of SPN (most significant at bit 8, SPN 1214)
Byte: 2 bits 8-1 SPN, second byte of SPN (most significa";
CM_ SG_ 2566834814 DTC_9 "Description:This signal is a combination of 4 SPNs. To decode this signal, navigate to MCS tools.
Byte: 1 bits 8-1 SPN, 8 least significant bits of SPN (most significant at bit 8, SPN 1214)
Byte: 2 bits 8-1 SPN, second byte of SPN (most significa";
CM_ SG_ 2566834814 DTC_10 "Description:This signal is a combination of 4 SPNs. To decode this signal, navigate to MCS tools.
Byte: 1 bits 8-1 SPN, 8 least significant bits of SPN (most significant at bit 8, SPN 1214)
Byte: 2 bits 8-1 SPN, second byte of SPN (most signific";
CM_ BO_ 2566877311 "Name: pRadio Display 1
Description: Parsed from -014. ";
CM_ SG_ 2566877311 pRadio_Input_Device "Description: ";
CM_ SG_ 2566877311 pScreen_Area_Configuration "Description: ";
CM_ SG_ 2566877311 pRadio_Input_Value "Description: Could not parse SPN data type, please add:Type: Measured
Parsed from -014. ";
CM_ SG_ 2566877311 pStereo_Status "Description: ";
CM_ SG_ 2566877311 pText_Line_Configuration "Description: ";
CM_ SG_ 2566877311 pHighlight_Row "Description: ";
CM_ SG_ 2566877311 pScreen_Area_Mode "Description: ";
CM_ SG_ 2566877311 pFirst_Row_Configuration "Description: ";
CM_ SG_ 2566877311 pRadio_Scaling_Of_SPN_524100 "Description: ";
BA_DEF_ SG_  "SigType" ENUM  "Default","Range","RangeSigned","ASCII","Discrete","Control","ReferencePGN","DTC","StringDelimiter","StringLength","StringLengthControl";
BA_DEF_ SG_  "GenSigEVName" STRING ;
BA_DEF_ SG_  "GenSigILSupport" ENUM  "No","Yes";
BA_DEF_ SG_  "GenSigSendType" ENUM  "Cyclic","OnWrite","OnWriteWithRepetition","OnChange","OnChangeWithRepetition","IfActive","IfActiveWithRepetition","NoSigSendType";
BA_DEF_ BO_  "GenMsgCycleTimeFast" INT 0 3600000;
BA_DEF_ BO_  "GenMsgILSupport" ENUM  "No","Yes";
BA_DEF_ BO_  "GenMsgSendType" ENUM  "cyclic","spontaneous","cyclicIfActive","spontaneousWithDelay","cyclicAndSpontaneous","cyclicAndSpontaneousWithDelay","spontaneousWithRepetition","cyclicIfActiveAndSpontaneousWD","OnRequest";
BA_DEF_ BO_  "GenMsgRequestable" INT 0 1;
BA_DEF_ BO_  "GenMsgCycleTime" INT 0 3600000;
BA_DEF_ SG_  "SPN" INT 0 524287;
BA_DEF_ BO_  "VFrameFormat" ENUM  "StandardCAN","ExtendedCAN","reserved","J1939PG";
BA_DEF_DEF_  "SigType" "Default";
BA_DEF_DEF_  "GenSigEVName" "Env@Nodename_@Signame";
BA_DEF_DEF_  "GenSigILSupport" "Yes";
BA_DEF_DEF_  "GenSigSendType" "NoSigSendType";
BA_DEF_DEF_  "GenMsgCycleTimeFast" 0;
BA_DEF_DEF_  "GenMsgILSupport" "Yes";
BA_DEF_DEF_  "GenMsgSendType" "noMsgSendType";
BA_DEF_DEF_  "GenMsgRequestable" 1;
BA_DEF_DEF_  "GenMsgCycleTime" 0;
BA_DEF_DEF_  "SPN" 0;
BA_DEF_DEF_  "VFrameFormat" "J1939PG";
BA_ "SPN" SG_ 2565866791 Transmission_Actual_Gear_Ratio 526;
BA_ "SPN" SG_ 2565866791 Transmission_Requested_Range 162;
BA_ "SPN" SG_ 2565866791 Transmission_Current_Range 163;
BA_ "SPN" SG_ 2565866791 Transmission_Current_Gear 523;
BA_ "SPN" SG_ 2565866791 Transmission_Selected_Gear 524;
BA_ "SPN" SG_ 2566834727 Flash_Malfunction_Indicator_Lamp 3038;
BA_ "SPN" SG_ 2566834727 Malfunction_Indicator_Lamp_Statu 1213;
BA_ "SPN" SG_ 2566834727 Red_Stop_Lamp_Status 623;
BA_ "SPN" SG_ 2566834727 Amber_Warning_Lamp_Status 624;
BA_ "SPN" SG_ 2566834727 Flash_Red_Stop_Lamp_RSL 3039;
BA_ "SPN" SG_ 2566834727 Flash_Amber_Warning_Lamp_AWL 3040;
BA_ "SPN" SG_ 2566834727 Flash_Protect_Lamp 3041;
BA_ "SPN" SG_ 2566834727 Protect_Lamp_Status 987;
BA_ "SPN" SG_ 2566834727 DTC_1 999990;
BA_ "SPN" SG_ 2566834727 DTC_2 999991;
BA_ "SPN" SG_ 2566834727 DTC_3 999992;
BA_ "SPN" SG_ 2566834727 DTC_4 999993;
BA_ "SPN" SG_ 2566834727 DTC_5 999994;
BA_ "SPN" SG_ 2566834727 DTC_6 999995;
BA_ "SPN" SG_ 2566834727 DTC_7 999996;
BA_ "SPN" SG_ 2566834727 DTC_8 999997;
BA_ "SPN" SG_ 2566834727 DTC_9 999998;
BA_ "SPN" SG_ 2566834727 DTC_10 999999;
BA_ "SPN" SG_ 2566845479 Tire_Temperature 242;
BA_ "SPN" SG_ 2566845479 Tire_Pressure 241;
BA_ "SPN" SG_ 2566845479 Tire_Location 929;
BA_ "SPN" SG_ 2566844711 Cruise_Control_Set_Speed 86;
BA_ "SPN" SG_ 2566844711 Cruise_Control_Active 595;
BA_ "SPN" SG_ 2566844711 Clutch_Switch 598;
BA_ "SPN" SG_ 2566844711 Brake_Switch 597;
BA_ "SPN" SG_ 2566844711 pCC_Message_Counter 524080;
BA_ "SPN" SG_ 2566844711 Cruise_Control_Pause_Switch 1633;
BA_ "SPN" SG_ 2566844711 Cruise_Control_Set_Switch 599;
BA_ "SPN" SG_ 2566844711 Two_Speed_Axle_Switch 69;
BA_ "SPN" SG_ 2566844711 Cruise_Control_Enable_Switch 596;
BA_ "SPN" SG_ 2566844711 pOdometer_Drive_Bit 523994;
BA_ "SPN" SG_ 2566844711 pCC_Checksum 524079;
BA_ "SPN" SG_ 2566844711 WheelBased_Vehicle_Speed 84;
BA_ "SPN" SG_ 2566844711 Cruise_Control_Resume_Switch 601;
BA_ "SPN" SG_ 2566844711 Cruise_Control_Accelerate_Switch 602;
BA_ "SPN" SG_ 2566844711 pCruise_Enable_Status 524108;
BA_ "SPN" SG_ 2566844711 Parking_Brake_Switch 70;
BA_ "SPN" SG_ 2566844711 Cruise_Control_Coast_Decelerate_ 600;
BA_ "SPN" SG_ 2566860839 pAllowRemCommands 520663;
BA_ "SPN" SG_ 2566860839 pRVFBMessageCounter 520667;
BA_ "SPN" SG_ 2566860839 pReleaseCommand 520666;
BA_ "SPN" SG_ 2566860839 pDirectionalVehicleSpeed 520661;
BA_ "SPN" SG_ 2566860839 pEmergencyStop 520664;
BA_ "SPN" SG_ 2566860839 pRVFBMessageCRC 520668;
BA_ "SPN" SG_ 2365473063 Left_Turn_Signal_Lights_Command 2367;
BA_ "SPN" SG_ 2365473063 Alternate_Beam_Head_Light_Comman 2351;
BA_ "SPN" SG_ 2365473063 Right_Turn_Signal_Lights_Command 2369;
BA_ "SPN" SG_ 2365473063 Running_Light_Command 2403;
BA_ "SPN" SG_ 2349465383 Static_Roll_Angle 5582;
BA_ "SPN" SG_ 2631728935 Antitheft_Random_Number 1198;
BA_ "SPN" SG_ 2631728935 Antitheft_Encryption_Seed_Presen 1194;
BA_ "SPN" SG_ 2631728935 Antitheft_Password_Valid_Indicat 1195;
BA_ "SPN" SG_ 2631728935 Antitheft_Modify_Password_States 1197;
BA_ "SPN" SG_ 2631728935 Antitheft_Component_Status_State 1196;
BA_ "SPN" SG_ 2633883431 Front_Wheel_Drive_Actuator_Statu 2612;
BA_ "SPN" SG_ 2432656679 Key_Fob_Unlock_Button_Status 524044;
BA_ "SPN" SG_ 2432656679 Homelink_2 524037;
BA_ "SPN" SG_ 2432656679 Side_Stand_Switch 524098;
BA_ "SPN" SG_ 2432656679 Key_Fob_Lock_Button_Status 524043;
BA_ "SPN" SG_ 2432656679 Windshield__2_Down 524034;
BA_ "SPN" SG_ 2432656679 Turn__3_Cancel 524052;
BA_ "SPN" SG_ 2432656679 Reverse 524039;
BA_ "SPN" SG_ 2432656679 Hazard 524051;
BA_ "SPN" SG_ 2432656679 Homelink_1 524038;
BA_ "SPN" SG_ 2432656679 Windshield__1_Up 524035;
BA_ "SPN" SG_ 2432656679 Front_Brake_Switch 520322;
BA_ "SPN" SG_ 2432656679 Instrument_Cluster_Control__2 524058;
BA_ "SPN" SG_ 2432656679 Chassis_Unlock_Button_Status 524042;
BA_ "SPN" SG_ 2432656679 Power_Button 520362;
BA_ "SPN" SG_ 2432656679 RunStop_Switch 524040;
BA_ "SPN" SG_ 2432656679 Headlamp__2_High 524056;
BA_ "SPN" SG_ 2432656679 Instrument_Cluster_Control__1 524059;
BA_ "SPN" SG_ 2432656679 Clutch_Switch 524032;
BA_ "SPN" SG_ 2432656679 Start 524046;
BA_ "SPN" SG_ 2432656679 Headlamp__3_Driving 524055;
BA_ "SPN" SG_ 2432656679 Cruise__2_Set 524049;
BA_ "SPN" SG_ 2432656679 Windshield_Wiper 524041;
BA_ "SPN" SG_ 2432656679 Fog 524045;
BA_ "SPN" SG_ 2432656679 Cruise__3_Accel 524048;
BA_ "SPN" SG_ 2432656679 Horn 524047;
BA_ "SPN" SG_ 2432656679 Turn__2_Right 524053;
BA_ "SPN" SG_ 2432656679 Cruise__1_On 524050;
BA_ "SPN" SG_ 2432656679 Turn__1_Left 524054;
BA_ "SPN" SG_ 2432656679 Throttle_Safety_Switch__1 524036;
BA_ "SPN" SG_ 2432656679 Headlamp__1_Low 524057;
BA_ "SPN" SG_ 2432656679 Chassis_Lock_Switch_Status 516131;
BA_ "SPN" SG_ 2432656679 Fuel_Door_Unlock_Button_Status 516191;
BA_ "SPN" SG_ 2365523495 pModule_Control_Applied_State 516096;
BA_ "SPN" SG_ 2365523495 pModule_Control_Command_Destinat 524185;
BA_ "SPN" SG_ 2365523495 pModule_Control_Command_State 524248;
BA_ "SPN" SG_ 2365523495 pModule_Control_Message_Checksum 516097;
BA_ "SPN" SG_ 2566841895 Day 962;
BA_ "SPN" SG_ 2566841895 Month 963;
BA_ "SPN" SG_ 2566841895 Local_minute_offset 1601;
BA_ "SPN" SG_ 2566841895 Local_hour_offset 1602;
BA_ "SPN" SG_ 2566841895 Hours 961;
BA_ "SPN" SG_ 2566841895 Minutes 960;
BA_ "SPN" SG_ 2566841895 Seconds 959;
BA_ "SPN" SG_ 2566841895 Year 964;
BA_ "SPN" SG_ 2431708455 Engine_Starter_2_Feedback 7749;
BA_ "SPN" SG_ 2431708455 Engine_Start_Request 7745;
BA_ "SPN" SG_ 2431708455 Engine_Start_Abort_Request 7747;
BA_ "SPN" SG_ 2431708455 Engine_Start_Control_Checksum 7751;
BA_ "SPN" SG_ 2431708455 Transmission_Shift_Selector_Requ 7788;
BA_ "SPN" SG_ 2431708455 Engine_Start_Control_Message_Cou 7750;
BA_ "SPN" SG_ 2431708455 Engine_Start_Consent 7746;
BA_ "SPN" SG_ 2431708455 Engine_Starter_1_Feedback 7748;
BA_ "SPN" SG_ 2365531175 pEPSReqMod 516147;
BA_ "SPN" SG_ 2631794471 Antitheft_Desired_Exit_Mode_Stat 1200;
BA_ "SPN" SG_ 2631794471 Antitheft_Encryption_Indicator_S 1199;
BA_ "SPN" SG_ 2631794471 Antitheft_Command_States 1201;
BA_ "SPN" SG_ 2631794471 Antitheft_Password_Representatio 1202;
BA_ "SPN" SG_ 2566882855 pVCMState 523960;
BA_ "SPN" SG_ 2566882855 pFog_Light_Control_Mode 516369;
BA_ "SPN" SG_ 2566882855 pHeated_Grips_Control_Mode 516370;
BA_ "SPN" SG_ 2566882855 pLoadShedSts 516371;
BA_ "SPN" SG_ 2566877479 pTemperature_Units_Selected 524266;
BA_ "SPN" SG_ 2566877479 pTPMS_Learning_Status 524104;
BA_ "SPN" SG_ 2566877479 pPressure_Units_Selected 524269;
BA_ "SPN" SG_ 2566877479 pHigh_Res_Trip_2_Distance 524264;
BA_ "SPN" SG_ 2566877479 pVolume_Units_Selected 524267;
BA_ "SPN" SG_ 2566877479 pDisplay_Status 524105;
BA_ "SPN" SG_ 2566877479 pTime_Units_Selected 524268;
BA_ "SPN" SG_ 2566877479 pDistance_Units_Selected 524265;
BA_ "SPN" SG_ 2633984551 pHeated_Grip_Enable 520366;
BA_ "SPN" SG_ 2633984551 pUser_PIN_Access_Status 516128;
BA_ "SPN" SG_ 2633984551 pActive_Descent_Control_ADC_Stat 524013;
BA_ "SPN" SG_ 2633984551 pCruise_Control_Set_Status 524097;
BA_ "SPN" SG_ 2633984551 pTether_Switch_Status 520600;
BA_ "SPN" SG_ 2633984551 pHigh_Beam_Indicator_Status 524084;
BA_ "SPN" SG_ 2633984551 pLow_Fuel_Indicator_Status 524087;
BA_ "SPN" SG_ 2633984551 pHeated_Grips_Percentage 524096;
BA_ "SPN" SG_ 2633984551 pSide_Stand_Status 524270;
BA_ "SPN" SG_ 2633984551 pTurf_Mode_Requested 524136;
BA_ "SPN" SG_ 2633984551 pEngine_Idle_Shutdown_Timer 516223;
BA_ "SPN" SG_ 2633984551 Operator_Not_in_Operating_Statio 520247;
BA_ "SPN" SG_ 2633984551 pAWD_Mode_Requested 524138;
BA_ "SPN" SG_ 2633984551 pHeated_Grips_Up_Switch_Status 516129;
BA_ "SPN" SG_ 2633984551 pTreadle_Neutral_Status 524017;
BA_ "SPN" SG_ 2633984551 pHeated_Grips_Down_Switch_Status 516130;
BA_ "SPN" SG_ 2633984551 pPark_Brake_Indicator_Status 524271;
BA_ "SPN" SG_ 2633984551 pRWD_Mode_Requested 524137;
BA_ "SPN" SG_ 2633984551 pSeat_Belt_Indicator_Status 524092;
BA_ "SPN" SG_ 2633984551 pSecurity_Light_Immobilizer_Stat 524019;
BA_ "SPN" SG_ 2633984551 ECU_Security_Status 516202;
BA_ "SPN" SG_ 2633984551 pActive_Decent_Control_ADC_Mode_ 524139;
BA_ "SPN" SG_ 2633984551 pTreadle_Reverse_Status 524018;
BA_ "SPN" SG_ 2566876711 pHydraulic_Oil_Temp_Status 524074;
BA_ "SPN" SG_ 2566876711 pHydraulic_Oil_Pressure_Status 524075;
BA_ "SPN" SG_ 2566876711 pEngine_Oil_Pressure_Status 524076;
BA_ "SPN" SG_ 2566834735 Flash_Malfunction_Indicator_Lamp 3038;
BA_ "SPN" SG_ 2566834735 Malfunction_Indicator_Lamp_Statu 1213;
BA_ "SPN" SG_ 2566834735 Red_Stop_Lamp_Status 623;
BA_ "SPN" SG_ 2566834735 Amber_Warning_Lamp_Status 624;
BA_ "SPN" SG_ 2566834735 Flash_Red_Stop_Lamp_RSL 3039;
BA_ "SPN" SG_ 2566834735 Flash_Amber_Warning_Lamp_AWL 3040;
BA_ "SPN" SG_ 2566834735 Flash_Protect_Lamp 3041;
BA_ "SPN" SG_ 2566834735 Protect_Lamp_Status 987;
BA_ "SPN" SG_ 2566834735 DTC_1 999990;
BA_ "SPN" SG_ 2566834735 DTC_2 999991;
BA_ "SPN" SG_ 2566834735 DTC_3 999992;
BA_ "SPN" SG_ 2566834735 DTC_4 999993;
BA_ "SPN" SG_ 2566834735 DTC_5 999994;
BA_ "SPN" SG_ 2566834735 DTC_6 999995;
BA_ "SPN" SG_ 2566834735 DTC_7 999996;
BA_ "SPN" SG_ 2566834735 DTC_8 999997;
BA_ "SPN" SG_ 2566834735 DTC_9 999998;
BA_ "SPN" SG_ 2566834735 DTC_10 999999;
BA_ "SPN" SG_ 2566883119 pRideHeightStatus 523972;
BA_ "SPN" SG_ 2566883119 pRideHeightSystemReadiness 523974;
BA_ "SPN" SG_ 2566883119 pRollTiresRequest 523971;
BA_ "SPN" SG_ 2566883119 pRideHeightPosition 523970;
BA_ "SPN" SG_ 2566883119 pRideHeightPumpStatus 523795;
BA_ "SPN" SG_ 2566883119 RH_Expected_Pump_Load 523980;
BA_ "SPN" SG_ 2566883119 pRideHeightPumpCommandRequestSta 523977;
BA_ "SPN" SG_ 2566834742 Flash_Malfunction_Indicator_Lamp 3038;
BA_ "SPN" SG_ 2566834742 Malfunction_Indicator_Lamp_Statu 1213;
BA_ "SPN" SG_ 2566834742 Red_Stop_Lamp_Status 623;
BA_ "SPN" SG_ 2566834742 Amber_Warning_Lamp_Status 624;
BA_ "SPN" SG_ 2566834742 Flash_Red_Stop_Lamp_RSL 3039;
BA_ "SPN" SG_ 2566834742 Flash_Amber_Warning_Lamp_AWL 3040;
BA_ "SPN" SG_ 2566834742 Flash_Protect_Lamp 3041;
BA_ "SPN" SG_ 2566834742 Protect_Lamp_Status 987;
BA_ "SPN" SG_ 2566834742 DTC_1 999990;
BA_ "SPN" SG_ 2566834742 DTC_2 999991;
BA_ "SPN" SG_ 2566834742 DTC_3 999992;
BA_ "SPN" SG_ 2566834742 DTC_4 999993;
BA_ "SPN" SG_ 2566834742 DTC_5 999994;
BA_ "SPN" SG_ 2566834742 DTC_6 999995;
BA_ "SPN" SG_ 2566834742 DTC_7 999996;
BA_ "SPN" SG_ 2566834742 DTC_8 999997;
BA_ "SPN" SG_ 2566834742 DTC_9 999998;
BA_ "SPN" SG_ 2566834742 DTC_10 999999;
BA_ "SPN" SG_ 2566877750 pRight_Hand_Grip_Temperature 524110;
BA_ "SPN" SG_ 2566877750 pDriver_Seat_Temperature 516453;
BA_ "SPN" SG_ 2566877750 pPassenger_Seat_Temperature 516454;
BA_ "SPN" SG_ 2566877750 pLeft_Hand_Grip_Temperature 524109;
BA_ "SPN" SG_ 2566882102 pDriver_HeatedCooled_Seat_Enable 516447;
BA_ "SPN" SG_ 2566882102 pDriver_HeatedCooled_Seat_Down_B 516449;
BA_ "SPN" SG_ 2566882102 pPassenger_HeatedCooled_Seat_Ena 516450;
BA_ "SPN" SG_ 2566882102 pPassenger_HeatedCooled_Seat_Up_ 516451;
BA_ "SPN" SG_ 2566882102 pPassenger_HeatedCooled_Seat_Per 516446;
BA_ "SPN" SG_ 2566882102 pPassenger_HeatedCooled_Seat_Dow 516452;
BA_ "SPN" SG_ 2566882102 pDriver_HeatedCooled_Seat_Percen 516445;
BA_ "SPN" SG_ 2566882102 pDriver_HeatedCooled_Seat_Up_But 516448;
BA_ "SPN" SG_ 2432658497 pFOCC_Checksum 524081;
BA_ "SPN" SG_ 2432658497 Drive_Mode__4 524063;
BA_ "SPN" SG_ 2432658497 Drive_Mode__2 524061;
BA_ "SPN" SG_ 2432658497 pFOCC_Message_Counter 524082;
BA_ "SPN" SG_ 2432658497 Drivers_Net_Engagement 524066;
BA_ "SPN" SG_ 2432658497 Foot_On_Cruise_Control_Switch 524072;
BA_ "SPN" SG_ 2432658497 Drive_Mode__1 524060;
BA_ "SPN" SG_ 2432658497 Momentary_Driveline_Left_Press 520467;
BA_ "SPN" SG_ 2432658497 CylDeAc_Enable 521197;
BA_ "SPN" SG_ 2432658497 Work_Group_Lock_Switch 524069;
BA_ "SPN" SG_ 2432658497 Drivers_Seatbelt_Engagement 524065;
BA_ "SPN" SG_ 2432658497 Drive_Mode__3 524062;
BA_ "SPN" SG_ 2432658497 Work_Mode_Switch 524071;
BA_ "SPN" SG_ 2432658497 Momentary_Driveline_Right_Press 520468;
BA_ "SPN" SG_ 2432658497 PTO_Mode_Switch_RPM_Control 524064;
BA_ "SPN" SG_ 2432658497 Operator_Presence_Switch 524070;
BA_ "SPN" SG_ 2432658497 Tilt_Lock_Switch 524068;
BA_ "SPN" SG_ 2432658497 Engine_Brake_Enable 521198;
BA_ "SPN" SG_ 2432658497 Accessory_Relay 520469;
BA_ "SPN" SG_ 2566887489 pRider_Weight_Mid_Left 516101;
BA_ "SPN" SG_ 2566887489 pRider_Weight_Front_Left 516099;
BA_ "SPN" SG_ 2566887489 pBox_Load_Weight 516105;
BA_ "SPN" SG_ 2566887489 pRider_Weight_Rear_Right 516104;
BA_ "SPN" SG_ 2566887489 pRider_Weight_Front_Right 516100;
BA_ "SPN" SG_ 2566887489 pRider_Weight_Mid_Right 516102;
BA_ "SPN" SG_ 2566887489 pRider_Weight_Rear_Left 516103;
BA_ "SPN" SG_ 2566834753 Flash_Malfunction_Indicator_Lamp 3038;
BA_ "SPN" SG_ 2566834753 Malfunction_Indicator_Lamp_Statu 1213;
BA_ "SPN" SG_ 2566834753 Red_Stop_Lamp_Status 623;
BA_ "SPN" SG_ 2566834753 Amber_Warning_Lamp_Status 624;
BA_ "SPN" SG_ 2566834753 Flash_Red_Stop_Lamp_RSL 3039;
BA_ "SPN" SG_ 2566834753 Flash_Amber_Warning_Lamp_AWL 3040;
BA_ "SPN" SG_ 2566834753 Flash_Protect_Lamp 3041;
BA_ "SPN" SG_ 2566834753 Protect_Lamp_Status 987;
BA_ "SPN" SG_ 2566834753 DTC_1 999990;
BA_ "SPN" SG_ 2566834753 DTC_2 999991;
BA_ "SPN" SG_ 2566834753 DTC_3 999992;
BA_ "SPN" SG_ 2566834753 DTC_4 999993;
BA_ "SPN" SG_ 2566834753 DTC_5 999994;
BA_ "SPN" SG_ 2566834753 DTC_6 999995;
BA_ "SPN" SG_ 2566834753 DTC_7 999996;
BA_ "SPN" SG_ 2566834753 DTC_8 999997;
BA_ "SPN" SG_ 2566834753 DTC_9 999998;
BA_ "SPN" SG_ 2566834753 DTC_10 999999;
BA_ "SPN" SG_ 2432656449 Source 524027;
BA_ "SPN" SG_ 2432656449 Squelch_SQ_Up 524022;
BA_ "SPN" SG_ 2432656449 MutePreset 524026;
BA_ "SPN" SG_ 2432656449 Volume_Down 524031;
BA_ "SPN" SG_ 2432656449 Volume_Up 524030;
BA_ "SPN" SG_ 2432656449 Tune_Up 524028;
BA_ "SPN" SG_ 2432656449 Seek_Up 516341;
BA_ "SPN" SG_ 2432656449 Tune_Down 524029;
BA_ "SPN" SG_ 2432656449 Squelch_SQ_Down 524023;
BA_ "SPN" SG_ 2432656449 pInfotainment_Joystick_1 520363;
BA_ "SPN" SG_ 2432656449 Preset 524020;
BA_ "SPN" SG_ 2432656449 Seek_Down 516342;
BA_ "SPN" SG_ 2432656449 pInfotainment_Joystick_2 520364;
BA_ "SPN" SG_ 2432656449 ICOM 524025;
BA_ "SPN" SG_ 2432656449 Push_To_Talk_PTT 524021;
BA_ "SPN" SG_ 2432656449 pMultifunction_Infotainment_Inte 520380;
BA_ "SPN" SG_ 2432656449 COM 524024;
BA_ "SPN" SG_ 2432656449 PlayPause 516340;
BA_ "SPN" SG_ 2566832449 Total_Vehicle_Distance_High_Reso 917;
BA_ "SPN" SG_ 2566832449 Trip_Distance_High_Resolution 918;
BA_ "SPN" SG_ 2432656705 Key_Fob_Unlock_Button_Status 524044;
BA_ "SPN" SG_ 2432656705 Homelink_2 524037;
BA_ "SPN" SG_ 2432656705 Side_Stand_Switch 524098;
BA_ "SPN" SG_ 2432656705 Key_Fob_Lock_Button_Status 524043;
BA_ "SPN" SG_ 2432656705 Windshield__2_Down 524034;
BA_ "SPN" SG_ 2432656705 Turn__3_Cancel 524052;
BA_ "SPN" SG_ 2432656705 Reverse 524039;
BA_ "SPN" SG_ 2432656705 Hazard 524051;
BA_ "SPN" SG_ 2432656705 Homelink_1 524038;
BA_ "SPN" SG_ 2432656705 Windshield__1_Up 524035;
BA_ "SPN" SG_ 2432656705 Front_Brake_Switch 520322;
BA_ "SPN" SG_ 2432656705 Instrument_Cluster_Control__2 524058;
BA_ "SPN" SG_ 2432656705 Chassis_Unlock_Button_Status 524042;
BA_ "SPN" SG_ 2432656705 Power_Button 520362;
BA_ "SPN" SG_ 2432656705 RunStop_Switch 524040;
BA_ "SPN" SG_ 2432656705 Headlamp__2_High 524056;
BA_ "SPN" SG_ 2432656705 Instrument_Cluster_Control__1 524059;
BA_ "SPN" SG_ 2432656705 Clutch_Switch 524032;
BA_ "SPN" SG_ 2432656705 Start 524046;
BA_ "SPN" SG_ 2432656705 Headlamp__3_Driving 524055;
BA_ "SPN" SG_ 2432656705 Cruise__2_Set 524049;
BA_ "SPN" SG_ 2432656705 Windshield_Wiper 524041;
BA_ "SPN" SG_ 2432656705 Fog 524045;
BA_ "SPN" SG_ 2432656705 Cruise__3_Accel 524048;
BA_ "SPN" SG_ 2432656705 Horn 524047;
BA_ "SPN" SG_ 2432656705 Turn__2_Right 524053;
BA_ "SPN" SG_ 2432656705 Cruise__1_On 524050;
BA_ "SPN" SG_ 2432656705 Turn__1_Left 524054;
BA_ "SPN" SG_ 2432656705 Throttle_Safety_Switch__1 524036;
BA_ "SPN" SG_ 2432656705 Headlamp__1_Low 524057;
BA_ "SPN" SG_ 2432656705 Chassis_Lock_Switch_Status 516131;
BA_ "SPN" SG_ 2432656705 Fuel_Door_Unlock_Button_Status 516191;
BA_ "SPN" SG_ 2566877505 pTemperature_Units_Selected 524266;
BA_ "SPN" SG_ 2566877505 pTPMS_Learning_Status 524104;
BA_ "SPN" SG_ 2566877505 pPressure_Units_Selected 524269;
BA_ "SPN" SG_ 2566877505 pHigh_Res_Trip_2_Distance 524264;
BA_ "SPN" SG_ 2566877505 pVolume_Units_Selected 524267;
BA_ "SPN" SG_ 2566877505 pDisplay_Status 524105;
BA_ "SPN" SG_ 2566877505 pTime_Units_Selected 524268;
BA_ "SPN" SG_ 2566877505 pDistance_Units_Selected 524265;
BA_ "SPN" SG_ 2566882113 pDriver_HeatedCooled_Seat_Enable 516447;
BA_ "SPN" SG_ 2566882113 pDriver_HeatedCooled_Seat_Down_B 516449;
BA_ "SPN" SG_ 2566882113 pPassenger_HeatedCooled_Seat_Ena 516450;
BA_ "SPN" SG_ 2566882113 pPassenger_HeatedCooled_Seat_Up_ 516451;
BA_ "SPN" SG_ 2566882113 pPassenger_HeatedCooled_Seat_Per 516446;
BA_ "SPN" SG_ 2566882113 pPassenger_HeatedCooled_Seat_Dow 516452;
BA_ "SPN" SG_ 2566882113 pDriver_HeatedCooled_Seat_Percen 516445;
BA_ "SPN" SG_ 2566882113 pDriver_HeatedCooled_Seat_Up_But 516448;
BA_ "SPN" SG_ 2631794497 Antitheft_Desired_Exit_Mode_Stat 1200;
BA_ "SPN" SG_ 2631794497 Antitheft_Encryption_Indicator_S 1199;
BA_ "SPN" SG_ 2631794497 Antitheft_Command_States 1201;
BA_ "SPN" SG_ 2631794497 Antitheft_Password_Representatio 1202;
BA_ "SPN" SG_ 2365530202 pMessage_Counter 520564;
BA_ "SPN" SG_ 2365530202 pRequested_Engine_TorqueTorque_L 520562;
BA_ "SPN" SG_ 2365530202 pEngine_Control_Mode 520560;
BA_ "SPN" SG_ 2365530202 pRequested_Engine_SpeedSpeed_Lim 520563;
BA_ "SPN" SG_ 2365530202 WheelBased_Vehicle_Speed 84;
BA_ "SPN" SG_ 2365530202 pEngine_Control_Requestor 520561;
BA_ "SPN" SG_ 2365530202 pMessage_Checksum 520565;
BA_ "SPN" SG_ 2565866842 Transmission_Actual_Gear_Ratio 526;
BA_ "SPN" SG_ 2565866842 Transmission_Requested_Range 162;
BA_ "SPN" SG_ 2565866842 Transmission_Current_Range 163;
BA_ "SPN" SG_ 2565866842 Transmission_Current_Gear 523;
BA_ "SPN" SG_ 2565866842 Transmission_Selected_Gear 524;
BA_ "SPN" SG_ 2231304282 pEPCU2_Message_Counter 524155;
BA_ "SPN" SG_ 2231304282 pEPCU2_Counter_Limit_Torque 524157;
BA_ "SPN" SG_ 2231304282 pElectric_Propulsion_Control_Uni 524159;
BA_ "SPN" SG_ 2231304282 pEPCU_2_Check_Sequence 524242;
BA_ "SPN" SG_ 2231304282 pEPCU2_Torque_Demand 524156;
BA_ "SPN" SG_ 2231304282 pEPCU2_Speed_Limit 524158;
BA_ "SPN" SG_ 2566802010 Transmission_Ready_for_Brake_Rel 3086;
BA_ "SPN" SG_ 2566802010 Transmission_Shift_Inhibit_Indic 1851;
BA_ "SPN" SG_ 2566802010 Transmission_Mode_3_Indicator 2538;
BA_ "SPN" SG_ 2566802010 Transmission_Requested_Range_Dis 1850;
BA_ "SPN" SG_ 2566802010 Transmission_Mode_2_Indicator 2537;
BA_ "SPN" SG_ 2566802010 Transmission_Requested_Range_Dis 1849;
BA_ "SPN" SG_ 2566802010 pTransmission_Mode_5_Indicator 523997;
BA_ "SPN" SG_ 2566802010 Transmission_Requested_Gear_Feed 3289;
BA_ "SPN" SG_ 2566802010 pMessageChecksum 516182;
BA_ "SPN" SG_ 2566802010 Transmission_Mode_1_Indicator 2536;
BA_ "SPN" SG_ 2566802010 Active_Shift_Console_Indicator 2945;
BA_ "SPN" SG_ 2566802010 pMessageCounter 516181;
BA_ "SPN" SG_ 2566802010 Transmission_Mode_4_Indicator 2539;
BA_ "SPN" SG_ 2566802010 Transmission_Engine_Crank_Enable 2900;
BA_ "SPN" SG_ 2231309146 pEPCU1_Message_Counter 524152;
BA_ "SPN" SG_ 2231309146 pElectric_Propulsion_Control_Uni 524154;
BA_ "SPN" SG_ 2231309146 pEPCU1_Torque_Demand 524150;
BA_ "SPN" SG_ 2231309146 pEPCU1_Counter_Limit_Torque 524151;
BA_ "SPN" SG_ 2231309146 pEPCU1_Speed_Limit 524153;
BA_ "SPN" SG_ 2231309146 pTorque_Message_Checksum 524241;
BA_ "SPN" SG_ 2566844762 Cruise_Control_Set_Speed 86;
BA_ "SPN" SG_ 2566844762 Cruise_Control_Active 595;
BA_ "SPN" SG_ 2566844762 Clutch_Switch 598;
BA_ "SPN" SG_ 2566844762 Brake_Switch 597;
BA_ "SPN" SG_ 2566844762 pCC_Message_Counter 524080;
BA_ "SPN" SG_ 2566844762 Cruise_Control_Pause_Switch 1633;
BA_ "SPN" SG_ 2566844762 Cruise_Control_Set_Switch 599;
BA_ "SPN" SG_ 2566844762 Two_Speed_Axle_Switch 69;
BA_ "SPN" SG_ 2566844762 Cruise_Control_Enable_Switch 596;
BA_ "SPN" SG_ 2566844762 pOdometer_Drive_Bit 523994;
BA_ "SPN" SG_ 2566844762 pCC_Checksum 524079;
BA_ "SPN" SG_ 2566844762 WheelBased_Vehicle_Speed 84;
BA_ "SPN" SG_ 2566844762 Cruise_Control_Resume_Switch 601;
BA_ "SPN" SG_ 2566844762 Cruise_Control_Accelerate_Switch 602;
BA_ "SPN" SG_ 2566844762 pCruise_Enable_Status 524108;
BA_ "SPN" SG_ 2566844762 Parking_Brake_Switch 70;
BA_ "SPN" SG_ 2566844762 Cruise_Control_Coast_Decelerate_ 600;
BA_ "SPN" SG_ 2365428314 Fuel_Pump_Primer_Control 4082;
BA_ "SPN" SG_ 2365428314 Engine_Operating_State 3543;
BA_ "SPN" SG_ 2365428314 Engine_Fuel_Shutoff_1_Control 632;
BA_ "SPN" SG_ 2431708506 Engine_Starter_2_Feedback 7749;
BA_ "SPN" SG_ 2431708506 Engine_Start_Request 7745;
BA_ "SPN" SG_ 2431708506 Engine_Start_Abort_Request 7747;
BA_ "SPN" SG_ 2431708506 Engine_Start_Control_Checksum 7751;
BA_ "SPN" SG_ 2431708506 Transmission_Shift_Selector_Requ 7788;
BA_ "SPN" SG_ 2431708506 Engine_Start_Control_Message_Cou 7750;
BA_ "SPN" SG_ 2431708506 Engine_Start_Consent 7746;
BA_ "SPN" SG_ 2431708506 Engine_Starter_1_Feedback 7748;
BA_ "SPN" SG_ 2566853722 pEfficiency_LEV 520528;
BA_ "SPN" SG_ 2566853722 pInstantaneous_Efficiency_LEV 524231;
BA_ "SPN" SG_ 2566853722 pRange_to_Empty_LEV 520529;
BA_ "SPN" SG_ 2231341402 Driveline_Mode 520651;
BA_ "SPN" SG_ 2231341402 Powertrain_Mode 520652;
BA_ "SPN" SG_ 2231341402 Transmission_Current_Range 520484;
BA_ "SPN" SG_ 2231341402 Fuel_Level 520536;
BA_ "SPN" SG_ 2231341402 State_of_Charge 520653;
BA_ "SPN" SG_ 2566834808 Flash_Malfunction_Indicator_Lamp 3038;
BA_ "SPN" SG_ 2566834808 Malfunction_Indicator_Lamp_Statu 1213;
BA_ "SPN" SG_ 2566834808 Red_Stop_Lamp_Status 623;
BA_ "SPN" SG_ 2566834808 Amber_Warning_Lamp_Status 624;
BA_ "SPN" SG_ 2566834808 Flash_Red_Stop_Lamp_RSL 3039;
BA_ "SPN" SG_ 2566834808 Flash_Amber_Warning_Lamp_AWL 3040;
BA_ "SPN" SG_ 2566834808 Flash_Protect_Lamp 3041;
BA_ "SPN" SG_ 2566834808 Protect_Lamp_Status 987;
BA_ "SPN" SG_ 2566834808 DTC_1 999990;
BA_ "SPN" SG_ 2566834808 DTC_2 999991;
BA_ "SPN" SG_ 2566834808 DTC_3 999992;
BA_ "SPN" SG_ 2566834808 DTC_4 999993;
BA_ "SPN" SG_ 2566834808 DTC_5 999994;
BA_ "SPN" SG_ 2566834808 DTC_6 999995;
BA_ "SPN" SG_ 2566834808 DTC_7 999996;
BA_ "SPN" SG_ 2566834808 DTC_8 999997;
BA_ "SPN" SG_ 2566834808 DTC_9 999998;
BA_ "SPN" SG_ 2566834808 DTC_10 999999;
BA_ "SPN" SG_ 2566834812 Flash_Malfunction_Indicator_Lamp 3038;
BA_ "SPN" SG_ 2566834812 Malfunction_Indicator_Lamp_Statu 1213;
BA_ "SPN" SG_ 2566834812 Red_Stop_Lamp_Status 623;
BA_ "SPN" SG_ 2566834812 Amber_Warning_Lamp_Status 624;
BA_ "SPN" SG_ 2566834812 Flash_Red_Stop_Lamp_RSL 3039;
BA_ "SPN" SG_ 2566834812 Flash_Amber_Warning_Lamp_AWL 3040;
BA_ "SPN" SG_ 2566834812 Flash_Protect_Lamp 3041;
BA_ "SPN" SG_ 2566834812 Protect_Lamp_Status 987;
BA_ "SPN" SG_ 2566834812 DTC_1 999990;
BA_ "SPN" SG_ 2566834812 DTC_2 999991;
BA_ "SPN" SG_ 2566834812 DTC_3 999992;
BA_ "SPN" SG_ 2566834812 DTC_4 999993;
BA_ "SPN" SG_ 2566834812 DTC_5 999994;
BA_ "SPN" SG_ 2566834812 DTC_6 999995;
BA_ "SPN" SG_ 2566834812 DTC_7 999996;
BA_ "SPN" SG_ 2566834812 DTC_8 999997;
BA_ "SPN" SG_ 2566834812 DTC_9 999998;
BA_ "SPN" SG_ 2566834812 DTC_10 999999;
BA_ "SPN" SG_ 2566834814 Flash_Malfunction_Indicator_Lamp 3038;
BA_ "SPN" SG_ 2566834814 Malfunction_Indicator_Lamp_Statu 1213;
BA_ "SPN" SG_ 2566834814 Red_Stop_Lamp_Status 623;
BA_ "SPN" SG_ 2566834814 Amber_Warning_Lamp_Status 624;
BA_ "SPN" SG_ 2566834814 Flash_Red_Stop_Lamp_RSL 3039;
BA_ "SPN" SG_ 2566834814 Flash_Amber_Warning_Lamp_AWL 3040;
BA_ "SPN" SG_ 2566834814 Flash_Protect_Lamp 3041;
BA_ "SPN" SG_ 2566834814 Protect_Lamp_Status 987;
BA_ "SPN" SG_ 2566834814 DTC_1 999990;
BA_ "SPN" SG_ 2566834814 DTC_2 999991;
BA_ "SPN" SG_ 2566834814 DTC_3 999992;
BA_ "SPN" SG_ 2566834814 DTC_4 999993;
BA_ "SPN" SG_ 2566834814 DTC_5 999994;
BA_ "SPN" SG_ 2566834814 DTC_6 999995;
BA_ "SPN" SG_ 2566834814 DTC_7 999996;
BA_ "SPN" SG_ 2566834814 DTC_8 999997;
BA_ "SPN" SG_ 2566834814 DTC_9 999998;
BA_ "SPN" SG_ 2566834814 DTC_10 999999;
BA_ "SPN" SG_ 2566877311 pRadio_Input_Device 524099;
BA_ "SPN" SG_ 2566877311 pScreen_Area_Configuration 524107;
BA_ "SPN" SG_ 2566877311 pRadio_Input_Value 524100;
BA_ "SPN" SG_ 2566877311 pStereo_Status 524103;
BA_ "SPN" SG_ 2566877311 pText_Line_Configuration 524102;
BA_ "SPN" SG_ 2566877311 pHighlight_Row 524119;
BA_ "SPN" SG_ 2566877311 pScreen_Area_Mode 524132;
BA_ "SPN" SG_ 2566877311 pFirst_Row_Configuration 524106;
BA_ "SPN" SG_ 2566877311 pRadio_Scaling_Of_SPN_524100 524101;
BA_ "GenMsgCycleTime" BO_ 2565866791 100;
BA_ "GenMsgCycleTime" BO_ 2566834727 1000;
BA_ "GenMsgCycleTime" BO_ 2566845479 10000;
BA_ "GenMsgCycleTime" BO_ 2566844711 100;
BA_ "GenMsgCycleTime" BO_ 2566860839 10;
BA_ "GenMsgCycleTime" BO_ 2365473063 1000;
BA_ "GenMsgCycleTimeFast" BO_ 2365473063 100;
BA_ "GenMsgCycleTime" BO_ 2349465383 100;
BA_ "GenMsgCycleTime" BO_ 2633883431 500;
BA_ "GenMsgCycleTime" BO_ 2432656679 200;
BA_ "GenMsgCycleTimeFast" BO_ 2432656679 100;
BA_ "GenMsgCycleTime" BO_ 2365523495 5000;
BA_ "GenMsgCycleTimeFast" BO_ 2365523495 50;
BA_ "GenMsgCycleTimeFast" BO_ 2566841895 60000;
BA_ "GenMsgCycleTime" BO_ 2431708455 250;
BA_ "GenMsgCycleTimeFast" BO_ 2431708455 20;
BA_ "GenMsgCycleTime" BO_ 2365531175 500;
BA_ "GenMsgCycleTimeFast" BO_ 2365531175 10;
BA_ "GenMsgCycleTime" BO_ 2566882855 100;
BA_ "GenMsgCycleTime" BO_ 2566877479 1000;
BA_ "GenMsgCycleTime" BO_ 2633984551 500;
BA_ "GenMsgCycleTimeFast" BO_ 2633984551 100;
BA_ "GenMsgCycleTime" BO_ 2566876711 1000;
BA_ "GenMsgCycleTime" BO_ 2566834735 1000;
BA_ "GenMsgCycleTime" BO_ 2566883119 1000;
BA_ "GenMsgCycleTimeFast" BO_ 2566883119 20;
BA_ "GenMsgCycleTime" BO_ 2566834742 1000;
BA_ "GenMsgCycleTime" BO_ 2566877750 1000;
BA_ "GenMsgCycleTime" BO_ 2566882102 1000;
BA_ "GenMsgCycleTimeFast" BO_ 2566882102 100;
BA_ "GenMsgCycleTime" BO_ 2432658497 200;
BA_ "GenMsgCycleTimeFast" BO_ 2432658497 100;
BA_ "GenMsgCycleTime" BO_ 2566887489 5000;
BA_ "GenMsgCycleTimeFast" BO_ 2566887489 1000;
BA_ "GenMsgCycleTime" BO_ 2566834753 1000;
BA_ "GenMsgCycleTime" BO_ 2432656449 500;
BA_ "GenMsgCycleTimeFast" BO_ 2432656449 200;
BA_ "GenMsgCycleTime" BO_ 2566832449 1000;
BA_ "GenMsgCycleTime" BO_ 2432656705 200;
BA_ "GenMsgCycleTimeFast" BO_ 2432656705 100;
BA_ "GenMsgCycleTime" BO_ 2566877505 1000;
BA_ "GenMsgCycleTime" BO_ 2566882113 1000;
BA_ "GenMsgCycleTimeFast" BO_ 2566882113 100;
BA_ "GenMsgCycleTime" BO_ 2365530202 10;
BA_ "GenMsgCycleTime" BO_ 2565866842 100;
BA_ "GenMsgCycleTime" BO_ 2231304282 10;
BA_ "GenMsgCycleTime" BO_ 2566802010 100;
BA_ "GenMsgCycleTime" BO_ 2231309146 10;
BA_ "GenMsgCycleTime" BO_ 2566844762 100;
BA_ "GenMsgCycleTime" BO_ 2431708506 250;
BA_ "GenMsgCycleTimeFast" BO_ 2431708506 20;
BA_ "GenMsgCycleTime" BO_ 2566853722 100;
BA_ "GenMsgCycleTime" BO_ 2231341402 100;
BA_ "GenMsgCycleTime" BO_ 2566834808 1000;
BA_ "GenMsgCycleTime" BO_ 2566834812 1000;
BA_ "GenMsgCycleTime" BO_ 2566834814 1000;
BA_ "GenMsgCycleTime" BO_ 2566877311 1000;
VAL_ 2566844711 pOdometer_Drive_Bit 3 "Not Available " 2 "Error" 0 "State A" 1 "State B" ;
VAL_ 2566844711 pCruise_Enable_Status 14 "Error" 15 "Not Available " 0 "Not enabled. System must be enabled before it is set" 1 "Enable. System is ready to be set by operator. Only change state when system is enabled/disabled with on/off switch" ;
VAL_ 2566860839 pAllowRemCommands 2 "Error" 0 "Off" 1 "On" 3 "Not-Available" ;
VAL_ 2566860839 pReleaseCommand 2 "Error" 0 "Off" 1 "On" 3 "Not-Available" ;
VAL_ 2566860839 pEmergencyStop 2 "Error" 0 "Off" 1 "On" 3 "Not-Available" ;
VAL_ 2631728935 Antitheft_Password_Valid_Indicat 3 "Not available" 2 "Error" 1 "Password is a validated password" 0 "Password is not a validated password" ;
VAL_ 2432656679 Key_Fob_Unlock_Button_Status 2 "Error" 0 "Off" 1 "On" 3 "Not-Available" ;
VAL_ 2432656679 Homelink_2 2 "Error" 0 "Off" 1 "On" 3 "Not-Available" ;
VAL_ 2432656679 Side_Stand_Switch 2 "Error" 0 "Off" 1 "On" 3 "Not-Available" ;
VAL_ 2432656679 Key_Fob_Lock_Button_Status 2 "Error" 0 "Off" 1 "On" 3 "Not-Available" ;
VAL_ 2432656679 Windshield__2_Down 2 "Error" 0 "Off" 1 "On" 3 "Not-Available" ;
VAL_ 2432656679 Turn__3_Cancel 2 "Error" 0 "Off" 1 "On" 3 "Not-Available" ;
VAL_ 2432656679 Reverse 2 "Error" 0 "Off" 1 "On" 3 "Not-Available" ;
VAL_ 2432656679 Hazard 2 "Error" 0 "Off" 1 "On" 3 "Not-Available" ;
VAL_ 2432656679 Homelink_1 2 "Error" 0 "Off" 1 "On" 3 "Not-Available" ;
VAL_ 2432656679 Windshield__1_Up 2 "Error" 0 "Off" 1 "On" 3 "Not-Available" ;
VAL_ 2432656679 Front_Brake_Switch 2 "Error" 0 "Off" 1 "On" 3 "Not-Available" ;
VAL_ 2432656679 Instrument_Cluster_Control__2 2 "Error" 0 "Off" 1 "On" 3 "Not-Available" ;
VAL_ 2432656679 Chassis_Unlock_Button_Status 2 "Error" 0 "Off" 1 "On" 3 "Not-Available" ;
VAL_ 2432656679 Power_Button 2 "Error" 0 "Off" 1 "On" 3 "Not-Available" ;
VAL_ 2432656679 RunStop_Switch 2 "Error" 0 "Off" 1 "On" 3 "Not-Available" ;
VAL_ 2432656679 Headlamp__2_High 2 "Error" 0 "Off" 1 "On" 3 "Not-Available" ;
VAL_ 2432656679 Instrument_Cluster_Control__1 2 "Error" 0 "Off" 1 "On" 3 "Not-Available" ;
VAL_ 2432656679 Clutch_Switch 2 "Error" 0 "Off" 1 "On" 3 "Not-Available" ;
VAL_ 2432656679 Start 2 "Error" 0 "Off" 1 "On" 3 "Not-Available" ;
VAL_ 2432656679 Headlamp__3_Driving 2 "Error" 0 "Off" 1 "On" 3 "Not-Available" ;
VAL_ 2432656679 Cruise__2_Set 2 "Error" 0 "Off" 1 "On" 3 "Not-Available" ;
VAL_ 2432656679 Windshield_Wiper 2 "Error" 0 "Off" 1 "On" 3 "Not-Available" ;
VAL_ 2432656679 Fog 2 "Error" 0 "Off" 1 "On" 3 "Not-Available" ;
VAL_ 2432656679 Cruise__3_Accel 2 "Error" 0 "Off" 1 "On" 3 "Not-Available" ;
VAL_ 2432656679 Horn 2 "Error" 0 "Off" 1 "On" 3 "Not-Available" ;
VAL_ 2432656679 Turn__2_Right 2 "Error" 0 "Off" 1 "On" 3 "Not-Available" ;
VAL_ 2432656679 Cruise__1_On 2 "Error" 0 "Off" 1 "On" 3 "Not-Available" ;
VAL_ 2432656679 Turn__1_Left 2 "Error" 0 "Off" 1 "On" 3 "Not-Available" ;
VAL_ 2432656679 Throttle_Safety_Switch__1 2 "Error" 0 "Off" 1 "On" 3 "Not-Available" ;
VAL_ 2432656679 Headlamp__1_Low 2 "Error" 0 "Off" 1 "On" 3 "Not-Available" ;
VAL_ 2432656679 Fuel_Door_Unlock_Button_Status 2 "Error Indicator" 3 "Not Available" 1 "Button pressed" 0 "Button not pressed" ;
VAL_ 2365523495 pModule_Control_Applied_State 1 "Partial Wakeup Applied " 0 "No Change Applied" 2 "Full Wakeup Applied" 3 "Power Down Applied " 13 "No Change - Checksum Error " 4 "Stay Awake Applied " 14 "Error State" 15 "Not Available" 5 "Alarm Activation Applied " ;
VAL_ 2365523495 pModule_Control_Command_State 3 "Power Down Requested" 2 "Full Wakeup Requested" 15 "Not Available" 14 "Error" 5 "Alarm Activation Requested" 1 "Partial Wakeup Requested" 4 "Stay Awake Requested" 0 "No Change Requested" ;
VAL_ 2365531175 pEPSReqMod 13 "13(0x0D) – EPS Assist Mode 4" 0 "0 (0x00) – Assist Off: all mosfet drivers are off, control motor is freely back driven." 11 "11(0x0B) – EPS Assist Mode 2" 10 "10(0x0A) – EPS Assist Mode 1" 12 "12(0x0C) – EPS Assist Mode 3" ;
VAL_ 2566882855 pVCMState 7 "Partial System Off, Neutral Warning" 14 "Error" 5 "Saftey Shut Off, Engine Off" 3 "Ignition On, Engine Off" 0 "System Off" 2 "Accessory" 1 "Car Finder" 15 "Not Available" 6 "Partial System Off, Hazards On" 4 " Ignition On, Engine On" ;
VAL_ 2566882855 pFog_Light_Control_Mode 3 "Auto Off" 2 "Auto On" 1 "Normal" 0 "Disabled" ;
VAL_ 2566882855 pLoadShedSts 7 "Not Available" 1 "Level 1" 0 "Level 0 " 6 "ERROR" 2 "Level 2" 3 "Level 3" ;
VAL_ 2566877479 pTemperature_Units_Selected 0 "Fahrenheit" 1 "Celsius" 3 "Not Available" 2 "Error" ;
VAL_ 2566877479 pTPMS_Learning_Status 7 "Learning Spare Tire" 3 "Learning right front" 1 "Request to start" 13 "Request to end learning process" 14 "Error failed to complete learning process" 2 "Learning left front" 0 "Not started" 5 "Learning right rear" 4 "Learning left rear" 6 "Learning processes successfully completed" 12 "Erase TPMS Sensors" 15 "Not Available" ;
VAL_ 2566877479 pPressure_Units_Selected 3 "Not Available" 1 "Kilopascal (KPa)" 2 "Error" 0 "Pounds Per Square Inch (PSI)" ;
VAL_ 2566877479 pVolume_Units_Selected 6 "Error" 1 "Liters" 0 "Gallons" 7 "Not Avialable" 2 "Imperial Gallons" ;
VAL_ 2566877479 pDisplay_Status 2 "Infotainment can override to full screen" 1 "User has requested full screen" 0 "Infotainment cannot override to full screen" 14 "Infotainment data not being shown" 15 "Not Available" ;
VAL_ 2566877479 pTime_Units_Selected 1 "24 Hour" 3 "Not Available" 0 "12 Hour" 2 "Error" ;
VAL_ 2566877479 pDistance_Units_Selected 1 "Kilometers" 0 "Miles" 3 "Not Available " 2 "Error" ;
VAL_ 2633984551 pHeated_Grip_Enable 2 "Error" 0 "Off" 1 "On" 3 "Not-Available" ;
VAL_ 2633984551 pUser_PIN_Access_Status 2 "Error" 0 "Off" 1 "On" 3 "Not-Available" ;
VAL_ 2633984551 pActive_Descent_Control_ADC_Stat 2 "Error" 0 "Off" 1 "On" 3 "Not-Available" ;
VAL_ 2633984551 pCruise_Control_Set_Status 2 "Error" 0 "Off" 1 "On" 3 "Not-Available" ;
VAL_ 2633984551 pTether_Switch_Status 2 "Error" 0 "Off" 1 "On" 3 "Not-Available" ;
VAL_ 2633984551 pHigh_Beam_Indicator_Status 2 "Error" 0 "Off" 1 "On" 3 "Not-Available" ;
VAL_ 2633984551 pLow_Fuel_Indicator_Status 2 "Error" 0 "Off" 1 "On" 3 "Not-Available" ;
VAL_ 2633984551 pSide_Stand_Status 2 "Error" 1 "Side Stand Extended" 0 "Side Stand Retracted" 3 "Not Available" ;
VAL_ 2633984551 pTurf_Mode_Requested 2 "Error" 0 "Off" 1 "On" 3 "Not-Available" ;
VAL_ 2633984551 Operator_Not_in_Operating_Statio 2 "Error" 0 "Off" 1 "On" 3 "Not-Available" ;
VAL_ 2633984551 pAWD_Mode_Requested 2 "Error" 0 "Off" 1 "On" 3 "Not-Available" ;
VAL_ 2633984551 pHeated_Grips_Up_Switch_Status 2 "Error" 0 "Off" 1 "On" 3 "Not-Available" ;
VAL_ 2633984551 pTreadle_Neutral_Status 2 "Error" 0 "Off" 1 "On" 3 "Not-Available" ;
VAL_ 2633984551 pHeated_Grips_Down_Switch_Status 2 "Error" 0 "Off" 1 "On" 3 "Not-Available" ;
VAL_ 2633984551 pPark_Brake_Indicator_Status 2 "Slow Flash (1 Hz, 50% duty cycle)" 7 "Not Available" 1 "On" 3 "Fast Flash (2 HZ or faster, 50% Duty Cycle)" 0 "Off" 6 "Error" ;
VAL_ 2633984551 pRWD_Mode_Requested 2 "Error" 0 "Off" 1 "On" 3 "Not-Available" ;
VAL_ 2633984551 pSeat_Belt_Indicator_Status 2 "Slow Flash (1 Hz, 50% duty cycle)" 7 "Not Available" 1 "On" 3 "Fast Flash (2 HZ or faster, 50% Duty Cycle)" 0 "Off" 6 "Error" ;
VAL_ 2633984551 pSecurity_Light_Immobilizer_Stat 2 "Error" 0 "Off" 1 "On" 3 "Not-Available" ;
VAL_ 2633984551 ECU_Security_Status 1 "Locked, Awaiting Unlock" 3 " Locked, system will shut down" 0 "Unlocked" 7 "Not Available" 2 "Locked, System will not shut down" 6 "Error" ;
VAL_ 2633984551 pActive_Decent_Control_ADC_Mode_ 2 "Error" 0 "Off" 1 "On" 3 "Not-Available" ;
VAL_ 2633984551 pTreadle_Reverse_Status 2 "Error" 0 "Off" 1 "On" 3 "Not-Available" ;
VAL_ 2566876711 pHydraulic_Oil_Temp_Status 0 "Error" 1 "OK" 2 "Not OK" 3 "Not Available" ;
VAL_ 2566876711 pHydraulic_Oil_Pressure_Status 0 "Error" 1 "OK" 2 "Not OK" 3 "Not Available" ;
VAL_ 2566876711 pEngine_Oil_Pressure_Status 0 "Error" 1 "OK" 2 "Not OK" 3 "Not Available" ;
VAL_ 2566883119 pRideHeightStatus 1 "Not At Target Height" 0 "At Target Height" 15 "Not Available" 2 "System in Transition" 14 "Error" ;
VAL_ 2566883119 pRideHeightSystemReadiness 1 "RPM Warning" 30 "Error" 3 "RPM and Vehicle Speed Warning" 0 "Ready to Adjust" 2 "Vehicle Speed Warning" 31 "Not Available" ;
VAL_ 2566883119 pRollTiresRequest 1 "Roll Tires" 2 "Error" 0 "No Rolling Needed" 3 "Not Available" ;
VAL_ 2566883119 pRideHeightPosition 1 "Transition to Ride Height 1" 14 "Error" 15 "Not Available" 3 "Transition to Ride Height 2" 2 "At Ride Height 2" 0 "At Ride Height 1" ;
VAL_ 2566883119 pRideHeightPumpStatus 2 "Error" 0 "Off" 1 "On" 3 "Not-Available" ;
VAL_ 2566883119 pRideHeightPumpCommandRequestSta 2 "Error" 0 "Off" 1 "On" 3 "Not-Available" ;
VAL_ 2566882102 pDriver_HeatedCooled_Seat_Enable 2 "Error" 0 "Off" 1 "On" 3 "Not-Available" ;
VAL_ 2566882102 pDriver_HeatedCooled_Seat_Down_B 2 "Error" 0 "Off" 1 "On" 3 "Not-Available" ;
VAL_ 2566882102 pPassenger_HeatedCooled_Seat_Ena 2 "Error" 0 "Off" 1 "On" 3 "Not-Available" ;
VAL_ 2566882102 pPassenger_HeatedCooled_Seat_Up_ 2 "Error" 0 "Off" 1 "On" 3 "Not-Available" ;
VAL_ 2566882102 pPassenger_HeatedCooled_Seat_Dow 2 "Error" 0 "Off" 1 "On" 3 "Not-Available" ;
VAL_ 2566882102 pDriver_HeatedCooled_Seat_Up_But 2 "Error" 0 "Off" 1 "On" 3 "Not-Available" ;
VAL_ 2432658497 Drive_Mode__4 2 "Error" 0 "Off" 1 "On" 3 "Not-Available" ;
VAL_ 2432658497 Drive_Mode__2 2 "Error" 0 "Off" 1 "On" 3 "Not-Available" ;
VAL_ 2432658497 Drivers_Net_Engagement 2 "Error" 0 "Off" 1 "On" 3 "Not-Available" ;
VAL_ 2432658497 Foot_On_Cruise_Control_Switch 2 "Error" 0 "Off" 1 "On" 3 "Not-Available" ;
VAL_ 2432658497 Drive_Mode__1 2 "Error" 0 "Off" 1 "On" 3 "Not-Available" ;
VAL_ 2432658497 Momentary_Driveline_Left_Press 2 "Error" 0 "Off" 1 "On" 3 "Not-Available" ;
VAL_ 2432658497 CylDeAc_Enable 2 "Error" 0 "Off" 1 "On" 3 "Not-Available" ;
VAL_ 2432658497 Work_Group_Lock_Switch 2 "Error" 0 "Off" 1 "On" 3 "Not-Available" ;
VAL_ 2432658497 Drivers_Seatbelt_Engagement 2 "Error" 0 "Off" 1 "On" 3 "Not-Available" ;
VAL_ 2432658497 Drive_Mode__3 2 "Error" 0 "Off" 1 "On" 3 "Not-Available" ;
VAL_ 2432658497 Work_Mode_Switch 2 "Error" 0 "Off" 1 "On" 3 "Not-Available" ;
VAL_ 2432658497 Momentary_Driveline_Right_Press 2 "Error" 0 "Off" 1 "On" 3 "Not-Available" ;
VAL_ 2432658497 PTO_Mode_Switch_RPM_Control 2 "Error" 0 "Off" 1 "On" 3 "Not-Available" ;
VAL_ 2432658497 Operator_Presence_Switch 2 "Error" 0 "Off" 1 "On" 3 "Not-Available" ;
VAL_ 2432658497 Tilt_Lock_Switch 2 "Error" 0 "Off" 1 "On" 3 "Not-Available" ;
VAL_ 2432658497 Engine_Brake_Enable 2 "Error" 0 "Off" 1 "On" 3 "Not-Available" ;
VAL_ 2432658497 Accessory_Relay 0 "Energize" 1 "De-energize" 3 "Not Available" ;
VAL_ 2432656449 Source 2 "Error" 0 "Off" 1 "On" 3 "Not-Available" ;
VAL_ 2432656449 Squelch_SQ_Up 2 "Error" 0 "Off" 1 "On" 3 "Not-Available" ;
VAL_ 2432656449 MutePreset 2 "Error" 0 "Off" 1 "On" 3 "Not-Available" ;
VAL_ 2432656449 Volume_Down 2 "Error" 0 "Off" 1 "On" 3 "Not-Available" ;
VAL_ 2432656449 Volume_Up 2 "Error" 0 "Off" 1 "On" 3 "Not-Available" ;
VAL_ 2432656449 Tune_Up 2 "Error" 0 "Off" 1 "On" 3 "Not-Available" ;
VAL_ 2432656449 Seek_Up 2 "Error" 0 "Off" 1 "On" 3 "Not-Available" ;
VAL_ 2432656449 Tune_Down 2 "Error" 0 "Off" 1 "On" 3 "Not-Available" ;
VAL_ 2432656449 Squelch_SQ_Down 2 "Error" 0 "Off" 1 "On" 3 "Not-Available" ;
VAL_ 2432656449 pInfotainment_Joystick_1 5 "Center" 3 "Left" 0 "Neutral" 2 "Down" 1 "Up" 4 "Right" ;
VAL_ 2432656449 Preset 2 "Error" 0 "Off" 1 "On" 3 "Not-Available" ;
VAL_ 2432656449 Seek_Down 2 "Error" 0 "Off" 1 "On" 3 "Not-Available" ;
VAL_ 2432656449 pInfotainment_Joystick_2 5 "Center" 3 "Left" 0 "Neutral" 2 "Down" 1 "Up" 4 "Right" ;
VAL_ 2432656449 ICOM 2 "Error" 0 "Off" 1 "On" 3 "Not-Available" ;
VAL_ 2432656449 Push_To_Talk_PTT 2 "Error" 0 "Off" 1 "On" 3 "Not-Available" ;
VAL_ 2432656449 pMultifunction_Infotainment_Inte 2 "Error" 0 "Off" 1 "On" 3 "Not-Available" ;
VAL_ 2432656449 COM 2 "Error" 0 "Off" 1 "On" 3 "Not-Available" ;
VAL_ 2432656449 PlayPause 2 "Error" 0 "Off" 1 "On" 3 "Not-Available" ;
VAL_ 2432656705 Key_Fob_Unlock_Button_Status 2 "Error" 0 "Off" 1 "On" 3 "Not-Available" ;
VAL_ 2432656705 Homelink_2 2 "Error" 0 "Off" 1 "On" 3 "Not-Available" ;
VAL_ 2432656705 Side_Stand_Switch 2 "Error" 0 "Off" 1 "On" 3 "Not-Available" ;
VAL_ 2432656705 Key_Fob_Lock_Button_Status 2 "Error" 0 "Off" 1 "On" 3 "Not-Available" ;
VAL_ 2432656705 Windshield__2_Down 2 "Error" 0 "Off" 1 "On" 3 "Not-Available" ;
VAL_ 2432656705 Turn__3_Cancel 2 "Error" 0 "Off" 1 "On" 3 "Not-Available" ;
VAL_ 2432656705 Reverse 2 "Error" 0 "Off" 1 "On" 3 "Not-Available" ;
VAL_ 2432656705 Hazard 2 "Error" 0 "Off" 1 "On" 3 "Not-Available" ;
VAL_ 2432656705 Homelink_1 2 "Error" 0 "Off" 1 "On" 3 "Not-Available" ;
VAL_ 2432656705 Windshield__1_Up 2 "Error" 0 "Off" 1 "On" 3 "Not-Available" ;
VAL_ 2432656705 Front_Brake_Switch 2 "Error" 0 "Off" 1 "On" 3 "Not-Available" ;
VAL_ 2432656705 Instrument_Cluster_Control__2 2 "Error" 0 "Off" 1 "On" 3 "Not-Available" ;
VAL_ 2432656705 Chassis_Unlock_Button_Status 2 "Error" 0 "Off" 1 "On" 3 "Not-Available" ;
VAL_ 2432656705 Power_Button 2 "Error" 0 "Off" 1 "On" 3 "Not-Available" ;
VAL_ 2432656705 RunStop_Switch 2 "Error" 0 "Off" 1 "On" 3 "Not-Available" ;
VAL_ 2432656705 Headlamp__2_High 2 "Error" 0 "Off" 1 "On" 3 "Not-Available" ;
VAL_ 2432656705 Instrument_Cluster_Control__1 2 "Error" 0 "Off" 1 "On" 3 "Not-Available" ;
VAL_ 2432656705 Clutch_Switch 2 "Error" 0 "Off" 1 "On" 3 "Not-Available" ;
VAL_ 2432656705 Start 2 "Error" 0 "Off" 1 "On" 3 "Not-Available" ;
VAL_ 2432656705 Headlamp__3_Driving 2 "Error" 0 "Off" 1 "On" 3 "Not-Available" ;
VAL_ 2432656705 Cruise__2_Set 2 "Error" 0 "Off" 1 "On" 3 "Not-Available" ;
VAL_ 2432656705 Windshield_Wiper 2 "Error" 0 "Off" 1 "On" 3 "Not-Available" ;
VAL_ 2432656705 Fog 2 "Error" 0 "Off" 1 "On" 3 "Not-Available" ;
VAL_ 2432656705 Cruise__3_Accel 2 "Error" 0 "Off" 1 "On" 3 "Not-Available" ;
VAL_ 2432656705 Horn 2 "Error" 0 "Off" 1 "On" 3 "Not-Available" ;
VAL_ 2432656705 Turn__2_Right 2 "Error" 0 "Off" 1 "On" 3 "Not-Available" ;
VAL_ 2432656705 Cruise__1_On 2 "Error" 0 "Off" 1 "On" 3 "Not-Available" ;
VAL_ 2432656705 Turn__1_Left 2 "Error" 0 "Off" 1 "On" 3 "Not-Available" ;
VAL_ 2432656705 Throttle_Safety_Switch__1 2 "Error" 0 "Off" 1 "On" 3 "Not-Available" ;
VAL_ 2432656705 Headlamp__1_Low 2 "Error" 0 "Off" 1 "On" 3 "Not-Available" ;
VAL_ 2432656705 Fuel_Door_Unlock_Button_Status 2 "Error Indicator" 3 "Not Available" 1 "Button pressed" 0 "Button not pressed" ;
VAL_ 2566877505 pTemperature_Units_Selected 0 "Fahrenheit" 1 "Celsius" 3 "Not Available" 2 "Error" ;
VAL_ 2566877505 pTPMS_Learning_Status 7 "Learning Spare Tire" 3 "Learning right front" 1 "Request to start" 13 "Request to end learning process" 14 "Error failed to complete learning process" 2 "Learning left front" 0 "Not started" 5 "Learning right rear" 4 "Learning left rear" 6 "Learning processes successfully completed" 12 "Erase TPMS Sensors" 15 "Not Available" ;
VAL_ 2566877505 pPressure_Units_Selected 3 "Not Available" 1 "Kilopascal (KPa)" 2 "Error" 0 "Pounds Per Square Inch (PSI)" ;
VAL_ 2566877505 pVolume_Units_Selected 6 "Error" 1 "Liters" 0 "Gallons" 7 "Not Avialable" 2 "Imperial Gallons" ;
VAL_ 2566877505 pDisplay_Status 2 "Infotainment can override to full screen" 1 "User has requested full screen" 0 "Infotainment cannot override to full screen" 14 "Infotainment data not being shown" 15 "Not Available" ;
VAL_ 2566877505 pTime_Units_Selected 1 "24 Hour" 3 "Not Available" 0 "12 Hour" 2 "Error" ;
VAL_ 2566877505 pDistance_Units_Selected 1 "Kilometers" 0 "Miles" 3 "Not Available " 2 "Error" ;
VAL_ 2566882113 pDriver_HeatedCooled_Seat_Enable 2 "Error" 0 "Off" 1 "On" 3 "Not-Available" ;
VAL_ 2566882113 pDriver_HeatedCooled_Seat_Down_B 2 "Error" 0 "Off" 1 "On" 3 "Not-Available" ;
VAL_ 2566882113 pPassenger_HeatedCooled_Seat_Ena 2 "Error" 0 "Off" 1 "On" 3 "Not-Available" ;
VAL_ 2566882113 pPassenger_HeatedCooled_Seat_Up_ 2 "Error" 0 "Off" 1 "On" 3 "Not-Available" ;
VAL_ 2566882113 pPassenger_HeatedCooled_Seat_Dow 2 "Error" 0 "Off" 1 "On" 3 "Not-Available" ;
VAL_ 2566882113 pDriver_HeatedCooled_Seat_Up_But 2 "Error" 0 "Off" 1 "On" 3 "Not-Available" ;
VAL_ 2365530202 pEngine_Control_Mode 14 "Error" 3 "Engine Torque Request" 2 " Engine Speed Limit" 0 "No Control Request" 15 "Not Available" 1 "Engine Speed Request" 4 "Engine Torque Limit" ;
VAL_ 2365530202 pEngine_Control_Requestor 11 "Remote Accelerator" 8 "Torque Limiting" 9 "High Speed Governor" 15 "Not available" 1 "Accelerator Pedal/Operator Selection" 4 "Road Speed Governor" 0 "Low Idle Governor/No Request" 6 "Transmission Control" 7 "ABS Control" 10 "Braking System" 2 "Cruise Control" 5 "ASR Control" 3 "PTO Governor" ;
VAL_ 2231304282 pElectric_Propulsion_Control_Uni 8 "Torque Command" 2 "Enable Command" 0 "Shutdown Command" 3 "Reserved for Active Short" 4 "Reserved for End Active Short" 9 "Speed Command" 11 "Reserved for Active Discharge" 10 "Reserved for Control Vbat" 5 "Fault Reset" 15 "No Change in state or control demand" 1 "Energize Command" ;
VAL_ 2566802010 pTransmission_Mode_5_Indicator 2 "Error" 0 "Off" 1 "On" 3 "Not-Available" ;
VAL_ 2231309146 pElectric_Propulsion_Control_Uni 8 "Torque Command" 2 "Enable Command" 0 "Shutdown Command" 3 "Reserved for Active Short" 4 "Reserved for End Active Short" 9 "Speed Command" 11 "Reserved for Active Discharge" 10 "Reserved for Control Vbat" 5 "Fault Reset" 15 "No Change in state or control demand" 1 "Energize Command" ;
VAL_ 2566844762 pOdometer_Drive_Bit 3 "Not Available " 2 "Error" 0 "State A" 1 "State B" ;
VAL_ 2566844762 pCruise_Enable_Status 14 "Error" 15 "Not Available " 0 "Not enabled. System must be enabled before it is set" 1 "Enable. System is ready to be set by operator. Only change state when system is enabled/disabled with on/off switch" ;
VAL_ 2365428314 Engine_Operating_State 1 "Pre-Start" 3 "Warm-Up" 15 "Not Available" 4 "Running" 0 "Engine Stopped" 6 "Engine Stopping" 2 "Starting" 7 "Post-Run" 5 "Cool-down" 14 "Reserved" ;
VAL_ 2231341402 Driveline_Mode 15 "Not Available" 0 "2WD" 5 "ADC2" 4 "Ultra TURF (3WD)" 14 "Error" 1 "AWD" 3 "TURF" 2 "ADC1" 6 "ADC3" ;
VAL_ 2566877311 pRadio_Input_Device 16 "AM" 8 "PANDORA" 11 "FM1" 12 "FM2" 9 "SIRIUS" 5 "NAV" 6 "MP3" 10 "FM" 15 "WX" 2 "XM" 13 "FM3" 3 "AUX" 1 "iPOD" 4 "USB" 7 "BT" 14 "FM4" 21 "ICOM" 19 "SW" 18 "MW" 20 "iHEART" 17 "LW" 22 "GMRS" 23 "CB" 33 "P3" 25 "GMRS RX" 35 "P5" 34 "P4" 32 "P2" 37 "P7" 24 "GMRS TX" 38 "P8" 31 "P1" 36 "P6" 40 "P10" 42 "P12" 45 "P15" 43 "P13" 39 "P9" 44 "P14" 41 "P11" 47 "P17" 50 "P20" 49 "P19" 46 "P16" 48 "P18" 92 "Incoming Text" 70 "BT VOL" 63 "Destination" 110 "BASS" 100 "Radio OFF" 80 "Thumbs UP" 91 "Incoming Call" 61 "Turn Left" 71 "BT VOL+" 72 "BT VOL-" 81 "Thumbs DOWN" 62 "Turn Right" 111 "TREBLE" 113 "BALANCE" 114 "AVC" 112 "MID" 115 "VOLUME (User Requested)" 116 "MUTE" 118 "AVC Compensated Volume " 123 "MID-BASS, + 1" 120 "MID-TREBLE" 121 "BASS, + 1" 119 "MID-BASS" 122 "MID-BASS, - 1" 117 "FADE" 128 "TREBLE, - 1" 127 "MID-TREBLE, + 1" 125 "MID, + 1" 124 "MID, - 1" 129 "TREBLE, + 1" 126 "MID-TREBLE, - 1" 130 "Number of User EQ Selection Bands" 135 "EQ Selection - Mid-Rear" 134 "EQ Selection - Rear" 133 "EQ Selection - Mid-Front" 131 "EQ Preset" 132 "EQ Selection - Front" 137 "Vehicle Configuration" 136 "BASS BOOST Setting" 254 "Error" 141 "Speakers Installed - Secondary" 249 "Request Setting" 255 "Not Available" 140 "Speakers Installed - Primary" ;
VAL_ 2566877311 pScreen_Area_Configuration 3 "Not Available" 1 "Expanded Screen Size" 2 "Error" 0 "Normal Screen Size" ;
VAL_ 2566877311 pStereo_Status 2 "Error" 0 "Off" 1 "On" 3 "Not-Available" ;
VAL_ 2566877311 pText_Line_Configuration 5 "5 lines of ASCII text being sent" 2 "2 lines of ASCII text being sent" 0 "0 lines of ASCII text being sent" 6 "6 lines of ASCII text being sent" 4 "4 lines of ASCII text being sent" 1 "1 lines of ASCII text being sent" 7 "Not Available" 3 "3 lines of ASCII text being sent" ;
VAL_ 2566877311 pHighlight_Row 15 "Not Available" 0 "No Row Highlighted" 14 "Error" ;
VAL_ 2566877311 pScreen_Area_Mode 0 "Normal Screen Display" 1 "Data List Being Transmitted" 7 "Not Available " 6 "Error" ;
VAL_ 2566877311 pFirst_Row_Configuration 0 "Data in SPN 524099, 524100, 524101 is ignored. First row will be in ASCII text" 7 "Not Available" 1 "Data in SPN 524099, 524100, 524101 will be shown in the first row" 2 "Data in SPN 524099, 524100, 524101 is ignored. First row will be blank. Row 2 is ASCII text" ;
VAL_ 2566877311 pRadio_Scaling_Of_SPN_524100 4 "-0.1/bit – show 1 decimal point, value is negative" 7 "Not Available" 2 "0.01/bit – show 2 decimal points" 1 "0.1/bit – show 1 decimal point" 6 "Do not show Input Value" 0 "1/bit" 5 "-0.01/bit – show 2 decimal points, value is negative" 3 "-1/bit – Value is negative" ;
